[part 1 of 6: packages /MICROSAR/Dem_swc/DataTypes to /MICROSAR/Dem_swc/ComponentTypes]
AUTOSAR XML (schema 4-2-2)
package /MICROSAR/Dem_swc/DataTypes
  26 x impl type:
    Dem_EventIdType: range raw 1..65535, implementation-data-type=uint16
    Dem_RatioIdType: range raw 1..65535, implementation-data-type=uint16
    Dem_DTCStatusMaskType: range raw 0..255, implementation-data-type=uint8
    Dem_OperationCycleIdType: range raw 0..255, implementation-data-type=uint8
    Dem_DTCGroupType: range raw 0..16777215, implementation-data-type=uint32
    Dem_MaxDataValueType: category=ARRAY, sw-calibration-access=READ-ONLY
      element Dem_MaxDataValueTypeElement: array-size=8, array-size-semantics=FIXED-SIZE, implementation-data-type=uint8
    Dem_EventStatusType:
      compu {0=DEM_EVENT_STATUS_PASSED, 1=DEM_EVENT_STATUS_FAILED, 2=DEM_EVENT_STATUS_PREPASSED, 3=DEM_EVENT_STATUS_PREFAILED, 4=DEM_EVENT_STATUS_FDC_THRESHOLD_REACHED, 5=DEM_EVENT_STATUS_PASSED_CONDITIONS_NOT_FULFILLED, 6=DEM_EVENT_STATUS_FAILED_CONDITIONS_NOT_FULFILLED, 7=DEM_EVENT_STATUS_PREPASSED_CONDITIONS_NOT_FULFILLED, 8=DEM_EVENT_STATUS_PREFAILED_CONDITIONS_NOT_FULFILLED}
      range raw 0..255
      implementation-data-type=uint8
    Dem_DTCKindType: compu {1=DEM_DTC_KIND_ALL_DTCS, 2=DEM_DTC_KIND_EMISSION_REL_DTCS}, range raw 0..255, implementation-data-type=uint8
    Dem_IumprDenomCondStatusType: compu {0=DEM_IUMPR_DEN_STATUS_NOT_REACHED, 1=DEM_IUMPR_DEN_STATUS_REACHED, 2=DEM_IUMPR_DEN_STATUS_INHIBITED}, range raw 0..255, implementation-data-type=uint8
    Dem_DebounceResetStatusType: compu {0=DEM_DEBOUNCE_STATUS_FREEZE, 1=DEM_DEBOUNCE_STATUS_RESET}, range raw 0..255, implementation-data-type=uint8
    Dem_IumprReadinessGroupType:
      compu {0=DEM_IUMPR_BOOSTPRS, 1=DEM_IUMPR_CAT1, 2=DEM_IUMPR_CAT2, 3=DEM_IUMPR_EGR, 4=DEM_IUMPR_EGSENSOR, 5=DEM_IUMPR_EVAP, 6=DEM_IUMPR_NMHCCAT, 7=DEM_IUMPR_NOXADSORB, 8=DEM_IUMPR_NOXCAT, 9=DEM_IUMPR_OXS1, 10=DEM_IUMPR_OXS2, 11=DEM_IUMPR_PMFILTER, 12=DEM_IUMPR_PRIVATE, 13=DEM_IUMPR_SAIR, 14=DEM_IUMPR_SECOXS1, 15=DEM_IUMPR_SECOXS2, 16=DEM_IUMPR_FLSYS, 17=DEM_IUMPR_AFRI1, 18=DEM_IUMPR_AFRI2, 19=DEM_IUMPR_PF1, 20=DEM_IUMPR_PF2, 255=DEM_IUMPR_ALLGROUPS}
      range raw 0..255
      implementation-data-type=uint8
    Dem_DTRControlType: compu {0=DEM_DTR_CTL_NORMAL, 1=DEM_DTR_CTL_NO_MAX, 2=DEM_DTR_CTL_NO_MIN, 3=DEM_DTR_CTL_RESET, 4=DEM_DTR_CTL_INVISIBLE}, range raw 0..255, implementation-data-type=uint8
    Dem_DebouncingStateType:
      compu {mask 1: 1=DEM_TEMPORARILY_DEFECTIVE (Bit 0: Temporarily Defective (corresponds to 0 < FDC < 127)), mask 2: 2=DEM_FINALLY_DEFECTIVE (Bit 1: Finally Defective (corresponds to FDC = 127)), mask 4: 4=DEM_TEMPORARILY_HEALED (Bit 2: Temporarily healed (corresponds to -128 < FDC < 0)), mask 8: 8=DEM_TEST_COMPLETE (Bit 3: Test complete (corresponds to FDC = -128 or FDC = 127)), mask 16: 16=DEM_DTR_UPDATE (Bit 4: DTR Update (= Test complete && Debouncing complete && enable conditions / storage conditions fulfilled))}
      range raw 0..255
      implementation-data-type=uint8
    Dem_DTCSeverityType:
      compu {mask 255: 0=DEM_SEVERITY_NO_SEVERITY (DTC_NO_SEVERITY) (No severity information available), mask 31: 1=DEM_SEVERITY_WWHOBD_CLASS_NO_CLASS (DTC_CLASS) (No class information), mask 31: 2=DEM_SEVERITY_WWHOBD_CLASS_A (DTC_CLASS) (WWH-OBD Class A), mask 31: 4=DEM_SEVERITY_WWHOBD_CLASS_B1 (DTC_CLASS) (WWH-OBD Class B1), mask 31: 8=DEM_SEVERITY_WWHOBD_CLASS_B2 (DTC_CLASS) (WWH-OBD Class B2), mask 31: 16=DEM_SEVERITY_WWHOBD_CLASS_C (DTC_CLASS) (WWH-OBD Class C), mask 224: 32=DEM_SEVERITY_MAINTENANCE_ONLY (DTC_SEVERITY) (Maintenance required), mask 224: 64=DEM_SEVERITY_CHECK_AT_NEXT_HALT (DTC_SEVERITY) (Check at next halt), mask 224: 128=DEM_SEVERITY_CHECK_IMMEDIATELY (DTC_SEVERITY) (Check immediately)}
      range raw 0..255
      implementation-data-type=uint8
    Dem_UdsStatusByteType:
      compu {mask 1: 1=DEM_UDS_STATUS_TF (bit 0: TestFailed), mask 2: 2=DEM_UDS_STATUS_TFTOC (bit 1: TestFailedThisOperationCycle), mask 4: 4=DEM_UDS_STATUS_PDTC (bit 2: PendingDTC), mask 8: 8=DEM_UDS_STATUS_CDTC (bit 3: ConfirmedDTC), mask 16: 16=DEM_UDS_STATUS_TNCSLC (bit 4: TestNotCompletedSinceLastClear), mask 32: 32=DEM_UDS_STATUS_TFSLC (bit 5: TestFailedSinceLastClear), mask 64: 64=DEM_UDS_STATUS_TNCTOC (bit 6: TestNotCompletedThisOperationCycle), mask 128: 128=DEM_UDS_STATUS_WIR (bit 7: WarningIndicatorRequested)}
      range raw 0..255
      implementation-data-type=uint8
    Dem_MonitorStatusType: compu {mask 1: 1=DEM_MONITOR_STATUS_TF (bit 0: TestFailed), mask 2: 2=DEM_MONITOR_STATUS_TNCTOC (bit 1: TestNotCompletedThisOperationCycle)}, range raw 0..255, implementation-data-type=uint8
    DataArrayType_uint8_1: category=ARRAY, sw-calibration-access=READ-ONLY
      element DataArrayType_uint8_1Element: array-size=1, array-size-semantics=FIXED-SIZE, implementation-data-type=uint8
    DataArrayType_uint8_2: category=ARRAY, sw-calibration-access=READ-ONLY
      element DataArrayType_uint8_2Element: array-size=2, array-size-semantics=FIXED-SIZE, implementation-data-type=uint8
    DataArrayType_uint8_4: category=ARRAY, sw-calibration-access=READ-ONLY
      element DataArrayType_uint8_4Element: array-size=4, array-size-semantics=FIXED-SIZE, implementation-data-type=uint8
    DataArrayType_uint8_3: category=ARRAY, sw-calibration-access=READ-ONLY
      element DataArrayType_uint8_3Element: array-size=3, array-size-semantics=FIXED-SIZE, implementation-data-type=uint8
    Dem_InitMonitorReasonType: compu {1=DEM_INIT_MONITOR_CLEAR, 2=DEM_INIT_MONITOR_RESTART, 3=DEM_INIT_MONITOR_REENABLED, 4=DEM_INIT_MONITOR_STORAGE_REENABLED}, range raw 1..4, implementation-data-type=uint8
    Dem_DTCOriginType:
      compu {1=DEM_DTC_ORIGIN_PRIMARY_MEMORY, 2=DEM_DTC_ORIGIN_MIRROR_MEMORY, 3=DEM_DTC_ORIGIN_PERMANENT_MEMORY, 4=DEM_DTC_ORIGIN_OBD_RELEVANT_MEMORY, 5=DEM_DTC_ORIGIN_SECONDARY_MEMORY, 5=DEM_DTC_ORIGIN_USERDEFINED_MEMORY_10, 5=DEM_DTC_ORIGIN_USERDEFINED_MEMORY_11, 5=DEM_DTC_ORIGIN_USERDEFINED_MEMORY_12, 5=DEM_DTC_ORIGIN_USERDEFINED_MEMORY_13, 5=DEM_DTC_ORIGIN_USERDEFINED_MEMORY_14, 5=DEM_DTC_ORIGIN_USERDEFINED_MEMORY_15, 5=DEM_DTC_ORIGIN_USERDEFINED_MEMORY_16, 5=DEM_DTC_ORIGIN_USERDEFINED_MEMORY_17, 5=DEM_DTC_ORIGIN_USERDEFINED_MEMORY_18, 5=DEM_DTC_ORIGIN_USERDEFINED_MEMORY_19, 5=DEM_DTC_ORIGIN_USERDEFINED_MEMORY_1A, 5=DEM_DTC_ORIGIN_USERDEFINED_MEMORY_1B, 5=DEM_DTC_ORIGIN_USERDEFINED_MEMORY_1C, 5=DEM_DTC_ORIGIN_USERDEFINED_MEMORY_1D, 5=DEM_DTC_ORIGIN_USERDEFINED_MEMORY_1E, 5=DEM_DTC_ORIGIN_USERDEFINED_MEMORY_1F, 5=DEM_DTC_ORIGIN_USERDEFINED_MEMORY_20, 5=DEM_DTC_ORIGIN_USERDEFINED_MEMORY_21, 5=DEM_DTC_ORIGIN_USERDEFINED_MEMORY_22, 5=DEM_DTC_ORIGIN_USERDEFINED_MEMORY_23, 5=DEM_DTC_ORIGIN_USERDEFINED_MEMORY_24, 5=DEM_DTC_ORIGIN_USERDEFINED_MEMORY_25, 5=DEM_DTC_ORIGIN_USERDEFINED_MEMORY_26, 5=DEM_DTC_ORIGIN_USERDEFINED_MEMORY_27, 5=DEM_DTC_ORIGIN_USERDEFINED_MEMORY_28, 5=DEM_DTC_ORIGIN_USERDEFINED_MEMORY_29, 5=DEM_DTC_ORIGIN_USERDEFINED_MEMORY_2A, 5=DEM_DTC_ORIGIN_USERDEFINED_MEMORY_2B, 5=DEM_DTC_ORIGIN_USERDEFINED_MEMORY_2C, 5=DEM_DTC_ORIGIN_USERDEFINED_MEMORY_2D, 5=DEM_DTC_ORIGIN_USERDEFINED_MEMORY_2E, 5=DEM_DTC_ORIGIN_USERDEFINED_MEMORY_2F, 5=DEM_DTC_ORIGIN_USERDEFINED_MEMORY_30, 5=DEM_DTC_ORIGIN_USERDEFINED_MEMORY_31, 5=DEM_DTC_ORIGIN_USERDEFINED_MEMORY_32, 5=DEM_DTC_ORIGIN_USERDEFINED_MEMORY_33, 5=DEM_DTC_ORIGIN_USERDEFINED_MEMORY_34, 5=DEM_DTC_ORIGIN_USERDEFINED_MEMORY_35, 5=DEM_DTC_ORIGIN_USERDEFINED_MEMORY_36, 5=DEM_DTC_ORIGIN_USERDEFINED_MEMORY_37, 5=DEM_DTC_ORIGIN_USERDEFINED_MEMORY_38, 5=DEM_DTC_ORIGIN_USERDEFINED_MEMORY_39, 5=DEM_DTC_ORIGIN_USERDEFINED_MEMORY_3A, 5=DEM_DTC_ORIGIN_USERDEFINED_MEMORY_3B, 5=DEM_DTC_ORIGIN_USERDEFINED_MEMORY_3C, 5=DEM_DTC_ORIGIN_USERDEFINED_MEMORY_3D, 5=DEM_DTC_ORIGIN_USERDEFINED_MEMORY_3E, 5=DEM_DTC_ORIGIN_USERDEFINED_MEMORY_3F, 5=DEM_DTC_ORIGIN_USERDEFINED_MEMORY_40, 5=DEM_DTC_ORIGIN_USERDEFINED_MEMORY_41, 5=DEM_DTC_ORIGIN_USERDEFINED_MEMORY_42, 5=DEM_DTC_ORIGIN_USERDEFINED_MEMORY_43, 5=DEM_DTC_ORIGIN_USERDEFINED_MEMORY_44, 5=DEM_DTC_ORIGIN_USERDEFINED_MEMORY_45, 5=DEM_DTC_ORIGIN_USERDEFINED_MEMORY_46, 5=DEM_DTC_ORIGIN_USERDEFINED_MEMORY_47, 5=DEM_DTC_ORIGIN_USERDEFINED_MEMORY_48, 5=DEM_DTC_ORIGIN_USERDEFINED_MEMORY_49, 5=DEM_DTC_ORIGIN_USERDEFINED_MEMORY_4A, 5=DEM_DTC_ORIGIN_USERDEFINED_MEMORY_4B, 5=DEM_DTC_ORIGIN_USERDEFINED_MEMORY_4C, 5=DEM_DTC_ORIGIN_USERDEFINED_MEMORY_4D, 5=DEM_DTC_ORIGIN_USERDEFINED_MEMORY_4E, 5=DEM_DTC_ORIGIN_USERDEFINED_MEMORY_4F, 5=DEM_DTC_ORIGIN_USERDEFINED_MEMORY_50, 5=DEM_DTC_ORIGIN_USERDEFINED_MEMORY_51, 5=DEM_DTC_ORIGIN_USERDEFINED_MEMORY_52, 5=DEM_DTC_ORIGIN_USERDEFINED_MEMORY_53, 5=DEM_DTC_ORIGIN_USERDEFINED_MEMORY_54, 5=DEM_DTC_ORIGIN_USERDEFINED_MEMORY_55, 5=DEM_DTC_ORIGIN_USERDEFINED_MEMORY_56, 5=DEM_DTC_ORIGIN_USERDEFINED_MEMORY_57, 5=DEM_DTC_ORIGIN_USERDEFINED_MEMORY_58, 5=DEM_DTC_ORIGIN_USERDEFINED_MEMORY_59, 5=DEM_DTC_ORIGIN_USERDEFINED_MEMORY_5A, 5=DEM_DTC_ORIGIN_USERDEFINED_MEMORY_5B, 5=DEM_DTC_ORIGIN_USERDEFINED_MEMORY_5C, 5=DEM_DTC_ORIGIN_USERDEFINED_MEMORY_5D, 5=DEM_DTC_ORIGIN_USERDEFINED_MEMORY_5E, 5=DEM_DTC_ORIGIN_USERDEFINED_MEMORY_5F, 5=DEM_DTC_ORIGIN_USERDEFINED_MEMORY_60, 5=DEM_DTC_ORIGIN_USERDEFINED_MEMORY_61, 5=DEM_DTC_ORIGIN_USERDEFINED_MEMORY_62, 5=DEM_DTC_ORIGIN_USERDEFINED_MEMORY_63, 5=DEM_DTC_ORIGIN_USERDEFINED_MEMORY_64, 5=DEM_DTC_ORIGIN_USERDEFINED_MEMORY_65, 5=DEM_DTC_ORIGIN_USERDEFINED_MEMORY_66, 5=DEM_DTC_ORIGIN_USERDEFINED_MEMORY_67, 5=DEM_DTC_ORIGIN_USERDEFINED_MEMORY_68, 5=DEM_DTC_ORIGIN_USERDEFINED_MEMORY_69, 5=DEM_DTC_ORIGIN_USERDEFINED_MEMORY_6A, 5=DEM_DTC_ORIGIN_USERDEFINED_MEMORY_6B, 5=DEM_DTC_ORIGIN_USERDEFINED_MEMORY_6C, 5=DEM_DTC_ORIGIN_USERDEFINED_MEMORY_6D, 5=DEM_DTC_ORIGIN_USERDEFINED_MEMORY_6E, 5=DEM_DTC_ORIGIN_USERDEFINED_MEMORY_6F, 5=DEM_DTC_ORIGIN_USERDEFINED_MEMORY_70, 5=DEM_DTC_ORIGIN_USERDEFINED_MEMORY_71, 5=DEM_DTC_ORIGIN_USERDEFINED_MEMORY_72, 5=DEM_DTC_ORIGIN_USERDEFINED_MEMORY_73, 5=DEM_DTC_ORIGIN_USERDEFINED_MEMORY_74, 5=DEM_DTC_ORIGIN_USERDEFINED_MEMORY_75, 5=DEM_DTC_ORIGIN_USERDEFINED_MEMORY_76, 5=DEM_DTC_ORIGIN_USERDEFINED_MEMORY_77, 5=DEM_DTC_ORIGIN_USERDEFINED_MEMORY_78, 5=DEM_DTC_ORIGIN_USERDEFINED_MEMORY_79, 5=DEM_DTC_ORIGIN_USERDEFINED_MEMORY_7A, 5=DEM_DTC_ORIGIN_USERDEFINED_MEMORY_7B, 5=DEM_DTC_ORIGIN_USERDEFINED_MEMORY_7C, 5=DEM_DTC_ORIGIN_USERDEFINED_MEMORY_7D, 5=DEM_DTC_ORIGIN_USERDEFINED_MEMORY_7E, 5=DEM_DTC_ORIGIN_USERDEFINED_MEMORY_7F, 5=DEM_DTC_ORIGIN_USERDEFINED_MEMORY_80, 5=DEM_DTC_ORIGIN_USERDEFINED_MEMORY_81, 5=DEM_DTC_ORIGIN_USERDEFINED_MEMORY_82, 5=DEM_DTC_ORIGIN_USERDEFINED_MEMORY_83, 5=DEM_DTC_ORIGIN_USERDEFINED_MEMORY_84, 5=DEM_DTC_ORIGIN_USERDEFINED_MEMORY_85, 5=DEM_DTC_ORIGIN_USERDEFINED_MEMORY_86, 5=DEM_DTC_ORIGIN_USERDEFINED_MEMORY_87, 5=DEM_DTC_ORIGIN_USERDEFINED_MEMORY_88, 5=DEM_DTC_ORIGIN_USERDEFINED_MEMORY_89, 5=DEM_DTC_ORIGIN_USERDEFINED_MEMORY_8A, 5=DEM_DTC_ORIGIN_USERDEFINED_MEMORY_8B, 5=DEM_DTC_ORIGIN_USERDEFINED_MEMORY_8C, 5=DEM_DTC_ORIGIN_USERDEFINED_MEMORY_8D, 5=DEM_DTC_ORIGIN_USERDEFINED_MEMORY_8E, 5=DEM_DTC_ORIGIN_USERDEFINED_MEMORY_8F, 5=DEM_DTC_ORIGIN_USERDEFINED_MEMORY_90, 5=DEM_DTC_ORIGIN_USERDEFINED_MEMORY_91, 5=DEM_DTC_ORIGIN_USERDEFINED_MEMORY_92, 5=DEM_DTC_ORIGIN_USERDEFINED_MEMORY_93, 5=DEM_DTC_ORIGIN_USERDEFINED_MEMORY_94, 5=DEM_DTC_ORIGIN_USERDEFINED_MEMORY_95, 5=DEM_DTC_ORIGIN_USERDEFINED_MEMORY_96, 5=DEM_DTC_ORIGIN_USERDEFINED_MEMORY_97, 5=DEM_DTC_ORIGIN_USERDEFINED_MEMORY_98, 5=DEM_DTC_ORIGIN_USERDEFINED_MEMORY_99, 5=DEM_DTC_ORIGIN_USERDEFINED_MEMORY_9A, 5=DEM_DTC_ORIGIN_USERDEFINED_MEMORY_9B, 5=DEM_DTC_ORIGIN_USERDEFINED_MEMORY_9C, 5=DEM_DTC_ORIGIN_USERDEFINED_MEMORY_9D, 5=DEM_DTC_ORIGIN_USERDEFINED_MEMORY_9E, 5=DEM_DTC_ORIGIN_USERDEFINED_MEMORY_9F, 5=DEM_DTC_ORIGIN_USERDEFINED_MEMORY_A0, 5=DEM_DTC_ORIGIN_USERDEFINED_MEMORY_A1, 5=DEM_DTC_ORIGIN_USERDEFINED_MEMORY_A2, 5=DEM_DTC_ORIGIN_USERDEFINED_MEMORY_A3, 5=DEM_DTC_ORIGIN_USERDEFINED_MEMORY_A4, 5=DEM_DTC_ORIGIN_USERDEFINED_MEMORY_A5, 5=DEM_DTC_ORIGIN_USERDEFINED_MEMORY_A6, 5=DEM_DTC_ORIGIN_USERDEFINED_MEMORY_A7, 5=DEM_DTC_ORIGIN_USERDEFINED_MEMORY_A8, 5=DEM_DTC_ORIGIN_USERDEFINED_MEMORY_A9, 5=DEM_DTC_ORIGIN_USERDEFINED_MEMORY_AA, 5=DEM_DTC_ORIGIN_USERDEFINED_MEMORY_AB, 5=DEM_DTC_ORIGIN_USERDEFINED_MEMORY_AC, 5=DEM_DTC_ORIGIN_USERDEFINED_MEMORY_AD, 5=DEM_DTC_ORIGIN_USERDEFINED_MEMORY_AE, 5=DEM_DTC_ORIGIN_USERDEFINED_MEMORY_AF, 5=DEM_DTC_ORIGIN_USERDEFINED_MEMORY_B0, 5=DEM_DTC_ORIGIN_USERDEFINED_MEMORY_B1, 5=DEM_DTC_ORIGIN_USERDEFINED_MEMORY_B2, 5=DEM_DTC_ORIGIN_USERDEFINED_MEMORY_B3, 5=DEM_DTC_ORIGIN_USERDEFINED_MEMORY_B4, 5=DEM_DTC_ORIGIN_USERDEFINED_MEMORY_B5, 5=DEM_DTC_ORIGIN_USERDEFINED_MEMORY_B6, 5=DEM_DTC_ORIGIN_USERDEFINED_MEMORY_B7, 5=DEM_DTC_ORIGIN_USERDEFINED_MEMORY_B8, 5=DEM_DTC_ORIGIN_USERDEFINED_MEMORY_B9, 5=DEM_DTC_ORIGIN_USERDEFINED_MEMORY_BA, 5=DEM_DTC_ORIGIN_USERDEFINED_MEMORY_BB, 5=DEM_DTC_ORIGIN_USERDEFINED_MEMORY_BC, 5=DEM_DTC_ORIGIN_USERDEFINED_MEMORY_BD, 5=DEM_DTC_ORIGIN_USERDEFINED_MEMORY_BE, 5=DEM_DTC_ORIGIN_USERDEFINED_MEMORY_BF, 5=DEM_DTC_ORIGIN_USERDEFINED_MEMORY_C0, 5=DEM_DTC_ORIGIN_USERDEFINED_MEMORY_C1, 5=DEM_DTC_ORIGIN_USERDEFINED_MEMORY_C2, 5=DEM_DTC_ORIGIN_USERDEFINED_MEMORY_C3, 5=DEM_DTC_ORIGIN_USERDEFINED_MEMORY_C4, 5=DEM_DTC_ORIGIN_USERDEFINED_MEMORY_C5, 5=DEM_DTC_ORIGIN_USERDEFINED_MEMORY_C6, 5=DEM_DTC_ORIGIN_USERDEFINED_MEMORY_C7, 5=DEM_DTC_ORIGIN_USERDEFINED_MEMORY_C8, 5=DEM_DTC_ORIGIN_USERDEFINED_MEMORY_C9, 5=DEM_DTC_ORIGIN_USERDEFINED_MEMORY_CA, 5=DEM_DTC_ORIGIN_USERDEFINED_MEMORY_CB, 5=DEM_DTC_ORIGIN_USERDEFINED_MEMORY_CC, 5=DEM_DTC_ORIGIN_USERDEFINED_MEMORY_CD, 5=DEM_DTC_ORIGIN_USERDEFINED_MEMORY_CE, 5=DEM_DTC_ORIGIN_USERDEFINED_MEMORY_CF, 5=DEM_DTC_ORIGIN_USERDEFINED_MEMORY_D0, 5=DEM_DTC_ORIGIN_USERDEFINED_MEMORY_D1, 5=DEM_DTC_ORIGIN_USERDEFINED_MEMORY_D2, 5=DEM_DTC_ORIGIN_USERDEFINED_MEMORY_D3, 5=DEM_DTC_ORIGIN_USERDEFINED_MEMORY_D4, 5=DEM_DTC_ORIGIN_USERDEFINED_MEMORY_D5, 5=DEM_DTC_ORIGIN_USERDEFINED_MEMORY_D6, 5=DEM_DTC_ORIGIN_USERDEFINED_MEMORY_D7, 5=DEM_DTC_ORIGIN_USERDEFINED_MEMORY_D8, 5=DEM_DTC_ORIGIN_USERDEFINED_MEMORY_D9, 5=DEM_DTC_ORIGIN_USERDEFINED_MEMORY_DA, 5=DEM_DTC_ORIGIN_USERDEFINED_MEMORY_DB, 5=DEM_DTC_ORIGIN_USERDEFINED_MEMORY_DC, 5=DEM_DTC_ORIGIN_USERDEFINED_MEMORY_DD, 5=DEM_DTC_ORIGIN_USERDEFINED_MEMORY_DE, 5=DEM_DTC_ORIGIN_USERDEFINED_MEMORY_DF, 5=DEM_DTC_ORIGIN_USERDEFINED_MEMORY_E0, 5=DEM_DTC_ORIGIN_USERDEFINED_MEMORY_E1, 5=DEM_DTC_ORIGIN_USERDEFINED_MEMORY_E2, 5=DEM_DTC_ORIGIN_USERDEFINED_MEMORY_E3, 5=DEM_DTC_ORIGIN_USERDEFINED_MEMORY_E4, 5=DEM_DTC_ORIGIN_USERDEFINED_MEMORY_E5, 5=DEM_DTC_ORIGIN_USERDEFINED_MEMORY_E6, 5=DEM_DTC_ORIGIN_USERDEFINED_MEMORY_E7, 5=DEM_DTC_ORIGIN_USERDEFINED_MEMORY_E8, 5=DEM_DTC_ORIGIN_USERDEFINED_MEMORY_E9, 5=DEM_DTC_ORIGIN_USERDEFINED_MEMORY_EA, 5=DEM_DTC_ORIGIN_USERDEFINED_MEMORY_EB, 5=DEM_DTC_ORIGIN_USERDEFINED_MEMORY_EC, 5=DEM_DTC_ORIGIN_USERDEFINED_MEMORY_ED, 5=DEM_DTC_ORIGIN_USERDEFINED_MEMORY_EE, 5=DEM_DTC_ORIGIN_USERDEFINED_MEMORY_EF, 5=DEM_DTC_ORIGIN_USERDEFINED_MEMORY_F0, 5=DEM_DTC_ORIGIN_USERDEFINED_MEMORY_F1, 5=DEM_DTC_ORIGIN_USERDEFINED_MEMORY_F2, 5=DEM_DTC_ORIGIN_USERDEFINED_MEMORY_F3, 5=DEM_DTC_ORIGIN_USERDEFINED_MEMORY_F4, 5=DEM_DTC_ORIGIN_USERDEFINED_MEMORY_F5, 5=DEM_DTC_ORIGIN_USERDEFINED_MEMORY_F6, 5=DEM_DTC_ORIGIN_USERDEFINED_MEMORY_F7, 5=DEM_DTC_ORIGIN_USERDEFINED_MEMORY_F8, 5=DEM_DTC_ORIGIN_USERDEFINED_MEMORY_F9, 5=DEM_DTC_ORIGIN_USERDEFINED_MEMORY_FA, 5=DEM_DTC_ORIGIN_USERDEFINED_MEMORY_FB, 5=DEM_DTC_ORIGIN_USERDEFINED_MEMORY_FC, 5=DEM_DTC_ORIGIN_USERDEFINED_MEMORY_FD, 5=DEM_DTC_ORIGIN_USERDEFINED_MEMORY_FE, 5=DEM_DTC_ORIGIN_USERDEFINED_MEMORY_FF}
      range raw 1..511
      implementation-data-type=uint16
    Dem_DTCFormatType: compu {0=DEM_DTC_FORMAT_OBD, 1=DEM_DTC_FORMAT_UDS, 2=DEM_DTC_FORMAT_J1939}, range raw 0..2, implementation-data-type=uint8
    Dem_OperationCycleStateType: compu {0=DEM_CYCLE_STATE_START, 1=DEM_CYCLE_STATE_END}, range raw 0..1, implementation-data-type=uint8
    Dem_IndicatorStatusType: compu {0=DEM_INDICATOR_OFF, 1=DEM_INDICATOR_CONTINUOUS, 2=DEM_INDICATOR_BLINKING, 3=DEM_INDICATOR_BLINK_CONT, 4=DEM_INDICATOR_SLOW_FLASH, 5=DEM_INDICATOR_FAST_FLASH, 6=DEM_INDICATOR_ON_DEMAND, 7=DEM_INDICATOR_SHORT}, range raw 0..7, implementation-data-type=uint8
    Dem_IumprDenomCondIdType: compu {1=DEM_IUMPR_GENERAL_DENOMINATOR, 2=DEM_IUMPR_DEN_COND_COLDSTART, 3=DEM_IUMPR_DEN_COND_EVAP, 4=DEM_IUMPR_DEN_COND_500MI, 5=DEM_IUMPR_GENERAL_INDIVIDUAL_DENOMINATOR, 6=DEM_IUMPR_GENERAL_OBDCOND, 7=DEM_IUMPR_DEN_COND_INDEPENDENT}, range raw 0..255, implementation-data-type=uint8
package /MICROSAR/Dem_swc/Interfaces
  83 x client server interface, all with is-service=true, service-kind=DIAGNOSTIC-EVENT-MANAGER:
    DemServices
      operation GetPostRunRequested: possible-error=DemServices/E_NOT_OK
        arg IsRequested: type=boolean, direction=OUT
      operation GetDTCStatusAvailabilityMask: possible-error=DemServices/E_NOT_OK
        arg ClientId: type=uint8, direction=IN
        arg DTCStatusMask: type=uint8, direction=OUT
      error E_NOT_OK: error-code=1
    CallbackInitMonitorForEvent
      operation InitMonitorForEvent: possible-error=CallbackInitMonitorForEvent/E_NOT_OK
        arg InitMonitorReason: type=Dem_InitMonitorReasonType, direction=IN
      error E_NOT_OK: error-code=1
    ClearDTC
      operation ClearDTC: possible-error=[ClearDTC/E_NOT_OK, DEM_CLEAR_FAILED, DEM_PENDING, DEM_CLEAR_BUSY, DEM_CLEAR_MEMORY_ERROR, DEM_WRONG_DTC, DEM_WRONG_DTCORIGIN]
      operation SelectDTC: possible-error=[ClearDTC/E_OK, ClearDTC/E_NOT_OK]
        arg DTC: type=uint32, direction=IN
        arg DTCFormat: type=Dem_DTCFormatType, direction=IN
        arg DTCOrigin: type=Dem_DTCOriginType, direction=IN
      8 x error:
        E_OK: error-code=0
        E_NOT_OK: error-code=1
        DEM_CLEAR_FAILED: error-code=7
        DEM_PENDING: error-code=4
        DEM_CLEAR_BUSY: error-code=5
        DEM_CLEAR_MEMORY_ERROR: error-code=6
        DEM_WRONG_DTC: error-code=8
        DEM_WRONG_DTCORIGIN: error-code=9
    EnableCondition
      operation SetEnableCondition: possible-error=EnableCondition/E_NOT_OK
        arg ConditionFulfilled: type=boolean, direction=IN
      error E_NOT_OK: error-code=1
    IndicatorStatus
      operation GetIndicatorStatus: possible-error=IndicatorStatus/E_NOT_OK
        arg IndicatorStatus: type=Dem_IndicatorStatusType, direction=OUT
      error E_NOT_OK: error-code=1
    EvMemOverflowIndication
      operation GetEventMemoryOverflow: possible-error=EvMemOverflowIndication/E_NOT_OK
        arg OverflowIndication: type=boolean, direction=OUT
      operation GetNumberOfEventMemoryEntries: possible-error=EvMemOverflowIndication/E_NOT_OK
        arg NumberOfEventMemoryEntries: type=uint8, direction=OUT
      error E_NOT_OK: error-code=1
    GeneralDiagnosticInfo
      11 x operation:
        GetEventUdsStatus: possible-error=GeneralDiagnosticInfo/E_NOT_OK
          arg EventId: type=Dem_EventIdType, direction=IN
          arg UDSStatusByte: type=Dem_UdsStatusByteType, direction=OUT
        GetEventStatus: possible-error=GeneralDiagnosticInfo/E_NOT_OK
          arg EventId: type=Dem_EventIdType, direction=IN
          arg UDSStatusByte: type=Dem_UdsStatusByteType, direction=OUT
        GetEventFailed: possible-error=GeneralDiagnosticInfo/E_NOT_OK
          arg EventId: type=Dem_EventIdType, direction=IN
          arg EventFailed: type=boolean, direction=OUT
        GetEventTested: possible-error=GeneralDiagnosticInfo/E_NOT_OK
          arg EventId: type=Dem_EventIdType, direction=IN
          arg EventTested: type=boolean, direction=OUT
        GetDTCOfEvent: possible-error=[GeneralDiagnosticInfo/E_NOT_OK, GeneralDiagnosticInfo/DEM_E_NO_DTC_AVAILABLE]
          arg EventId: type=Dem_EventIdType, direction=IN
          arg DTCFormat: type=Dem_DTCFormatType, direction=IN
          arg DTCOfEvent: type=uint32, direction=OUT
        GetFaultDetectionCounter: possible-error=[GeneralDiagnosticInfo/E_NOT_OK, GeneralDiagnosticInfo/DEM_E_NO_FDC_AVAILABLE]
          arg EventId: type=Dem_EventIdType, direction=IN
          arg FaultDetectionCounter: type=sint8, direction=OUT
        GetEventFreezeFrameDataEx: possible-error=[GeneralDiagnosticInfo/E_NOT_OK, GeneralDiagnosticInfo/DEM_BUFFER_TOO_SMALL, GeneralDiagnosticInfo/DEM_NO_SUCH_ELEMENT]
          5 x arg:
            EventId: type=Dem_EventIdType, direction=IN
            RecordNumber: type=uint8, direction=IN
            DataId: type=uint16, direction=IN
            DestBuffer: type=Dem_MaxDataValueType, direction=OUT
            BufSize: type=uint16, direction=INOUT
        GetEventExtendedDataRecordEx: possible-error=[GeneralDiagnosticInfo/E_NOT_OK, GeneralDiagnosticInfo/DEM_BUFFER_TOO_SMALL, GeneralDiagnosticInfo/DEM_NO_SUCH_ELEMENT]
          4 x arg:
            EventId: type=Dem_EventIdType, direction=IN
            RecordNumber: type=uint8, direction=IN
            DestBuffer: type=Dem_MaxDataValueType, direction=OUT
            BufSize: type=uint16, direction=INOUT
        GetEventEnableCondition: possible-error=GeneralDiagnosticInfo/E_NOT_OK
          arg EventId: type=Dem_EventIdType, direction=IN
          arg ConditionFullfilled: type=boolean, direction=OUT
        GetDebouncingOfEvent: possible-error=GeneralDiagnosticInfo/E_NOT_OK
          arg EventId: type=Dem_EventIdType, direction=IN
          arg DebouncingState: type=Dem_DebouncingStateType, direction=OUT
        GetMonitorStatus: possible-error=GeneralDiagnosticInfo/E_NOT_OK
          arg EventId: type=Dem_EventIdType, direction=IN
          arg MonitorStatus: type=Dem_MonitorStatusType, direction=OUT
      5 x error:
        E_NOT_OK: error-code=1
        DEM_E_NO_DTC_AVAILABLE: error-code=10
        DEM_E_NO_FDC_AVAILABLE: error-code=14
        DEM_BUFFER_TOO_SMALL: error-code=21
        DEM_NO_SUCH_ELEMENT: error-code=48
    OperationCycle
      operation GetOperationCycleState: possible-error=[OperationCycle/E_OK, OperationCycle/E_NOT_OK]
        arg CycleState: type=Dem_OperationCycleStateType, direction=OUT
      operation SetOperationCycleState: possible-error=[OperationCycle/E_OK, OperationCycle/E_NOT_OK]
        arg CycleState: type=Dem_OperationCycleStateType, direction=IN
      error E_OK: error-code=0
      error E_NOT_OK: error-code=1
    CSDataServices_DTCStatusindicator30_DTCStatusindicator30
      operation ReadData: possible-error=CSDataServices_DTCStatusindicator30_DTCStatusindicator30/E_NOT_OK
        arg Data: type=DataArrayType_uint8_1, direction=OUT
      error E_NOT_OK: error-code=1
    CSDataServices_DID_0xe310_DID_E310_IEMMGM_Derating_Status
      operation ReadData: possible-error=CSDataServices_DID_0xe310_DID_E310_IEMMGM_Derating_Status/E_NOT_OK
        arg Data: type=DataArrayType_uint8_1, direction=OUT
      error E_NOT_OK: error-code=1
    CSDataServices_DID_0xe301_DID_E301_HVDC_Current_
      operation ReadData: possible-error=CSDataServices_DID_0xe301_DID_E301_HVDC_Current_/E_NOT_OK
        arg Data: type=DataArrayType_uint8_2, direction=OUT
      error E_NOT_OK: error-code=1
    CSDataServices_DID_0xe305_DID_E305_Inverter_IGBT_Junction_Temp
      operation ReadData: possible-error=CSDataServices_DID_0xe305_DID_E305_Inverter_IGBT_Junction_Temp/E_NOT_OK
        arg Data: type=DataArrayType_uint8_1, direction=OUT
      error E_NOT_OK: error-code=1
    CSDataServices_DID_0xe339_DID_E339_d_axis_voltage
      operation ReadData: possible-error=CSDataServices_DID_0xe339_DID_E339_d_axis_voltage/E_NOT_OK
        arg Data: type=DataArrayType_uint8_2, direction=OUT
      error E_NOT_OK: error-code=1
    CSDataServices_DID_0xe307_DID_E307_System_Mode
      operation ReadData: possible-error=CSDataServices_DID_0xe307_DID_E307_System_Mode/E_NOT_OK
        arg Data: type=DataArrayType_uint8_1, direction=OUT
      error E_NOT_OK: error-code=1
    CSDataServices_DID_0xe357_DID_E357_Resolve_compensated_angle
      operation ReadData: possible-error=CSDataServices_DID_0xe357_DID_E357_Resolve_compensated_angle/E_NOT_OK
        arg Data: type=DataArrayType_uint8_1, direction=OUT
      error E_NOT_OK: error-code=1
    CSDataServices_DID_0xe308_DID_E308_ECM_Torque_Request
      operation ReadData: possible-error=CSDataServices_DID_0xe308_DID_E308_ECM_Torque_Request/E_NOT_OK
        arg Data: type=DataArrayType_uint8_2, direction=OUT
      error E_NOT_OK: error-code=1
    CSDataServices_DID_0xe335_DID_E335_d_axis_current_setpoint
      operation ReadData: possible-error=CSDataServices_DID_0xe335_DID_E335_d_axis_current_setpoint/E_NOT_OK
        arg Data: type=DataArrayType_uint8_2, direction=OUT
      error E_NOT_OK: error-code=1
    CSDataServices_DID_0xe319_DID_E319_Torque_Direction
      operation ReadData: possible-error=CSDataServices_DID_0xe319_DID_E319_Torque_Direction/E_NOT_OK
        arg Data: type=DataArrayType_uint8_1, direction=OUT
      error E_NOT_OK: error-code=1
    CSDataServices_DID_0xe309_DID_E309_ECM_Mode_Request
      operation ReadData: possible-error=CSDataServices_DID_0xe309_DID_E309_ECM_Mode_Request/E_NOT_OK
        arg Data: type=DataArrayType_uint8_1, direction=OUT
      error E_NOT_OK: error-code=1
    CSDataServices_DID_0xdd0a_DID_DD0A_Usage_Mode
      operation ReadData: possible-error=CSDataServices_DID_0xdd0a_DID_DD0A_Usage_Mode/E_NOT_OK
        arg Data: type=DataArrayType_uint8_1, direction=OUT
      error E_NOT_OK: error-code=1
    CSDataServices_DID_0xeec3_DID_EEC3_ECU_power_supply_Voltage
      operation ReadData: possible-error=CSDataServices_DID_0xeec3_DID_EEC3_ECU_power_supply_Voltage/E_NOT_OK
        arg Data: type=DataArrayType_uint8_1, direction=OUT
      error E_NOT_OK: error-code=1
    CSDataServices_DID_0xdd00_DID_DD00_Global_Real_Time
      operation ReadData: possible-error=CSDataServices_DID_0xdd00_DID_DD00_Global_Real_Time/E_NOT_OK
        arg Data: type=DataArrayType_uint8_4, direction=OUT
      error E_NOT_OK: error-code=1
    CSDataServices_DID_0xee9e_DID_EE9E_Transient_Phase_Current_C
      operation ReadData: possible-error=CSDataServices_DID_0xee9e_DID_EE9E_Transient_Phase_Current_C/E_NOT_OK
        arg Data: type=DataArrayType_uint8_2, direction=OUT
      error E_NOT_OK: error-code=1
    CSDataServices_DID_0xe333_2002_Hu
      operation ReadData: possible-error=CSDataServices_DID_0xe333_2002_Hu/E_NOT_OK
        arg Data: type=DataArrayType_uint8_1, direction=OUT
      error E_NOT_OK: error-code=1
    CSDataServices_DID_0xe333_2002_Hw
      operation ReadData: possible-error=CSDataServices_DID_0xe333_2002_Hw/E_NOT_OK
        arg Data: type=DataArrayType_uint8_1, direction=OUT
      error E_NOT_OK: error-code=1
    CSDataServices_DID_0xe333_2002_Hv
      operation ReadData: possible-error=CSDataServices_DID_0xe333_2002_Hv/E_NOT_OK
        arg Data: type=DataArrayType_uint8_1, direction=OUT
      error E_NOT_OK: error-code=1
    CSDataServices_DID_0xe314_DID_E314_Available_Torque_maximum
      operation ReadData: possible-error=CSDataServices_DID_0xe314_DID_E314_Available_Torque_maximum/E_NOT_OK
        arg Data: type=DataArrayType_uint8_2, direction=OUT
      error E_NOT_OK: error-code=1
    CSDataServices_DID_0xeed4_DID_EED4_Safty_Function_Mode
      operation ReadData: possible-error=CSDataServices_DID_0xeed4_DID_EED4_Safty_Function_Mode/E_NOT_OK
        arg Data: type=DataArrayType_uint8_1, direction=OUT
      error E_NOT_OK: error-code=1
    CSDataServices_DID_0xd003_DID_D003_Vehicle_Speed
      operation ReadData: possible-error=CSDataServices_DID_0xd003_DID_D003_Vehicle_Speed/E_NOT_OK
        arg Data: type=DataArrayType_uint8_2, direction=OUT
      error E_NOT_OK: error-code=1
    CSDataServices_DID_0xe303_DID_E303_Motor_Speed_
      operation ReadData: possible-error=CSDataServices_DID_0xe303_DID_E303_Motor_Speed_/E_NOT_OK
        arg Data: type=DataArrayType_uint8_2, direction=OUT
      error E_NOT_OK: error-code=1
    CSDataServices_DID_0xe353_DID_E353_Flux_weakening_correction_factor
      operation ReadData: possible-error=CSDataServices_DID_0xe353_DID_E353_Flux_weakening_correction_factor/E_NOT_OK
        arg Data: type=DataArrayType_uint8_2, direction=OUT
      error E_NOT_OK: error-code=1
    CSDataServices_DID_0xe306_DID_E306_Motor_Temperature
      operation ReadData: possible-error=CSDataServices_DID_0xe306_DID_E306_Motor_Temperature/E_NOT_OK
        arg Data: type=DataArrayType_uint8_1, direction=OUT
      error E_NOT_OK: error-code=1
    CSDataServices_DID_0xe363_DID_E363_Modulation_index
      operation ReadData: possible-error=CSDataServices_DID_0xe363_DID_E363_Modulation_index/E_NOT_OK
        arg Data: type=DataArrayType_uint8_1, direction=OUT
      error E_NOT_OK: error-code=1
    CSDataServices_DID_0xe349_DID_E349_Phase_V_PWM_duty
      operation ReadData: possible-error=CSDataServices_DID_0xe349_DID_E349_Phase_V_PWM_duty/E_NOT_OK
        arg Data: type=DataArrayType_uint8_1, direction=OUT
      error E_NOT_OK: error-code=1
    CSDataServices_DID_0xdd02_DID_DD02_Vehicle_Battery_Voltage
      operation ReadData: possible-error=CSDataServices_DID_0xdd02_DID_DD02_Vehicle_Battery_Voltage/E_NOT_OK
        arg Data: type=DataArrayType_uint8_1, direction=OUT
      error E_NOT_OK: error-code=1
    CSDataServices_DTCTimeStamp21_DTCTimeStamp21
      operation ReadData: possible-error=CSDataServices_DTCTimeStamp21_DTCTimeStamp21/E_NOT_OK
        arg Data: type=DataArrayType_uint8_4, direction=OUT
      error E_NOT_OK: error-code=1
    CSDataServices_DID_0xe347_DID_E347_IGBT_Max_Temperature
      operation ReadData: possible-error=CSDataServices_DID_0xe347_DID_E347_IGBT_Max_Temperature/E_NOT_OK
        arg Data: type=DataArrayType_uint8_1, direction=OUT
      error E_NOT_OK: error-code=1
    CSDataServices_DID_0xeeb5_DID_EEB5_IEMMGM_current_torque
      operation ReadData: possible-error=CSDataServices_DID_0xeeb5_DID_EEB5_IEMMGM_current_torque/E_NOT_OK
        arg Data: type=DataArrayType_uint8_2, direction=OUT
      error E_NOT_OK: error-code=1
    CSDataServices_DID_0xeebe_DID_EEBE_Offset_angle_status
      operation ReadData: possible-error=CSDataServices_DID_0xeebe_DID_EEBE_Offset_angle_status/E_NOT_OK
        arg Data: type=DataArrayType_uint8_1, direction=OUT
      error E_NOT_OK: error-code=1
    CSDataServices_DID_0xe338_DID_E338_q_axis_current_feedback
      operation ReadData: possible-error=CSDataServices_DID_0xe338_DID_E338_q_axis_current_feedback/E_NOT_OK
        arg Data: type=DataArrayType_uint8_2, direction=OUT
      error E_NOT_OK: error-code=1
    CSDataServices_DID_0xee9d_DID_EE9D_Transient_Phase_Current_B
      operation ReadData: possible-error=CSDataServices_DID_0xee9d_DID_EE9D_Transient_Phase_Current_B/E_NOT_OK
        arg Data: type=DataArrayType_uint8_2, direction=OUT
      error E_NOT_OK: error-code=1
    CSDataServices_DID_0xe336_DID_E336_d_axis_current_feedback
      operation ReadData: possible-error=CSDataServices_DID_0xe336_DID_E336_d_axis_current_feedback/E_NOT_OK
        arg Data: type=DataArrayType_uint8_2, direction=OUT
      error E_NOT_OK: error-code=1
    CSDataServices_DID_0xe348_DID_E348_Phase_U_PWM_duty
      operation ReadData: possible-error=CSDataServices_DID_0xe348_DID_E348_Phase_U_PWM_duty/E_NOT_OK
        arg Data: type=DataArrayType_uint8_1, direction=OUT
      error E_NOT_OK: error-code=1
    CSDataServices_DID_0xe350_DID_E350_Phase_W_PWM_duty
      operation ReadData: possible-error=CSDataServices_DID_0xe350_DID_E350_Phase_W_PWM_duty/E_NOT_OK
        arg Data: type=DataArrayType_uint8_1, direction=OUT
      error E_NOT_OK: error-code=1
    CSDataServices_DTCTimeStamp20_DTCTimeStamp20
      operation ReadData: possible-error=CSDataServices_DTCTimeStamp20_DTCTimeStamp20/E_NOT_OK
        arg Data: type=DataArrayType_uint8_4, direction=OUT
      error E_NOT_OK: error-code=1
    CSDataServices_DID_0xe333_2002_H_Ser
      operation ReadData: possible-error=CSDataServices_DID_0xe333_2002_H_Ser/E_NOT_OK
        arg Data: type=DataArrayType_uint8_1, direction=OUT
      error E_NOT_OK: error-code=1
    CSDataServices_DID_0xeec4_DID_EEC4_Charging_Power_Sustain_RelayCPSR_Voltage
      operation ReadData: possible-error=CSDataServices_DID_0xeec4_DID_EEC4_Charging_Power_Sustain_RelayCPSR_Voltage/E_NOT_OK
        arg Data: type=DataArrayType_uint8_1, direction=OUT
      error E_NOT_OK: error-code=1
    CSDataServices_DID_0xe346_DID_E346_ECM_Torque_Allowed_Status
      operation ReadData: possible-error=CSDataServices_DID_0xe346_DID_E346_ECM_Torque_Allowed_Status/E_NOT_OK
        arg Data: type=DataArrayType_uint8_1, direction=OUT
      error E_NOT_OK: error-code=1
    CSDataServices_DID_0xe313_DID_E313_Active_discharge_status
      operation ReadData: possible-error=CSDataServices_DID_0xe313_DID_E313_Active_discharge_status/E_NOT_OK
        arg Data: type=DataArrayType_uint8_1, direction=OUT
      error E_NOT_OK: error-code=1
    CSDataServices_DID_0xe311_DID_E311_Crash_Status
      operation ReadData: possible-error=CSDataServices_DID_0xe311_DID_E311_Crash_Status/E_NOT_OK
        arg Data: type=DataArrayType_uint8_1, direction=OUT
      error E_NOT_OK: error-code=1
    CSDataServices_DID_0xe300_DID_E300_HVDC_Voltage
      operation ReadData: possible-error=CSDataServices_DID_0xe300_DID_E300_HVDC_Voltage/E_NOT_OK
        arg Data: type=DataArrayType_uint8_2, direction=OUT
      error E_NOT_OK: error-code=1
    CSDataServices_DID_0xe324_DID_E324_Motor_Derating_reason_of_IEMMGM
      operation ReadData: possible-error=CSDataServices_DID_0xe324_DID_E324_Motor_Derating_reason_of_IEMMGM/E_NOT_OK
        arg Data: type=DataArrayType_uint8_1, direction=OUT
      error E_NOT_OK: error-code=1
    CSDataServices_DID_0xee9f_DID_EE9F_Gate_Status
      operation ReadData: possible-error=CSDataServices_DID_0xee9f_DID_EE9F_Gate_Status/E_NOT_OK
        arg Data: type=DataArrayType_uint8_1, direction=OUT
      error E_NOT_OK: error-code=1
    CSDataServices_DID_0xe304_DID_E304_Actual_Torque
      operation ReadData: possible-error=CSDataServices_DID_0xe304_DID_E304_Actual_Torque/E_NOT_OK
        arg Data: type=DataArrayType_uint8_2, direction=OUT
      error E_NOT_OK: error-code=1
    CSDataServices_DID_0xe315_DID_E315_Available_Torque_minimum
      operation ReadData: possible-error=CSDataServices_DID_0xe315_DID_E315_Available_Torque_minimum/E_NOT_OK
        arg Data: type=DataArrayType_uint8_2, direction=OUT
      error E_NOT_OK: error-code=1
    CSDataServices_DID_0xeeb8_DID_EEB8_HV_voltage_received_from_BECM
      operation ReadData: possible-error=CSDataServices_DID_0xeeb8_DID_EEB8_HV_voltage_received_from_BECM/E_NOT_OK
        arg Data: type=DataArrayType_uint8_2, direction=OUT
      error E_NOT_OK: error-code=1
    CSDataServices_DID_0xeed5_EED5_Safety_Torque_Quality_factor
      operation ReadData: possible-error=CSDataServices_DID_0xeed5_EED5_Safety_Torque_Quality_factor/E_NOT_OK
        arg Data: type=DataArrayType_uint8_1, direction=OUT
      error E_NOT_OK: error-code=1
    CSDataServices_DID_0xe320_DID_E320_System_Mode_Mismatch
      operation ReadData: possible-error=CSDataServices_DID_0xe320_DID_E320_System_Mode_Mismatch/E_NOT_OK
        arg Data: type=DataArrayType_uint8_1, direction=OUT
      error E_NOT_OK: error-code=1
    CSDataServices_DID_0xeeb7_DID_EEB7_ECM_Power_Limitation_minimum
      operation ReadData: possible-error=CSDataServices_DID_0xeeb7_DID_EEB7_ECM_Power_Limitation_minimum/E_NOT_OK
        arg Data: type=DataArrayType_uint8_2, direction=OUT
      error E_NOT_OK: error-code=1
    CSDataServices_DID_0xe364_DID_E364_AURIX_Fault_Indication
      operation ReadData: possible-error=CSDataServices_DID_0xe364_DID_E364_AURIX_Fault_Indication/E_NOT_OK
        arg Data: type=DataArrayType_uint8_1, direction=OUT
      error E_NOT_OK: error-code=1
    CSDataServices_DID_0xeed1_EED1_1
      operation ReadData: possible-error=CSDataServices_DID_0xeed1_EED1_1/E_NOT_OK
        arg Data: type=DataArrayType_uint8_1, direction=OUT
      error E_NOT_OK: error-code=1
    CSDataServices_DID_0xeed1_EED1_0
      operation ReadData: possible-error=CSDataServices_DID_0xeed1_EED1_0/E_NOT_OK
        arg Data: type=DataArrayType_uint8_1, direction=OUT
      error E_NOT_OK: error-code=1
    CSDataServices_DID_0xeed1_EED1_3
      operation ReadData: possible-error=CSDataServices_DID_0xeed1_EED1_3/E_NOT_OK
        arg Data: type=DataArrayType_uint8_1, direction=OUT
      error E_NOT_OK: error-code=1
    CSDataServices_DID_0xeed1_EED1_2
      operation ReadData: possible-error=CSDataServices_DID_0xeed1_EED1_2/E_NOT_OK
        arg Data: type=DataArrayType_uint8_1, direction=OUT
      error E_NOT_OK: error-code=1
    CSDataServices_DID_0xe312_DID_E312_Wheel_Speed
      operation ReadData: possible-error=CSDataServices_DID_0xe312_DID_E312_Wheel_Speed/E_NOT_OK
        arg Data: type=DataArrayType_uint8_2, direction=OUT
      error E_NOT_OK: error-code=1
    CSDataServices_DID_0xe341_DID_E341_q_axis_voltage
      operation ReadData: possible-error=CSDataServices_DID_0xe341_DID_E341_q_axis_voltage/E_NOT_OK
        arg Data: type=DataArrayType_uint8_2, direction=OUT
      error E_NOT_OK: error-code=1
    CSDataServices_DID_0xeed3_DID_EED3_Safety_speed
      operation ReadData: possible-error=CSDataServices_DID_0xeed3_DID_EED3_Safety_speed/E_NOT_OK
        arg Data: type=DataArrayType_uint8_2, direction=OUT
      error E_NOT_OK: error-code=1
    CSDataServices_DID_0xee9c_DID_EE9C_Transient_Phase_Current_A
      operation ReadData: possible-error=CSDataServices_DID_0xee9c_DID_EE9C_Transient_Phase_Current_A/E_NOT_OK
        arg Data: type=DataArrayType_uint8_2, direction=OUT
      error E_NOT_OK: error-code=1
    CSDataServices_DID_0xeed2_DID_EED2_SaftyTorque
      operation ReadData: possible-error=CSDataServices_DID_0xeed2_DID_EED2_SaftyTorque/E_NOT_OK
        arg Data: type=DataArrayType_uint8_2, direction=OUT
      error E_NOT_OK: error-code=1
    CSDataServices_DID_0xdd01_DID_DD01_Total_Distance
      operation ReadData: possible-error=CSDataServices_DID_0xdd01_DID_DD01_Total_Distance/E_NOT_OK
        arg Data: type=DataArrayType_uint8_3, direction=OUT
      error E_NOT_OK: error-code=1
    CSDataServices_DID_0xeebf_DID_EEBF_HV_Main_Relay_Status
      operation ReadData: possible-error=CSDataServices_DID_0xeebf_DID_EEBF_HV_Main_Relay_Status/E_NOT_OK
        arg Data: type=DataArrayType_uint8_1, direction=OUT
      error E_NOT_OK: error-code=1
    CSDataServices_DID_0xe333_2002_L_Ser
      operation ReadData: possible-error=CSDataServices_DID_0xe333_2002_L_Ser/E_NOT_OK
        arg Data: type=DataArrayType_uint8_1, direction=OUT
      error E_NOT_OK: error-code=1
    CSDataServices_DID_0xeeb2_DID_EEB2_Three_Phase_Motor_Current_RMS_Current
      operation ReadData: possible-error=CSDataServices_DID_0xeeb2_DID_EEB2_Three_Phase_Motor_Current_RMS_Current/E_NOT_OK
        arg Data: type=DataArrayType_uint8_2, direction=OUT
      error E_NOT_OK: error-code=1
    CSDataServices_DID_0xe333_2002_Lw
      operation ReadData: possible-error=CSDataServices_DID_0xe333_2002_Lw/E_NOT_OK
        arg Data: type=DataArrayType_uint8_1, direction=OUT
      error E_NOT_OK: error-code=1
    CSDataServices_DID_0xe333_2002_Lv
      operation ReadData: possible-error=CSDataServices_DID_0xe333_2002_Lv/E_NOT_OK
        arg Data: type=DataArrayType_uint8_1, direction=OUT
      error E_NOT_OK: error-code=1
    CSDataServices_DID_0xee9a_DID_EE9A_Inverter_Coolant_Temperature
      operation ReadData: possible-error=CSDataServices_DID_0xee9a_DID_EE9A_Inverter_Coolant_Temperature/E_NOT_OK
        arg Data: type=DataArrayType_uint8_1, direction=OUT
      error E_NOT_OK: error-code=1
    CSDataServices_DID_0xdd0c_DID_DD0C_Electric_Power_Level
      operation ReadData: possible-error=CSDataServices_DID_0xdd0c_DID_DD0C_Electric_Power_Level/E_NOT_OK
        arg Data: type=DataArrayType_uint8_1, direction=OUT
      error E_NOT_OK: error-code=1
    CSDataServices_DID_0xe337_DID_E337_q_axis_current_setpoint
      operation ReadData: possible-error=CSDataServices_DID_0xe337_DID_E337_q_axis_current_setpoint/E_NOT_OK
        arg Data: type=DataArrayType_uint8_2, direction=OUT
      error E_NOT_OK: error-code=1
    CSDataServices_DID_0xeeb6_DID_EEB6_ECM_Power_Limitation_maximum
      operation ReadData: possible-error=CSDataServices_DID_0xeeb6_DID_EEB6_ECM_Power_Limitation_maximum/E_NOT_OK
        arg Data: type=DataArrayType_uint8_2, direction=OUT
      error E_NOT_OK: error-code=1
    CSDataServices_DID_0xe358_DID_E358_Resolve_angle
      operation ReadData: possible-error=CSDataServices_DID_0xe358_DID_E358_Resolve_angle/E_NOT_OK
        arg Data: type=DataArrayType_uint8_2, direction=OUT
      error E_NOT_OK: error-code=1
    CSDataServices_DID_0xe333_2002_Lu
      operation ReadData: possible-error=CSDataServices_DID_0xe333_2002_Lu/E_NOT_OK
        arg Data: type=DataArrayType_uint8_1, direction=OUT
      error E_NOT_OK: error-code=1
    DiagnosticInfo
      11 x operation:
        GetEventUdsStatus: possible-error=DiagnosticInfo/E_NOT_OK
          arg UDSStatusByte: type=Dem_UdsStatusByteType, direction=OUT
        GetEventStatus: possible-error=DiagnosticInfo/E_NOT_OK
          arg UDSStatusByte: type=Dem_UdsStatusByteType, direction=OUT
        GetEventFailed: possible-error=DiagnosticInfo/E_NOT_OK
          arg EventFailed: type=boolean, direction=OUT
        GetEventTested: possible-error=DiagnosticInfo/E_NOT_OK
          arg EventTested: type=boolean, direction=OUT
        GetDTCOfEvent: possible-error=[DiagnosticInfo/E_NOT_OK, DiagnosticInfo/DEM_E_NO_DTC_AVAILABLE]
          arg DTCFormat: type=Dem_DTCFormatType, direction=IN
          arg DTCOfEvent: type=uint32, direction=OUT
        GetFaultDetectionCounter: possible-error=[DiagnosticInfo/E_NOT_OK, DiagnosticInfo/DEM_E_NO_FDC_AVAILABLE]
          arg FaultDetectionCounter: type=sint8, direction=OUT
        GetEventFreezeFrameDataEx: possible-error=[DiagnosticInfo/E_NOT_OK, DiagnosticInfo/DEM_BUFFER_TOO_SMALL, DiagnosticInfo/DEM_NO_SUCH_ELEMENT]
          4 x arg:
            RecordNumber: type=uint8, direction=IN
            DataId: type=uint16, direction=IN
            DestBuffer: type=Dem_MaxDataValueType, direction=OUT
            BufSize: type=uint16, direction=INOUT
        GetEventExtendedDataRecordEx: possible-error=[DiagnosticInfo/E_NOT_OK, DiagnosticInfo/DEM_BUFFER_TOO_SMALL, DiagnosticInfo/DEM_NO_SUCH_ELEMENT]
          arg RecordNumber: type=uint8, direction=IN
          arg DestBuffer: type=Dem_MaxDataValueType, direction=OUT
          arg BufSize: type=uint16, direction=INOUT
        GetEventEnableCondition: possible-error=DiagnosticInfo/E_NOT_OK
          arg ConditionFullfilled: type=boolean, direction=OUT
        GetDebouncingOfEvent: possible-error=DiagnosticInfo/E_NOT_OK
          arg DebouncingState: type=Dem_DebouncingStateType, direction=OUT
        GetMonitorStatus: possible-error=DiagnosticInfo/E_NOT_OK
          arg MonitorStatus: type=Dem_MonitorStatusType, direction=OUT
      5 x error:
        E_NOT_OK: error-code=1
        DEM_E_NO_DTC_AVAILABLE: error-code=10
        DEM_E_NO_FDC_AVAILABLE: error-code=14
        DEM_BUFFER_TOO_SMALL: error-code=21
        DEM_NO_SUCH_ELEMENT: error-code=48
    DiagnosticMonitor
      11 x operation:
        SetEventStatus: possible-error=DiagnosticMonitor/E_NOT_OK
          arg EventStatus: type=Dem_EventStatusType, direction=IN
        ResetEventStatus: possible-error=DiagnosticMonitor/E_NOT_OK
        ResetEventDebounceStatus: possible-error=DiagnosticMonitor/E_NOT_OK
          arg DebounceResetStatus: type=Dem_DebounceResetStatusType, direction=IN
        GetEventUdsStatus: possible-error=DiagnosticMonitor/E_NOT_OK
          arg UDSStatusByte: type=Dem_UdsStatusByteType, direction=OUT
        GetEventStatus: possible-error=DiagnosticMonitor/E_NOT_OK
          arg UDSStatusByte: type=Dem_UdsStatusByteType, direction=OUT
        GetEventFailed: possible-error=DiagnosticMonitor/E_NOT_OK
          arg EventFailed: type=boolean, direction=OUT
        GetEventTested: possible-error=DiagnosticMonitor/E_NOT_OK
          arg EventTested: type=boolean, direction=OUT
        GetDTCOfEvent: possible-error=[DiagnosticMonitor/E_NOT_OK, DiagnosticMonitor/DEM_E_NO_DTC_AVAILABLE]
          arg DTCFormat: type=Dem_DTCFormatType, direction=IN
          arg DTCOfEvent: type=uint32, direction=OUT
        GetFaultDetectionCounter: possible-error=[DiagnosticMonitor/E_NOT_OK, DiagnosticMonitor/DEM_E_NO_FDC_AVAILABLE]
          arg FaultDetectionCounter: type=sint8, direction=OUT
        GetEventFreezeFrameDataEx: possible-error=[DiagnosticMonitor/E_NOT_OK, DiagnosticMonitor/DEM_BUFFER_TOO_SMALL, DiagnosticMonitor/DEM_NO_SUCH_ELEMENT]
          4 x arg:
            RecordNumber: type=uint8, direction=IN
            DataId: type=uint16, direction=IN
            DestBuffer: type=Dem_MaxDataValueType, direction=OUT
            BufSize: type=uint16, direction=INOUT
        GetEventExtendedDataRecordEx: possible-error=[DiagnosticMonitor/E_NOT_OK, DiagnosticMonitor/DEM_BUFFER_TOO_SMALL, DiagnosticMonitor/DEM_NO_SUCH_ELEMENT]
          arg RecordNumber: type=uint8, direction=IN
          arg DestBuffer: type=Dem_MaxDataValueType, direction=OUT
          arg BufSize: type=uint16, direction=INOUT
      5 x error:
        E_NOT_OK: error-code=1
        DEM_E_NO_DTC_AVAILABLE: error-code=10
        DEM_E_NO_FDC_AVAILABLE: error-code=14
        DEM_BUFFER_TOO_SMALL: error-code=21
        DEM_NO_SUCH_ELEMENT: error-code=48
package /MICROSAR/Dem_swc/ComponentTypes
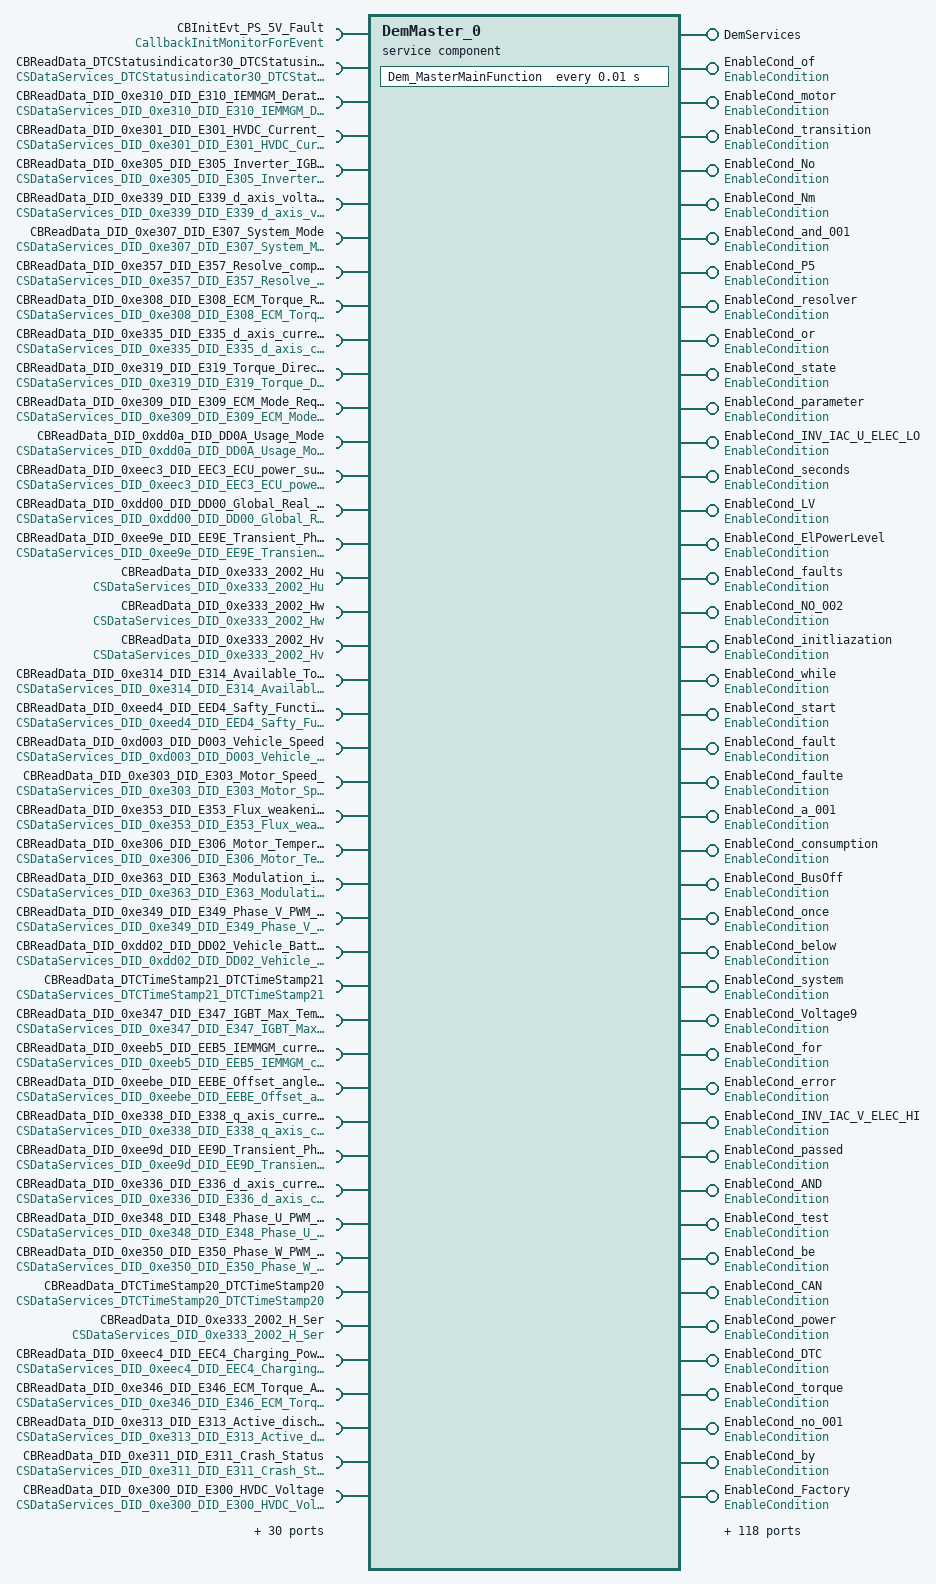
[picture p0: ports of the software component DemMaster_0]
  service sw component type DemMaster_0: category=SERVICE_COMPONENT
    provide port DemServices: provided-interface=DemServices
    require port CBInitEvt_PS_5V_Fault: required-interface=CallbackInitMonitorForEvent
    159 x provide port:
      EnableCond_of: provided-interface=EnableCondition
      EnableCond_motor: provided-interface=EnableCondition
      EnableCond_transition: provided-interface=EnableCondition
      EnableCond_No: provided-interface=EnableCondition
      EnableCond_Nm: provided-interface=EnableCondition
      EnableCond_and_001: provided-interface=EnableCondition
      EnableCond_P5: provided-interface=EnableCondition
      EnableCond_resolver: provided-interface=EnableCondition
      EnableCond_or: provided-interface=EnableCondition
      EnableCond_state: provided-interface=EnableCondition
      EnableCond_parameter: provided-interface=EnableCondition
      EnableCond_INV_IAC_U_ELEC_LO: provided-interface=EnableCondition
      EnableCond_seconds: provided-interface=EnableCondition
      EnableCond_LV: provided-interface=EnableCondition
      EnableCond_ElPowerLevel: provided-interface=EnableCondition
      EnableCond_faults: provided-interface=EnableCondition
      EnableCond_NO_002: provided-interface=EnableCondition
      EnableCond_initliazation: provided-interface=EnableCondition
      EnableCond_while: provided-interface=EnableCondition
      EnableCond_start: provided-interface=EnableCondition
      EnableCond_fault: provided-interface=EnableCondition
      EnableCond_faulte: provided-interface=EnableCondition
      EnableCond_a_001: provided-interface=EnableCondition
      EnableCond_consumption: provided-interface=EnableCondition
      EnableCond_BusOff: provided-interface=EnableCondition
      EnableCond_once: provided-interface=EnableCondition
      EnableCond_below: provided-interface=EnableCondition
      EnableCond_system: provided-interface=EnableCondition
      EnableCond_Voltage9: provided-interface=EnableCondition
      EnableCond_for: provided-interface=EnableCondition
      EnableCond_error: provided-interface=EnableCondition
      EnableCond_INV_IAC_V_ELEC_HI: provided-interface=EnableCondition
      EnableCond_passed: provided-interface=EnableCondition
      EnableCond_AND: provided-interface=EnableCondition
      EnableCond_test: provided-interface=EnableCondition
      EnableCond_be: provided-interface=EnableCondition
      EnableCond_CAN: provided-interface=EnableCondition
      EnableCond_power: provided-interface=EnableCondition
      EnableCond_DTC: provided-interface=EnableCondition
      EnableCond_torque: provided-interface=EnableCondition
      EnableCond_no_001: provided-interface=EnableCondition
      EnableCond_by: provided-interface=EnableCondition
      EnableCond_Factory: provided-interface=EnableCondition
      EnableCond_Crash: provided-interface=EnableCondition
      EnableCond_shall: provided-interface=EnableCondition
      EnableCond_vehicle: provided-interface=EnableCondition
      EnableCond_range: provided-interface=EnableCondition
      EnableCond_all: provided-interface=EnableCondition
      EnableCond_Inverter: provided-interface=EnableCondition
      EnableCond_Car_001: provided-interface=EnableCondition
      EnableCond_Request: provided-interface=EnableCondition
      EnableCond_SPI: provided-interface=EnableCondition
      EnableCond_CU: provided-interface=EnableCondition
      EnableCond_change: provided-interface=EnableCondition
      EnableCond_INV_IAC_W_ELEC_LO: provided-interface=EnableCondition
      EnableCond_exceptions: provided-interface=EnableCondition
      EnableCond_to: provided-interface=EnableCondition
      EnableCond_ECU: provided-interface=EnableCondition
      EnableCond_PS: provided-interface=EnableCondition
      EnableCond_off: provided-interface=EnableCondition
      EnableCond_Bulk: provided-interface=EnableCondition
      EnableCond_availability: provided-interface=EnableCondition
      EnableCond_generic: provided-interface=EnableCondition
      EnableCond_with: provided-interface=EnableCondition
      EnableCond_modes: provided-interface=EnableCondition
      EnableCond_Driving: provided-interface=EnableCondition
      EnableCond_notational: provided-interface=EnableCondition
      EnableCond_All_001: provided-interface=EnableCondition
      EnableCond_Test_001: provided-interface=EnableCondition
      EnableCond_signal: provided-interface=EnableCondition
      EnableCond_time: provided-interface=EnableCondition
      EnableCond_operation: provided-interface=EnableCondition
      EnableCond_indicated: provided-interface=EnableCondition
      EnableCond_UsageMode: provided-interface=EnableCondition
      EnableCond_low: provided-interface=EnableCondition
      EnableCond_inhibited: provided-interface=EnableCondition
      EnableCond_as: provided-interface=EnableCondition
      EnableCond_at: provided-interface=EnableCondition
      EnableCond_INV_EM_STATOR_TEMP_RNG_LO: provided-interface=EnableCondition
      EnableCond_init: provided-interface=EnableCondition
      EnableCond_normallye: provided-interface=EnableCondition
      EnableCond_requested: provided-interface=EnableCondition
      EnableCond_current: provided-interface=EnableCondition
      EnableCond_exit: provided-interface=EnableCondition
      EnableCond_toruqe: provided-interface=EnableCondition
      EnableCond_work: provided-interface=EnableCondition
      EnableCond_configuration_001: provided-interface=EnableCondition
      EnableCond_according: provided-interface=EnableCondition
      EnableCond_electrical: provided-interface=EnableCondition
      EnableCond_INV_IAC_W_ELEC_HI: provided-interface=EnableCondition
      EnableCond_KL15: provided-interface=EnableCondition
      EnableCond_Every: provided-interface=EnableCondition
      EnableCond_rpm: provided-interface=EnableCondition
      EnableCond_any: provided-interface=EnableCondition
      EnableCond_runs: provided-interface=EnableCondition
      EnableCond_When: provided-interface=EnableCondition
      EnableCond_car: provided-interface=EnableCondition
      EnableCond_not_001: provided-interface=EnableCondition
      EnableCond_phase: provided-interface=EnableCondition
      EnableCond_active: provided-interface=EnableCondition
      EnableCond_normally: provided-interface=EnableCondition
      EnableCond_enters: provided-interface=EnableCondition
      EnableCond_KL30: provided-interface=EnableCondition
      EnableCond_INV_EM_STATOR_TEMP_RNG_HI: provided-interface=EnableCondition
      EnableCond_Configuration: provided-interface=EnableCondition
      EnableCond_Prop: provided-interface=EnableCondition
      EnableCond_inhibition: provided-interface=EnableCondition
      EnableCond_criteria: provided-interface=EnableCondition
      EnableCond_global: provided-interface=EnableCondition
      EnableCond_CU_temp: provided-interface=EnableCondition
      EnableCond_done: provided-interface=EnableCondition
      EnableCond_Not: provided-interface=EnableCondition
      EnableCond_another: provided-interface=EnableCondition
      EnableCond_Ubat: provided-interface=EnableCondition
      EnableCond_received: provided-interface=EnableCondition
      EnableCond_tests: provided-interface=EnableCondition
      EnableCond_from: provided-interface=EnableCondition
      EnableCond_used: provided-interface=EnableCondition
      EnableCond_HVAC: provided-interface=EnableCondition
      EnableCond_high: provided-interface=EnableCondition
      EnableCond_mode: provided-interface=EnableCondition
      EnableCond_that: provided-interface=EnableCondition
      EnableCond_run: provided-interface=EnableCondition
      EnableCond_discharge: provided-interface=EnableCondition
      EnableCond_until: provided-interface=EnableCondition
      EnableCond_during: provided-interface=EnableCondition
      EnableCond_SpdAct: provided-interface=EnableCondition
      EnableCond_INV_IAC_U_ELEC_HI: provided-interface=EnableCondition
      EnableCond_Enabled: provided-interface=EnableCondition
      EnableCond_bus: provided-interface=EnableCondition
      EnableCond_A: provided-interface=EnableCondition
      EnableCond_temp: provided-interface=EnableCondition
      EnableCond_E: provided-interface=EnableCondition
      EnableCond_abs: provided-interface=EnableCondition
      EnableCond_block: provided-interface=EnableCondition
      EnableCond_The_001: provided-interface=EnableCondition
      EnableCond_P15: provided-interface=EnableCondition
      EnableCond_the: provided-interface=EnableCondition
      EnableCond_limited: provided-interface=EnableCondition
      EnableCond_fulfilled: provided-interface=EnableCondition
      EnableCond_one: provided-interface=EnableCondition
      EnableCond_set: provided-interface=EnableCondition
      EnableCond_control: provided-interface=EnableCondition
      EnableCond_V: provided-interface=EnableCondition
      EnableCond_Transport: provided-interface=EnableCondition
      EnableCond_in: provided-interface=EnableCondition
      EnableCond_when_001: provided-interface=EnableCondition
      EnableCond_ASC: provided-interface=EnableCondition
      EnableCond_offset: provided-interface=EnableCondition
      EnableCond_IGBT: provided-interface=EnableCondition
      EnableCond_is: provided-interface=EnableCondition
      EnableCond_each: provided-interface=EnableCondition
      EnableCond_s: provided-interface=EnableCondition
      EnableCond_sensor: provided-interface=EnableCondition
      EnableCond_INV_IAC_V_ELEC_LO: provided-interface=EnableCondition
      IndStatus_WarningIndicator: provided-interface=IndicatorStatus
      GeneralEvtInfo: provided-interface=GeneralDiagnosticInfo
      OpCycle_IgnitionCycle: provided-interface=OperationCycle
      OpCycle_PowerCycle: provided-interface=OperationCycle
    73 x require port:
      CBReadData_DTCStatusindicator30_DTCStatusindicator30: required-interface=CSDataServices_DTCStatusindicator30_DTCStatusindicator30
      CBReadData_DID_0xe310_DID_E310_IEMMGM_Derating_Status: required-interface=CSDataServices_DID_0xe310_DID_E310_IEMMGM_Derating_Status
      CBReadData_DID_0xe301_DID_E301_HVDC_Current_: required-interface=CSDataServices_DID_0xe301_DID_E301_HVDC_Current_
      CBReadData_DID_0xe305_DID_E305_Inverter_IGBT_Junction_Temp: required-interface=CSDataServices_DID_0xe305_DID_E305_Inverter_IGBT_Junction_Temp
      CBReadData_DID_0xe339_DID_E339_d_axis_voltage: required-interface=CSDataServices_DID_0xe339_DID_E339_d_axis_voltage
      CBReadData_DID_0xe307_DID_E307_System_Mode: required-interface=CSDataServices_DID_0xe307_DID_E307_System_Mode
      CBReadData_DID_0xe357_DID_E357_Resolve_compensated_angle: required-interface=CSDataServices_DID_0xe357_DID_E357_Resolve_compensated_angle
      CBReadData_DID_0xe308_DID_E308_ECM_Torque_Request: required-interface=CSDataServices_DID_0xe308_DID_E308_ECM_Torque_Request
      CBReadData_DID_0xe335_DID_E335_d_axis_current_setpoint: required-interface=CSDataServices_DID_0xe335_DID_E335_d_axis_current_setpoint
      CBReadData_DID_0xe319_DID_E319_Torque_Direction: required-interface=CSDataServices_DID_0xe319_DID_E319_Torque_Direction
      CBReadData_DID_0xe309_DID_E309_ECM_Mode_Request: required-interface=CSDataServices_DID_0xe309_DID_E309_ECM_Mode_Request
      CBReadData_DID_0xdd0a_DID_DD0A_Usage_Mode: required-interface=CSDataServices_DID_0xdd0a_DID_DD0A_Usage_Mode
      CBReadData_DID_0xeec3_DID_EEC3_ECU_power_supply_Voltage: required-interface=CSDataServices_DID_0xeec3_DID_EEC3_ECU_power_supply_Voltage
      CBReadData_DID_0xdd00_DID_DD00_Global_Real_Time: required-interface=CSDataServices_DID_0xdd00_DID_DD00_Global_Real_Time
      CBReadData_DID_0xee9e_DID_EE9E_Transient_Phase_Current_C: required-interface=CSDataServices_DID_0xee9e_DID_EE9E_Transient_Phase_Current_C
      CBReadData_DID_0xe333_2002_Hu: required-interface=CSDataServices_DID_0xe333_2002_Hu
      CBReadData_DID_0xe333_2002_Hw: required-interface=CSDataServices_DID_0xe333_2002_Hw
      CBReadData_DID_0xe333_2002_Hv: required-interface=CSDataServices_DID_0xe333_2002_Hv
      CBReadData_DID_0xe314_DID_E314_Available_Torque_maximum: required-interface=CSDataServices_DID_0xe314_DID_E314_Available_Torque_maximum
      CBReadData_DID_0xeed4_DID_EED4_Safty_Function_Mode: required-interface=CSDataServices_DID_0xeed4_DID_EED4_Safty_Function_Mode
      CBReadData_DID_0xd003_DID_D003_Vehicle_Speed: required-interface=CSDataServices_DID_0xd003_DID_D003_Vehicle_Speed
      CBReadData_DID_0xe303_DID_E303_Motor_Speed_: required-interface=CSDataServices_DID_0xe303_DID_E303_Motor_Speed_
      CBReadData_DID_0xe353_DID_E353_Flux_weakening_correction_factor: required-interface=CSDataServices_DID_0xe353_DID_E353_Flux_weakening_correction_factor
      CBReadData_DID_0xe306_DID_E306_Motor_Temperature: required-interface=CSDataServices_DID_0xe306_DID_E306_Motor_Temperature
      CBReadData_DID_0xe363_DID_E363_Modulation_index: required-interface=CSDataServices_DID_0xe363_DID_E363_Modulation_index
      CBReadData_DID_0xe349_DID_E349_Phase_V_PWM_duty: required-interface=CSDataServices_DID_0xe349_DID_E349_Phase_V_PWM_duty
      CBReadData_DID_0xdd02_DID_DD02_Vehicle_Battery_Voltage: required-interface=CSDataServices_DID_0xdd02_DID_DD02_Vehicle_Battery_Voltage
      CBReadData_DTCTimeStamp21_DTCTimeStamp21: required-interface=CSDataServices_DTCTimeStamp21_DTCTimeStamp21
      CBReadData_DID_0xe347_DID_E347_IGBT_Max_Temperature: required-interface=CSDataServices_DID_0xe347_DID_E347_IGBT_Max_Temperature
      CBReadData_DID_0xeeb5_DID_EEB5_IEMMGM_current_torque: required-interface=CSDataServices_DID_0xeeb5_DID_EEB5_IEMMGM_current_torque
      CBReadData_DID_0xeebe_DID_EEBE_Offset_angle_status: required-interface=CSDataServices_DID_0xeebe_DID_EEBE_Offset_angle_status
      CBReadData_DID_0xe338_DID_E338_q_axis_current_feedback: required-interface=CSDataServices_DID_0xe338_DID_E338_q_axis_current_feedback
      CBReadData_DID_0xee9d_DID_EE9D_Transient_Phase_Current_B: required-interface=CSDataServices_DID_0xee9d_DID_EE9D_Transient_Phase_Current_B
      CBReadData_DID_0xe336_DID_E336_d_axis_current_feedback: required-interface=CSDataServices_DID_0xe336_DID_E336_d_axis_current_feedback
      CBReadData_DID_0xe348_DID_E348_Phase_U_PWM_duty: required-interface=CSDataServices_DID_0xe348_DID_E348_Phase_U_PWM_duty
      CBReadData_DID_0xe350_DID_E350_Phase_W_PWM_duty: required-interface=CSDataServices_DID_0xe350_DID_E350_Phase_W_PWM_duty
      CBReadData_DTCTimeStamp20_DTCTimeStamp20: required-interface=CSDataServices_DTCTimeStamp20_DTCTimeStamp20
      CBReadData_DID_0xe333_2002_H_Ser: required-interface=CSDataServices_DID_0xe333_2002_H_Ser
      CBReadData_DID_0xeec4_DID_EEC4_Charging_Power_Sustain_RelayCPSR_Voltage: required-interface=CSDataServices_DID_0xeec4_DID_EEC4_Charging_Power_Sustain_RelayCPSR_Voltage
      CBReadData_DID_0xe346_DID_E346_ECM_Torque_Allowed_Status: required-interface=CSDataServices_DID_0xe346_DID_E346_ECM_Torque_Allowed_Status
      CBReadData_DID_0xe313_DID_E313_Active_discharge_status: required-interface=CSDataServices_DID_0xe313_DID_E313_Active_discharge_status
      CBReadData_DID_0xe311_DID_E311_Crash_Status: required-interface=CSDataServices_DID_0xe311_DID_E311_Crash_Status
      CBReadData_DID_0xe300_DID_E300_HVDC_Voltage: required-interface=CSDataServices_DID_0xe300_DID_E300_HVDC_Voltage
      CBReadData_DID_0xe324_DID_E324_Motor_Derating_reason_of_IEMMGM: required-interface=CSDataServices_DID_0xe324_DID_E324_Motor_Derating_reason_of_IEMMGM
      CBReadData_DID_0xee9f_DID_EE9F_Gate_Status: required-interface=CSDataServices_DID_0xee9f_DID_EE9F_Gate_Status
      CBReadData_DID_0xe304_DID_E304_Actual_Torque: required-interface=CSDataServices_DID_0xe304_DID_E304_Actual_Torque
      CBReadData_DID_0xe315_DID_E315_Available_Torque_minimum: required-interface=CSDataServices_DID_0xe315_DID_E315_Available_Torque_minimum
      CBReadData_DID_0xeeb8_DID_EEB8_HV_voltage_received_from_BECM: required-interface=CSDataServices_DID_0xeeb8_DID_EEB8_HV_voltage_received_from_BECM
      CBReadData_DID_0xeed5_EED5_Safety_Torque_Quality_factor: required-interface=CSDataServices_DID_0xeed5_EED5_Safety_Torque_Quality_factor
      CBReadData_DID_0xe320_DID_E320_System_Mode_Mismatch: required-interface=CSDataServices_DID_0xe320_DID_E320_System_Mode_Mismatch
      CBReadData_DID_0xeeb7_DID_EEB7_ECM_Power_Limitation_minimum: required-interface=CSDataServices_DID_0xeeb7_DID_EEB7_ECM_Power_Limitation_minimum
      CBReadData_DID_0xe364_DID_E364_AURIX_Fault_Indication: required-interface=CSDataServices_DID_0xe364_DID_E364_AURIX_Fault_Indication
      CBReadData_DID_0xeed1_EED1_1: required-interface=CSDataServices_DID_0xeed1_EED1_1
      CBReadData_DID_0xeed1_EED1_0: required-interface=CSDataServices_DID_0xeed1_EED1_0
      CBReadData_DID_0xeed1_EED1_3: required-interface=CSDataServices_DID_0xeed1_EED1_3
      CBReadData_DID_0xeed1_EED1_2: required-interface=CSDataServices_DID_0xeed1_EED1_2
      CBReadData_DID_0xe312_DID_E312_Wheel_Speed: required-interface=CSDataServices_DID_0xe312_DID_E312_Wheel_Speed
      CBReadData_DID_0xe341_DID_E341_q_axis_voltage: required-interface=CSDataServices_DID_0xe341_DID_E341_q_axis_voltage
      CBReadData_DID_0xeed3_DID_EED3_Safety_speed: required-interface=CSDataServices_DID_0xeed3_DID_EED3_Safety_speed
      CBReadData_DID_0xee9c_DID_EE9C_Transient_Phase_Current_A: required-interface=CSDataServices_DID_0xee9c_DID_EE9C_Transient_Phase_Current_A
      CBReadData_DID_0xeed2_DID_EED2_SaftyTorque: required-interface=CSDataServices_DID_0xeed2_DID_EED2_SaftyTorque
      CBReadData_DID_0xdd01_DID_DD01_Total_Distance: required-interface=CSDataServices_DID_0xdd01_DID_DD01_Total_Distance
      CBReadData_DID_0xeebf_DID_EEBF_HV_Main_Relay_Status: required-interface=CSDataServices_DID_0xeebf_DID_EEBF_HV_Main_Relay_Status
      CBReadData_DID_0xe333_2002_L_Ser: required-interface=CSDataServices_DID_0xe333_2002_L_Ser
      CBReadData_DID_0xeeb2_DID_EEB2_Three_Phase_Motor_Current_RMS_Current: required-interface=CSDataServices_DID_0xeeb2_DID_EEB2_Three_Phase_Motor_Current_RMS_Current
      CBReadData_DID_0xe333_2002_Lw: required-interface=CSDataServices_DID_0xe333_2002_Lw
      CBReadData_DID_0xe333_2002_Lv: required-interface=CSDataServices_DID_0xe333_2002_Lv
      CBReadData_DID_0xee9a_DID_EE9A_Inverter_Coolant_Temperature: required-interface=CSDataServices_DID_0xee9a_DID_EE9A_Inverter_Coolant_Temperature
      CBReadData_DID_0xdd0c_DID_DD0C_Electric_Power_Level: required-interface=CSDataServices_DID_0xdd0c_DID_DD0C_Electric_Power_Level
      CBReadData_DID_0xe337_DID_E337_q_axis_current_setpoint: required-interface=CSDataServices_DID_0xe337_DID_E337_q_axis_current_setpoint
      CBReadData_DID_0xeeb6_DID_EEB6_ECM_Power_Limitation_maximum: required-interface=CSDataServices_DID_0xeeb6_DID_EEB6_ECM_Power_Limitation_maximum
      CBReadData_DID_0xe358_DID_E358_Resolve_angle: required-interface=CSDataServices_DID_0xe358_DID_E358_Resolve_angle
      CBReadData_DID_0xe333_2002_Lu: required-interface=CSDataServices_DID_0xe333_2002_Lu
    provide port ClearDTC_DemClient_Dcm: provided-interface=ClearDTC
    provide port OverflowIndPrimaryMemory_DemClient_Dcm: provided-interface=EvMemOverflowIndication
    behavior DemMaster_0InternalBehavior: handle-termination-and-restart=NO-SUPPORT, included-data-type-set=data-type=[Dem_EventIdType, Dem_RatioIdType, Dem_EventStatusType, Dem_UdsStatusByteType, Dem_DTCFormatType, Dem_InitMonitorReasonType, Dem_OperationCycleStateType, Dem_DTCStatusMaskType, Dem_IndicatorStatusType, Dem_MaxDataValueType, Dem_DTCKindType, Dem_DTCGroupType, Dem_IumprDenomCondIdType, Dem_IumprDenomCondStatusType, Dem_DebounceResetStatusType, Dem_DebouncingStateType, Dem_IumprReadinessGroupType, Dem_DTRControlType, Dem_DTCSeverityType, Dem_MonitorStatusType]
      timing event Timer_Dem_MasterMainFunction: start-on-event=Dem_MasterMainFunction, period=0.01
      177 x operation invoked event:
        OpEventPostRunRequested_GetPostRunRequested_DemServices: start-on-event=PostRunRequested, operation=DemServices.GetPostRunRequested
        OpEventGetDTCStatusAvailabilityMask_GetDTCStatusAvailabilityMask_DemServices: start-on-event=GetDTCStatusAvailabilityMask, operation=DemServices.GetDTCStatusAvailabilityMask
        OpEventSetEnableCondition_SetEnableCondition_EnableCond_of: start-on-event=SetEnableCondition, operation=EnableCond_of.SetEnableCondition
        OpEventSetEnableCondition_SetEnableCondition_EnableCond_motor: start-on-event=SetEnableCondition, operation=EnableCond_motor.SetEnableCondition
        OpEventSetEnableCondition_SetEnableCondition_EnableCond_transition: start-on-event=SetEnableCondition, operation=EnableCond_transition.SetEnableCondition
        OpEventSetEnableCondition_SetEnableCondition_EnableCond_No: start-on-event=SetEnableCondition, operation=EnableCond_No.SetEnableCondition
        OpEventSetEnableCondition_SetEnableCondition_EnableCond_Nm: start-on-event=SetEnableCondition, operation=EnableCond_Nm.SetEnableCondition
        OpEventSetEnableCondition_SetEnableCondition_EnableCond_and_001: start-on-event=SetEnableCondition, operation=EnableCond_and_001.SetEnableCondition
        OpEventSetEnableCondition_SetEnableCondition_EnableCond_P5: start-on-event=SetEnableCondition, operation=EnableCond_P5.SetEnableCondition
        OpEventSetEnableCondition_SetEnableCondition_EnableCond_resolver: start-on-event=SetEnableCondition, operation=EnableCond_resolver.SetEnableCondition
        OpEventSetEnableCondition_SetEnableCondition_EnableCond_or: start-on-event=SetEnableCondition, operation=EnableCond_or.SetEnableCondition
        OpEventSetEnableCondition_SetEnableCondition_EnableCond_state: start-on-event=SetEnableCondition, operation=EnableCond_state.SetEnableCondition
        OpEventSetEnableCondition_SetEnableCondition_EnableCond_parameter: start-on-event=SetEnableCondition, operation=EnableCond_parameter.SetEnableCondition
        OpEventSetEnableCondition_SetEnableCondition_EnableCond_INV_IAC_U_ELEC_LO: start-on-event=SetEnableCondition, operation=EnableCond_INV_IAC_U_ELEC_LO.SetEnableCondition
        OpEventSetEnableCondition_SetEnableCondition_EnableCond_seconds: start-on-event=SetEnableCondition, operation=EnableCond_seconds.SetEnableCondition
        OpEventSetEnableCondition_SetEnableCondition_EnableCond_LV: start-on-event=SetEnableCondition, operation=EnableCond_LV.SetEnableCondition
        OpEventSetEnableCondition_SetEnableCondition_EnableCond_ElPowerLevel: start-on-event=SetEnableCondition, operation=EnableCond_ElPowerLevel.SetEnableCondition
        OpEventSetEnableCondition_SetEnableCondition_EnableCond_faults: start-on-event=SetEnableCondition, operation=EnableCond_faults.SetEnableCondition
        OpEventSetEnableCondition_SetEnableCondition_EnableCond_NO_002: start-on-event=SetEnableCondition, operation=EnableCond_NO_002.SetEnableCondition
        OpEventSetEnableCondition_SetEnableCondition_EnableCond_initliazation: start-on-event=SetEnableCondition, operation=EnableCond_initliazation.SetEnableCondition
        OpEventSetEnableCondition_SetEnableCondition_EnableCond_while: start-on-event=SetEnableCondition, operation=EnableCond_while.SetEnableCondition
        OpEventSetEnableCondition_SetEnableCondition_EnableCond_start: start-on-event=SetEnableCondition, operation=EnableCond_start.SetEnableCondition
        OpEventSetEnableCondition_SetEnableCondition_EnableCond_fault: start-on-event=SetEnableCondition, operation=EnableCond_fault.SetEnableCondition
        OpEventSetEnableCondition_SetEnableCondition_EnableCond_faulte: start-on-event=SetEnableCondition, operation=EnableCond_faulte.SetEnableCondition
        OpEventSetEnableCondition_SetEnableCondition_EnableCond_a_001: start-on-event=SetEnableCondition, operation=EnableCond_a_001.SetEnableCondition
        OpEventSetEnableCondition_SetEnableCondition_EnableCond_consumption: start-on-event=SetEnableCondition, operation=EnableCond_consumption.SetEnableCondition
        OpEventSetEnableCondition_SetEnableCondition_EnableCond_BusOff: start-on-event=SetEnableCondition, operation=EnableCond_BusOff.SetEnableCondition
        OpEventSetEnableCondition_SetEnableCondition_EnableCond_once: start-on-event=SetEnableCondition, operation=EnableCond_once.SetEnableCondition
        OpEventSetEnableCondition_SetEnableCondition_EnableCond_below: start-on-event=SetEnableCondition, operation=EnableCond_below.SetEnableCondition
        OpEventSetEnableCondition_SetEnableCondition_EnableCond_system: start-on-event=SetEnableCondition, operation=EnableCond_system.SetEnableCondition
        OpEventSetEnableCondition_SetEnableCondition_EnableCond_Voltage9: start-on-event=SetEnableCondition, operation=EnableCond_Voltage9.SetEnableCondition
        OpEventSetEnableCondition_SetEnableCondition_EnableCond_for: start-on-event=SetEnableCondition, operation=EnableCond_for.SetEnableCondition
        OpEventSetEnableCondition_SetEnableCondition_EnableCond_error: start-on-event=SetEnableCondition, operation=EnableCond_error.SetEnableCondition
        OpEventSetEnableCondition_SetEnableCondition_EnableCond_INV_IAC_V_ELEC_HI: start-on-event=SetEnableCondition, operation=EnableCond_INV_IAC_V_ELEC_HI.SetEnableCondition
        OpEventSetEnableCondition_SetEnableCondition_EnableCond_passed: start-on-event=SetEnableCondition, operation=EnableCond_passed.SetEnableCondition
        OpEventSetEnableCondition_SetEnableCondition_EnableCond_AND: start-on-event=SetEnableCondition, operation=EnableCond_AND.SetEnableCondition
        OpEventSetEnableCondition_SetEnableCondition_EnableCond_test: start-on-event=SetEnableCondition, operation=EnableCond_test.SetEnableCondition
        OpEventSetEnableCondition_SetEnableCondition_EnableCond_be: start-on-event=SetEnableCondition, operation=EnableCond_be.SetEnableCondition
        OpEventSetEnableCondition_SetEnableCondition_EnableCond_CAN: start-on-event=SetEnableCondition, operation=EnableCond_CAN.SetEnableCondition
        OpEventSetEnableCondition_SetEnableCondition_EnableCond_power: start-on-event=SetEnableCondition, operation=EnableCond_power.SetEnableCondition
        OpEventSetEnableCondition_SetEnableCondition_EnableCond_DTC: start-on-event=SetEnableCondition, operation=EnableCond_DTC.SetEnableCondition
        OpEventSetEnableCondition_SetEnableCondition_EnableCond_torque: start-on-event=SetEnableCondition, operation=EnableCond_torque.SetEnableCondition
        OpEventSetEnableCondition_SetEnableCondition_EnableCond_no_001: start-on-event=SetEnableCondition, operation=EnableCond_no_001.SetEnableCondition
        OpEventSetEnableCondition_SetEnableCondition_EnableCond_by: start-on-event=SetEnableCondition, operation=EnableCond_by.SetEnableCondition
        OpEventSetEnableCondition_SetEnableCondition_EnableCond_Factory: start-on-event=SetEnableCondition, operation=EnableCond_Factory.SetEnableCondition
        OpEventSetEnableCondition_SetEnableCondition_EnableCond_Crash: start-on-event=SetEnableCondition, operation=EnableCond_Crash.SetEnableCondition
        OpEventSetEnableCondition_SetEnableCondition_EnableCond_shall: start-on-event=SetEnableCondition, operation=EnableCond_shall.SetEnableCondition
        OpEventSetEnableCondition_SetEnableCondition_EnableCond_vehicle: start-on-event=SetEnableCondition, operation=EnableCond_vehicle.SetEnableCondition
        OpEventSetEnableCondition_SetEnableCondition_EnableCond_range: start-on-event=SetEnableCondition, operation=EnableCond_range.SetEnableCondition
        OpEventSetEnableCondition_SetEnableCondition_EnableCond_all: start-on-event=SetEnableCondition, operation=EnableCond_all.SetEnableCondition
        OpEventSetEnableCondition_SetEnableCondition_EnableCond_Inverter: start-on-event=SetEnableCondition, operation=EnableCond_Inverter.SetEnableCondition
        OpEventSetEnableCondition_SetEnableCondition_EnableCond_Car_001: start-on-event=SetEnableCondition, operation=EnableCond_Car_001.SetEnableCondition
        OpEventSetEnableCondition_SetEnableCondition_EnableCond_Request: start-on-event=SetEnableCondition, operation=EnableCond_Request.SetEnableCondition
        OpEventSetEnableCondition_SetEnableCondition_EnableCond_SPI: start-on-event=SetEnableCondition, operation=EnableCond_SPI.SetEnableCondition
        OpEventSetEnableCondition_SetEnableCondition_EnableCond_CU: start-on-event=SetEnableCondition, operation=EnableCond_CU.SetEnableCondition
        OpEventSetEnableCondition_SetEnableCondition_EnableCond_change: start-on-event=SetEnableCondition, operation=EnableCond_change.SetEnableCondition
        OpEventSetEnableCondition_SetEnableCondition_EnableCond_INV_IAC_W_ELEC_LO: start-on-event=SetEnableCondition, operation=EnableCond_INV_IAC_W_ELEC_LO.SetEnableCondition
        OpEventSetEnableCondition_SetEnableCondition_EnableCond_exceptions: start-on-event=SetEnableCondition, operation=EnableCond_exceptions.SetEnableCondition
        OpEventSetEnableCondition_SetEnableCondition_EnableCond_to: start-on-event=SetEnableCondition, operation=EnableCond_to.SetEnableCondition
        OpEventSetEnableCondition_SetEnableCondition_EnableCond_ECU: start-on-event=SetEnableCondition, operation=EnableCond_ECU.SetEnableCondition
        OpEventSetEnableCondition_SetEnableCondition_EnableCond_PS: start-on-event=SetEnableCondition, operation=EnableCond_PS.SetEnableCondition
        OpEventSetEnableCondition_SetEnableCondition_EnableCond_off: start-on-event=SetEnableCondition, operation=EnableCond_off.SetEnableCondition
        OpEventSetEnableCondition_SetEnableCondition_EnableCond_Bulk: start-on-event=SetEnableCondition, operation=EnableCond_Bulk.SetEnableCondition
        OpEventSetEnableCondition_SetEnableCondition_EnableCond_availability: start-on-event=SetEnableCondition, operation=EnableCond_availability.SetEnableCondition
        OpEventSetEnableCondition_SetEnableCondition_EnableCond_generic: start-on-event=SetEnableCondition, operation=EnableCond_generic.SetEnableCondition
        OpEventSetEnableCondition_SetEnableCondition_EnableCond_with: start-on-event=SetEnableCondition, operation=EnableCond_with.SetEnableCondition
        OpEventSetEnableCondition_SetEnableCondition_EnableCond_modes: start-on-event=SetEnableCondition, operation=EnableCond_modes.SetEnableCondition
        OpEventSetEnableCondition_SetEnableCondition_EnableCond_Driving: start-on-event=SetEnableCondition, operation=EnableCond_Driving.SetEnableCondition
        OpEventSetEnableCondition_SetEnableCondition_EnableCond_notational: start-on-event=SetEnableCondition, operation=EnableCond_notational.SetEnableCondition
        OpEventSetEnableCondition_SetEnableCondition_EnableCond_All_001: start-on-event=SetEnableCondition, operation=EnableCond_All_001.SetEnableCondition
        OpEventSetEnableCondition_SetEnableCondition_EnableCond_Test_001: start-on-event=SetEnableCondition, operation=EnableCond_Test_001.SetEnableCondition
        OpEventSetEnableCondition_SetEnableCondition_EnableCond_signal: start-on-event=SetEnableCondition, operation=EnableCond_signal.SetEnableCondition
        OpEventSetEnableCondition_SetEnableCondition_EnableCond_time: start-on-event=SetEnableCondition, operation=EnableCond_time.SetEnableCondition
        OpEventSetEnableCondition_SetEnableCondition_EnableCond_operation: start-on-event=SetEnableCondition, operation=EnableCond_operation.SetEnableCondition
        OpEventSetEnableCondition_SetEnableCondition_EnableCond_indicated: start-on-event=SetEnableCondition, operation=EnableCond_indicated.SetEnableCondition
        OpEventSetEnableCondition_SetEnableCondition_EnableCond_UsageMode: start-on-event=SetEnableCondition, operation=EnableCond_UsageMode.SetEnableCondition
        OpEventSetEnableCondition_SetEnableCondition_EnableCond_low: start-on-event=SetEnableCondition, operation=EnableCond_low.SetEnableCondition
        OpEventSetEnableCondition_SetEnableCondition_EnableCond_inhibited: start-on-event=SetEnableCondition, operation=EnableCond_inhibited.SetEnableCondition
        OpEventSetEnableCondition_SetEnableCondition_EnableCond_as: start-on-event=SetEnableCondition, operation=EnableCond_as.SetEnableCondition
        OpEventSetEnableCondition_SetEnableCondition_EnableCond_at: start-on-event=SetEnableCondition, operation=EnableCond_at.SetEnableCondition
        OpEventSetEnableCondition_SetEnableCondition_EnableCond_INV_EM_STATOR_TEMP_RNG_LO: start-on-event=SetEnableCondition, operation=EnableCond_INV_EM_STATOR_TEMP_RNG_LO.SetEnableCondition
        OpEventSetEnableCondition_SetEnableCondition_EnableCond_init: start-on-event=SetEnableCondition, operation=EnableCond_init.SetEnableCondition
        OpEventSetEnableCondition_SetEnableCondition_EnableCond_normallye: start-on-event=SetEnableCondition, operation=EnableCond_normallye.SetEnableCondition
        OpEventSetEnableCondition_SetEnableCondition_EnableCond_requested: start-on-event=SetEnableCondition, operation=EnableCond_requested.SetEnableCondition
        OpEventSetEnableCondition_SetEnableCondition_EnableCond_current: start-on-event=SetEnableCondition, operation=EnableCond_current.SetEnableCondition
        OpEventSetEnableCondition_SetEnableCondition_EnableCond_exit: start-on-event=SetEnableCondition, operation=EnableCond_exit.SetEnableCondition
        OpEventSetEnableCondition_SetEnableCondition_EnableCond_toruqe: start-on-event=SetEnableCondition, operation=EnableCond_toruqe.SetEnableCondition
        OpEventSetEnableCondition_SetEnableCondition_EnableCond_work: start-on-event=SetEnableCondition, operation=EnableCond_work.SetEnableCondition
        OpEventSetEnableCondition_SetEnableCondition_EnableCond_configuration_001: start-on-event=SetEnableCondition, operation=EnableCond_configuration_001.SetEnableCondition
        OpEventSetEnableCondition_SetEnableCondition_EnableCond_according: start-on-event=SetEnableCondition, operation=EnableCond_according.SetEnableCondition
        OpEventSetEnableCondition_SetEnableCondition_EnableCond_electrical: start-on-event=SetEnableCondition, operation=EnableCond_electrical.SetEnableCondition
        OpEventSetEnableCondition_SetEnableCondition_EnableCond_INV_IAC_W_ELEC_HI: start-on-event=SetEnableCondition, operation=EnableCond_INV_IAC_W_ELEC_HI.SetEnableCondition
        OpEventSetEnableCondition_SetEnableCondition_EnableCond_KL15: start-on-event=SetEnableCondition, operation=EnableCond_KL15.SetEnableCondition
        OpEventSetEnableCondition_SetEnableCondition_EnableCond_Every: start-on-event=SetEnableCondition, operation=EnableCond_Every.SetEnableCondition
        OpEventSetEnableCondition_SetEnableCondition_EnableCond_rpm: start-on-event=SetEnableCondition, operation=EnableCond_rpm.SetEnableCondition
        OpEventSetEnableCondition_SetEnableCondition_EnableCond_any: start-on-event=SetEnableCondition, operation=EnableCond_any.SetEnableCondition
        OpEventSetEnableCondition_SetEnableCondition_EnableCond_runs: start-on-event=SetEnableCondition, operation=EnableCond_runs.SetEnableCondition
        OpEventSetEnableCondition_SetEnableCondition_EnableCond_When: start-on-event=SetEnableCondition, operation=EnableCond_When.SetEnableCondition
        OpEventSetEnableCondition_SetEnableCondition_EnableCond_car: start-on-event=SetEnableCondition, operation=EnableCond_car.SetEnableCondition
        OpEventSetEnableCondition_SetEnableCondition_EnableCond_not_001: start-on-event=SetEnableCondition, operation=EnableCond_not_001.SetEnableCondition
        OpEventSetEnableCondition_SetEnableCondition_EnableCond_phase: start-on-event=SetEnableCondition, operation=EnableCond_phase.SetEnableCondition
        OpEventSetEnableCondition_SetEnableCondition_EnableCond_active: start-on-event=SetEnableCondition, operation=EnableCond_active.SetEnableCondition
        OpEventSetEnableCondition_SetEnableCondition_EnableCond_normally: start-on-event=SetEnableCondition, operation=EnableCond_normally.SetEnableCondition
        OpEventSetEnableCondition_SetEnableCondition_EnableCond_enters: start-on-event=SetEnableCondition, operation=EnableCond_enters.SetEnableCondition
        OpEventSetEnableCondition_SetEnableCondition_EnableCond_KL30: start-on-event=SetEnableCondition, operation=EnableCond_KL30.SetEnableCondition
        OpEventSetEnableCondition_SetEnableCondition_EnableCond_INV_EM_STATOR_TEMP_RNG_HI: start-on-event=SetEnableCondition, operation=EnableCond_INV_EM_STATOR_TEMP_RNG_HI.SetEnableCondition
        OpEventSetEnableCondition_SetEnableCondition_EnableCond_Configuration: start-on-event=SetEnableCondition, operation=EnableCond_Configuration.SetEnableCondition
        OpEventSetEnableCondition_SetEnableCondition_EnableCond_Prop: start-on-event=SetEnableCondition, operation=EnableCond_Prop.SetEnableCondition
        OpEventSetEnableCondition_SetEnableCondition_EnableCond_inhibition: start-on-event=SetEnableCondition, operation=EnableCond_inhibition.SetEnableCondition
        OpEventSetEnableCondition_SetEnableCondition_EnableCond_criteria: start-on-event=SetEnableCondition, operation=EnableCond_criteria.SetEnableCondition
        OpEventSetEnableCondition_SetEnableCondition_EnableCond_global: start-on-event=SetEnableCondition, operation=EnableCond_global.SetEnableCondition
        OpEventSetEnableCondition_SetEnableCondition_EnableCond_CU_temp: start-on-event=SetEnableCondition, operation=EnableCond_CU_temp.SetEnableCondition
        OpEventSetEnableCondition_SetEnableCondition_EnableCond_done: start-on-event=SetEnableCondition, operation=EnableCond_done.SetEnableCondition
        OpEventSetEnableCondition_SetEnableCondition_EnableCond_Not: start-on-event=SetEnableCondition, operation=EnableCond_Not.SetEnableCondition
        OpEventSetEnableCondition_SetEnableCondition_EnableCond_another: start-on-event=SetEnableCondition, operation=EnableCond_another.SetEnableCondition
        OpEventSetEnableCondition_SetEnableCondition_EnableCond_Ubat: start-on-event=SetEnableCondition, operation=EnableCond_Ubat.SetEnableCondition
        OpEventSetEnableCondition_SetEnableCondition_EnableCond_received: start-on-event=SetEnableCondition, operation=EnableCond_received.SetEnableCondition
        OpEventSetEnableCondition_SetEnableCondition_EnableCond_tests: start-on-event=SetEnableCondition, operation=EnableCond_tests.SetEnableCondition
        OpEventSetEnableCondition_SetEnableCondition_EnableCond_from: start-on-event=SetEnableCondition, operation=EnableCond_from.SetEnableCondition
        OpEventSetEnableCondition_SetEnableCondition_EnableCond_used: start-on-event=SetEnableCondition, operation=EnableCond_used.SetEnableCondition
        OpEventSetEnableCondition_SetEnableCondition_EnableCond_HVAC: start-on-event=SetEnableCondition, operation=EnableCond_HVAC.SetEnableCondition
        OpEventSetEnableCondition_SetEnableCondition_EnableCond_high: start-on-event=SetEnableCondition, operation=EnableCond_high.SetEnableCondition
        OpEventSetEnableCondition_SetEnableCondition_EnableCond_mode: start-on-event=SetEnableCondition, operation=EnableCond_mode.SetEnableCondition
        OpEventSetEnableCondition_SetEnableCondition_EnableCond_that: start-on-event=SetEnableCondition, operation=EnableCond_that.SetEnableCondition
        OpEventSetEnableCondition_SetEnableCondition_EnableCond_run: start-on-event=SetEnableCondition, operation=EnableCond_run.SetEnableCondition
        OpEventSetEnableCondition_SetEnableCondition_EnableCond_discharge: start-on-event=SetEnableCondition, operation=EnableCond_discharge.SetEnableCondition
        OpEventSetEnableCondition_SetEnableCondition_EnableCond_until: start-on-event=SetEnableCondition, operation=EnableCond_until.SetEnableCondition
        OpEventSetEnableCondition_SetEnableCondition_EnableCond_during: start-on-event=SetEnableCondition, operation=EnableCond_during.SetEnableCondition
        OpEventSetEnableCondition_SetEnableCondition_EnableCond_SpdAct: start-on-event=SetEnableCondition, operation=EnableCond_SpdAct.SetEnableCondition
        OpEventSetEnableCondition_SetEnableCondition_EnableCond_INV_IAC_U_ELEC_HI: start-on-event=SetEnableCondition, operation=EnableCond_INV_IAC_U_ELEC_HI.SetEnableCondition
        OpEventSetEnableCondition_SetEnableCondition_EnableCond_Enabled: start-on-event=SetEnableCondition, operation=EnableCond_Enabled.SetEnableCondition
        OpEventSetEnableCondition_SetEnableCondition_EnableCond_bus: start-on-event=SetEnableCondition, operation=EnableCond_bus.SetEnableCondition
        OpEventSetEnableCondition_SetEnableCondition_EnableCond_A: start-on-event=SetEnableCondition, operation=EnableCond_A.SetEnableCondition
        OpEventSetEnableCondition_SetEnableCondition_EnableCond_temp: start-on-event=SetEnableCondition, operation=EnableCond_temp.SetEnableCondition
        OpEventSetEnableCondition_SetEnableCondition_EnableCond_E: start-on-event=SetEnableCondition, operation=EnableCond_E.SetEnableCondition
        OpEventSetEnableCondition_SetEnableCondition_EnableCond_abs: start-on-event=SetEnableCondition, operation=EnableCond_abs.SetEnableCondition
        OpEventSetEnableCondition_SetEnableCondition_EnableCond_block: start-on-event=SetEnableCondition, operation=EnableCond_block.SetEnableCondition
        OpEventSetEnableCondition_SetEnableCondition_EnableCond_The_001: start-on-event=SetEnableCondition, operation=EnableCond_The_001.SetEnableCondition
        OpEventSetEnableCondition_SetEnableCondition_EnableCond_P15: start-on-event=SetEnableCondition, operation=EnableCond_P15.SetEnableCondition
        OpEventSetEnableCondition_SetEnableCondition_EnableCond_the: start-on-event=SetEnableCondition, operation=EnableCond_the.SetEnableCondition
        OpEventSetEnableCondition_SetEnableCondition_EnableCond_limited: start-on-event=SetEnableCondition, operation=EnableCond_limited.SetEnableCondition
        OpEventSetEnableCondition_SetEnableCondition_EnableCond_fulfilled: start-on-event=SetEnableCondition, operation=EnableCond_fulfilled.SetEnableCondition
        OpEventSetEnableCondition_SetEnableCondition_EnableCond_one: start-on-event=SetEnableCondition, operation=EnableCond_one.SetEnableCondition
        OpEventSetEnableCondition_SetEnableCondition_EnableCond_set: start-on-event=SetEnableCondition, operation=EnableCond_set.SetEnableCondition
        OpEventSetEnableCondition_SetEnableCondition_EnableCond_control: start-on-event=SetEnableCondition, operation=EnableCond_control.SetEnableCondition
        OpEventSetEnableCondition_SetEnableCondition_EnableCond_V: start-on-event=SetEnableCondition, operation=EnableCond_V.SetEnableCondition
        OpEventSetEnableCondition_SetEnableCondition_EnableCond_Transport: start-on-event=SetEnableCondition, operation=EnableCond_Transport.SetEnableCondition
        OpEventSetEnableCondition_SetEnableCondition_EnableCond_in: start-on-event=SetEnableCondition, operation=EnableCond_in.SetEnableCondition
        OpEventSetEnableCondition_SetEnableCondition_EnableCond_when_001: start-on-event=SetEnableCondition, operation=EnableCond_when_001.SetEnableCondition
        OpEventSetEnableCondition_SetEnableCondition_EnableCond_ASC: start-on-event=SetEnableCondition, operation=EnableCond_ASC.SetEnableCondition
        OpEventSetEnableCondition_SetEnableCondition_EnableCond_offset: start-on-event=SetEnableCondition, operation=EnableCond_offset.SetEnableCondition
        OpEventSetEnableCondition_SetEnableCondition_EnableCond_IGBT: start-on-event=SetEnableCondition, operation=EnableCond_IGBT.SetEnableCondition
        OpEventSetEnableCondition_SetEnableCondition_EnableCond_is: start-on-event=SetEnableCondition, operation=EnableCond_is.SetEnableCondition
        OpEventSetEnableCondition_SetEnableCondition_EnableCond_each: start-on-event=SetEnableCondition, operation=EnableCond_each.SetEnableCondition
        OpEventSetEnableCondition_SetEnableCondition_EnableCond_s: start-on-event=SetEnableCondition, operation=EnableCond_s.SetEnableCondition
        OpEventSetEnableCondition_SetEnableCondition_EnableCond_sensor: start-on-event=SetEnableCondition, operation=EnableCond_sensor.SetEnableCondition
        OpEventSetEnableCondition_SetEnableCondition_EnableCond_INV_IAC_V_ELEC_LO: start-on-event=SetEnableCondition, operation=EnableCond_INV_IAC_V_ELEC_LO.SetEnableCondition
        OpEventGetIndicatorStatus_GetIndicatorStatus_IndStatus_WarningIndicator: start-on-event=GetIndicatorStatus, operation=IndStatus_WarningIndicator.GetIndicatorStatus
        OpEventGetEventUdsStatus_GetEventUdsStatus_GeneralEvtInfo: start-on-event=DemMaster_0InternalBehavior/GetEventUdsStatus, operation=GeneralEvtInfo.GetEventUdsStatus
        OpEventGetEventStatus_GetEventStatus_GeneralEvtInfo: start-on-event=DemMaster_0InternalBehavior/GetEventStatus, operation=GeneralEvtInfo.GetEventStatus
        OpEventGetEventFailed_GetEventFailed_GeneralEvtInfo: start-on-event=DemMaster_0InternalBehavior/GetEventFailed, operation=GeneralEvtInfo.GetEventFailed
        OpEventGetEventTested_GetEventTested_GeneralEvtInfo: start-on-event=DemMaster_0InternalBehavior/GetEventTested, operation=GeneralEvtInfo.GetEventTested
        OpEventGetDTCOfEvent_GetDTCOfEvent_GeneralEvtInfo: start-on-event=DemMaster_0InternalBehavior/GetDTCOfEvent, operation=GeneralEvtInfo.GetDTCOfEvent
        OpEventGetFaultDetectionCounter_GetFaultDetectionCounter_GeneralEvtInfo: start-on-event=DemMaster_0InternalBehavior/GetFaultDetectionCounter, operation=GeneralEvtInfo.GetFaultDetectionCounter
        OpEventGetEventFreezeFrameDataEx_GetEventFreezeFrameDataEx_GeneralEvtInfo: start-on-event=DemMaster_0InternalBehavior/GetEventFreezeFrameDataEx, operation=GeneralEvtInfo.GetEventFreezeFrameDataEx
        OpEventGetEventExtendedDataRecordEx_GetEventExtendedDataRecordEx_GeneralEvtInfo: start-on-event=DemMaster_0InternalBehavior/GetEventExtendedDataRecordEx, operation=GeneralEvtInfo.GetEventExtendedDataRecordEx
        OpEventGetEventEnableCondition_GetEventEnableCondition_GeneralEvtInfo: start-on-event=DemMaster_0InternalBehavior/GetEventEnableCondition, operation=GeneralEvtInfo.GetEventEnableCondition
        OpEventGetDebouncingOfEvent_GetDebouncingOfEvent_GeneralEvtInfo: start-on-event=DemMaster_0InternalBehavior/GetDebouncingOfEvent, operation=GeneralEvtInfo.GetDebouncingOfEvent
        OpEventGetMonitorStatus_GetMonitorStatus_GeneralEvtInfo: start-on-event=DemMaster_0InternalBehavior/GetMonitorStatus, operation=GeneralEvtInfo.GetMonitorStatus
        OpEventGetOperationCycleState_GetOperationCycleState_OpCycle_IgnitionCycle: start-on-event=GetOperationCycleState, operation=OpCycle_IgnitionCycle.GetOperationCycleState
        OpEventGetOperationCycleState_GetOperationCycleState_OpCycle_PowerCycle: start-on-event=GetOperationCycleState, operation=OpCycle_PowerCycle.GetOperationCycleState
        OpEventSetOperationCycleState_SetOperationCycleState_OpCycle_IgnitionCycle: start-on-event=SetOperationCycleState, operation=OpCycle_IgnitionCycle.SetOperationCycleState
        OpEventSetOperationCycleState_SetOperationCycleState_OpCycle_PowerCycle: start-on-event=SetOperationCycleState, operation=OpCycle_PowerCycle.SetOperationCycleState
        OpEventClearDTC_ClearDTC_ClearDTC_DemClient_Dcm: start-on-event=ClearDTC, operation=ClearDTC_DemClient_Dcm.ClearDTC
        OpEventSelectDTC_SelectDTC_ClearDTC_DemClient_Dcm: start-on-event=SelectDTC, operation=ClearDTC_DemClient_Dcm.SelectDTC
        OpEventGetEventMemoryOverflow_GetEventMemoryOverflow_OverflowIndPrimaryMemory_DemClient_Dcm: start-on-event=GetEventMemoryOverflow, operation=OverflowIndPrimaryMemory_DemClient_Dcm.GetEventMemoryOverflow
        OpEventGetNumberOfEventMemoryEntries_GetNumberOfEventMemoryEntries_OverflowIndPrimaryMemory_DemClient_Dcm: start-on-event=GetNumberOfEventMemoryEntries, operation=OverflowIndPrimaryMemory_DemClient_Dcm.GetNumberOfEventMemoryEntries
      port-api-options:
        enable-take-address=true, indirect-api=false, port=DemServices
        enable-take-address=true, indirect-api=false, port=CBInitEvt_PS_5V_Fault
        enable-take-address=true, indirect-api=false, port=DemMaster_0/GeneralEvtInfo
        {enable-take-address=true, indirect-api=false, port-defined-argument-value{value=112, value-type=uint8}, port=EnableCond_of}
        {enable-take-address=true, indirect-api=false, port-defined-argument-value{value=106, value-type=uint8}, port=EnableCond_motor}
        {enable-take-address=true, indirect-api=false, port-defined-argument-value{value=148, value-type=uint8}, port=EnableCond_transition}
        {enable-take-address=true, indirect-api=false, port-defined-argument-value{value=37, value-type=uint8}, port=EnableCond_No}
        {enable-take-address=true, indirect-api=false, port-defined-argument-value{value=36, value-type=uint8}, port=EnableCond_Nm}
        {enable-take-address=true, indirect-api=false, port-defined-argument-value{value=59, value-type=uint8}, port=EnableCond_and_001}
        {enable-take-address=true, indirect-api=false, port-defined-argument-value{value=39, value-type=uint8}, port=EnableCond_P5}
        {enable-take-address=true, indirect-api=false, port-defined-argument-value{value=126, value-type=uint8}, port=EnableCond_resolver}
        {enable-take-address=true, indirect-api=false, port-defined-argument-value{value=118, value-type=uint8}, port=EnableCond_or}
        {enable-take-address=true, indirect-api=false, port-defined-argument-value{value=137, value-type=uint8}, port=EnableCond_state}
        {enable-take-address=true, indirect-api=false, port-defined-argument-value{value=119, value-type=uint8}, port=EnableCond_parameter}
        {enable-take-address=true, indirect-api=false, port-defined-argument-value{value=26, value-type=uint8}, port=EnableCond_INV_IAC_U_ELEC_LO}
        {enable-take-address=true, indirect-api=false, port-defined-argument-value{value=131, value-type=uint8}, port=EnableCond_seconds}
        {enable-take-address=true, indirect-api=false, port-defined-argument-value{value=34, value-type=uint8}, port=EnableCond_LV}
        {enable-take-address=true, indirect-api=false, port-defined-argument-value{value=17, value-type=uint8}, port=EnableCond_ElPowerLevel}
        {enable-take-address=true, indirect-api=false, port-defined-argument-value{value=88, value-type=uint8}, port=EnableCond_faults}
        {enable-take-address=true, indirect-api=false, port-defined-argument-value{value=35, value-type=uint8}, port=EnableCond_NO_002}
        {enable-take-address=true, indirect-api=false, port-defined-argument-value{value=100, value-type=uint8}, port=EnableCond_initliazation}
        {enable-take-address=true, indirect-api=false, port-defined-argument-value{value=153, value-type=uint8}, port=EnableCond_while}
        {enable-take-address=true, indirect-api=false, port-defined-argument-value{value=136, value-type=uint8}, port=EnableCond_start}
        {enable-take-address=true, indirect-api=false, port-defined-argument-value{value=86, value-type=uint8}, port=EnableCond_fault}
        {enable-take-address=true, indirect-api=false, port-defined-argument-value{value=87, value-type=uint8}, port=EnableCond_faulte}
        {enable-take-address=true, indirect-api=false, port-defined-argument-value{value=54, value-type=uint8}, port=EnableCond_a_001}
        {enable-take-address=true, indirect-api=false, port-defined-argument-value{value=73, value-type=uint8}, port=EnableCond_consumption}
        {enable-take-address=true, indirect-api=false, port-defined-argument-value{value=6, value-type=uint8}, port=EnableCond_BusOff}
        {enable-take-address=true, indirect-api=false, port-defined-argument-value{value=115, value-type=uint8}, port=EnableCond_once}
        {enable-take-address=true, indirect-api=false, port-defined-argument-value{value=66, value-type=uint8}, port=EnableCond_below}
        {enable-take-address=true, indirect-api=false, port-defined-argument-value{value=138, value-type=uint8}, port=EnableCond_system}
        {enable-take-address=true, indirect-api=false, port-defined-argument-value{value=52, value-type=uint8}, port=EnableCond_Voltage9}
        {enable-take-address=true, indirect-api=false, port-defined-argument-value{value=89, value-type=uint8}, port=EnableCond_for}
        {enable-take-address=true, indirect-api=false, port-defined-argument-value{value=83, value-type=uint8}, port=EnableCond_error}
        {enable-take-address=true, indirect-api=false, port-defined-argument-value{value=27, value-type=uint8}, port=EnableCond_INV_IAC_V_ELEC_HI}
        {enable-take-address=true, indirect-api=false, port-defined-argument-value{value=120, value-type=uint8}, port=EnableCond_passed}
        {enable-take-address=true, indirect-api=false, port-defined-argument-value{value=2, value-type=uint8}, port=EnableCond_AND}
        {enable-take-address=true, indirect-api=false, port-defined-argument-value{value=140, value-type=uint8}, port=EnableCond_test}
        {enable-take-address=true, indirect-api=false, port-defined-argument-value{value=65, value-type=uint8}, port=EnableCond_be}
        {enable-take-address=true, indirect-api=false, port-defined-argument-value{value=7, value-type=uint8}, port=EnableCond_CAN}
        {enable-take-address=true, indirect-api=false, port-defined-argument-value{value=122, value-type=uint8}, port=EnableCond_power}
        {enable-take-address=true, indirect-api=false, port-defined-argument-value{value=13, value-type=uint8}, port=EnableCond_DTC}
        {enable-take-address=true, indirect-api=false, port-defined-argument-value{value=146, value-type=uint8}, port=EnableCond_torque}
        {enable-take-address=true, indirect-api=false, port-defined-argument-value{value=107, value-type=uint8}, port=EnableCond_no_001}
        {enable-take-address=true, indirect-api=false, port-defined-argument-value{value=69, value-type=uint8}, port=EnableCond_by}
        {enable-take-address=true, indirect-api=false, port-defined-argument-value{value=20, value-type=uint8}, port=EnableCond_Factory}
        {enable-take-address=true, indirect-api=false, port-defined-argument-value{value=12, value-type=uint8}, port=EnableCond_Crash}
        {enable-take-address=true, indirect-api=false, port-defined-argument-value{value=134, value-type=uint8}, port=EnableCond_shall}
        {enable-take-address=true, indirect-api=false, port-defined-argument-value{value=151, value-type=uint8}, port=EnableCond_vehicle}
        {enable-take-address=true, indirect-api=false, port-defined-argument-value{value=123, value-type=uint8}, port=EnableCond_range}
        {enable-take-address=true, indirect-api=false, port-defined-argument-value{value=58, value-type=uint8}, port=EnableCond_all}
        {enable-take-address=true, indirect-api=false, port-defined-argument-value{value=31, value-type=uint8}, port=EnableCond_Inverter}
        {enable-take-address=true, indirect-api=false, port-defined-argument-value{value=10, value-type=uint8}, port=EnableCond_Car_001}
        {enable-take-address=true, indirect-api=false, port-defined-argument-value{value=43, value-type=uint8}, port=EnableCond_Request}
        {enable-take-address=true, indirect-api=false, port-defined-argument-value{value=44, value-type=uint8}, port=EnableCond_SPI}
        {enable-take-address=true, indirect-api=false, port-defined-argument-value{value=8, value-type=uint8}, port=EnableCond_CU}
        {enable-take-address=true, indirect-api=false, port-defined-argument-value{value=71, value-type=uint8}, port=EnableCond_change}
        {enable-take-address=true, indirect-api=false, port-defined-argument-value{value=30, value-type=uint8}, port=EnableCond_INV_IAC_W_ELEC_LO}
        {enable-take-address=true, indirect-api=false, port-defined-argument-value{value=84, value-type=uint8}, port=EnableCond_exceptions}
        {enable-take-address=true, indirect-api=false, port-defined-argument-value{value=145, value-type=uint8}, port=EnableCond_to}
        {enable-take-address=true, indirect-api=false, port-defined-argument-value{value=16, value-type=uint8}, port=EnableCond_ECU}
        {enable-take-address=true, indirect-api=false, port-defined-argument-value{value=41, value-type=uint8}, port=EnableCond_PS}
        {enable-take-address=true, indirect-api=false, port-defined-argument-value{value=113, value-type=uint8}, port=EnableCond_off}
        {enable-take-address=true, indirect-api=false, port-defined-argument-value{value=5, value-type=uint8}, port=EnableCond_Bulk}
        {enable-take-address=true, indirect-api=false, port-defined-argument-value{value=64, value-type=uint8}, port=EnableCond_availability}
        {enable-take-address=true, indirect-api=false, port-defined-argument-value{value=92, value-type=uint8}, port=EnableCond_generic}
        {enable-take-address=true, indirect-api=false, port-defined-argument-value{value=154, value-type=uint8}, port=EnableCond_with}
        {enable-take-address=true, indirect-api=false, port-defined-argument-value{value=105, value-type=uint8}, port=EnableCond_modes}
        {enable-take-address=true, indirect-api=false, port-defined-argument-value{value=14, value-type=uint8}, port=EnableCond_Driving}
        {enable-take-address=true, indirect-api=false, port-defined-argument-value{value=111, value-type=uint8}, port=EnableCond_notational}
        {enable-take-address=true, indirect-api=false, port-defined-argument-value{value=4, value-type=uint8}, port=EnableCond_All_001}
        {enable-take-address=true, indirect-api=false, port-defined-argument-value{value=46, value-type=uint8}, port=EnableCond_Test_001}
        {enable-take-address=true, indirect-api=false, port-defined-argument-value{value=135, value-type=uint8}, port=EnableCond_signal}
        {enable-take-address=true, indirect-api=false, port-defined-argument-value{value=144, value-type=uint8}, port=EnableCond_time}
        {enable-take-address=true, indirect-api=false, port-defined-argument-value{value=117, value-type=uint8}, port=EnableCond_operation}
        {enable-take-address=true, indirect-api=false, port-defined-argument-value{value=96, value-type=uint8}, port=EnableCond_indicated}
        {enable-take-address=true, indirect-api=false, port-defined-argument-value{value=50, value-type=uint8}, port=EnableCond_UsageMode}
        {enable-take-address=true, indirect-api=false, port-defined-argument-value{value=103, value-type=uint8}, port=EnableCond_low}
        {enable-take-address=true, indirect-api=false, port-defined-argument-value{value=97, value-type=uint8}, port=EnableCond_inhibited}
        {enable-take-address=true, indirect-api=false, port-defined-argument-value{value=62, value-type=uint8}, port=EnableCond_as}
        {enable-take-address=true, indirect-api=false, port-defined-argument-value{value=63, value-type=uint8}, port=EnableCond_at}
        {enable-take-address=true, indirect-api=false, port-defined-argument-value{value=24, value-type=uint8}, port=EnableCond_INV_EM_STATOR_TEMP_RNG_LO}
        {enable-take-address=true, indirect-api=false, port-defined-argument-value{value=99, value-type=uint8}, port=EnableCond_init}
        {enable-take-address=true, indirect-api=false, port-defined-argument-value{value=109, value-type=uint8}, port=EnableCond_normallye}
        {enable-take-address=true, indirect-api=false, port-defined-argument-value{value=125, value-type=uint8}, port=EnableCond_requested}
        {enable-take-address=true, indirect-api=false, port-defined-argument-value{value=76, value-type=uint8}, port=EnableCond_current}
        {enable-take-address=true, indirect-api=false, port-defined-argument-value{value=85, value-type=uint8}, port=EnableCond_exit}
        {enable-take-address=true, indirect-api=false, port-defined-argument-value{value=147, value-type=uint8}, port=EnableCond_toruqe}
        {enable-take-address=true, indirect-api=false, port-defined-argument-value{value=155, value-type=uint8}, port=EnableCond_work}
        {enable-take-address=true, indirect-api=false, port-defined-argument-value{value=72, value-type=uint8}, port=EnableCond_configuration_001}
        {enable-take-address=true, indirect-api=false, port-defined-argument-value{value=56, value-type=uint8}, port=EnableCond_according}
        {enable-take-address=true, indirect-api=false, port-defined-argument-value{value=81, value-type=uint8}, port=EnableCond_electrical}
        {enable-take-address=true, indirect-api=false, port-defined-argument-value{value=29, value-type=uint8}, port=EnableCond_INV_IAC_W_ELEC_HI}
        {enable-take-address=true, indirect-api=false, port-defined-argument-value{value=32, value-type=uint8}, port=EnableCond_KL15}
        {enable-take-address=true, indirect-api=false, port-defined-argument-value{value=19, value-type=uint8}, port=EnableCond_Every}
        {enable-take-address=true, indirect-api=false, port-defined-argument-value{value=127, value-type=uint8}, port=EnableCond_rpm}
        {enable-take-address=true, indirect-api=false, port-defined-argument-value{value=61, value-type=uint8}, port=EnableCond_any}
        {enable-take-address=true, indirect-api=false, port-defined-argument-value{value=129, value-type=uint8}, port=EnableCond_runs}
        {enable-take-address=true, indirect-api=false, port-defined-argument-value{value=53, value-type=uint8}, port=EnableCond_When}
        {enable-take-address=true, indirect-api=false, port-defined-argument-value{value=70, value-type=uint8}, port=EnableCond_car}
        {enable-take-address=true, indirect-api=false, port-defined-argument-value{value=110, value-type=uint8}, port=EnableCond_not_001}
        {enable-take-address=true, indirect-api=false, port-defined-argument-value{value=121, value-type=uint8}, port=EnableCond_phase}
        {enable-take-address=true, indirect-api=false, port-defined-argument-value{value=57, value-type=uint8}, port=EnableCond_active}
        {enable-take-address=true, indirect-api=false, port-defined-argument-value{value=108, value-type=uint8}, port=EnableCond_normally}
        {enable-take-address=true, indirect-api=false, port-defined-argument-value{value=82, value-type=uint8}, port=EnableCond_enters}
        {enable-take-address=true, indirect-api=false, port-defined-argument-value{value=33, value-type=uint8}, port=EnableCond_KL30}
        {enable-take-address=true, indirect-api=false, port-defined-argument-value{value=23, value-type=uint8}, port=EnableCond_INV_EM_STATOR_TEMP_RNG_HI}
        {enable-take-address=true, indirect-api=false, port-defined-argument-value{value=11, value-type=uint8}, port=EnableCond_Configuration}
        {enable-take-address=true, indirect-api=false, port-defined-argument-value{value=42, value-type=uint8}, port=EnableCond_Prop}
        {enable-take-address=true, indirect-api=false, port-defined-argument-value{value=98, value-type=uint8}, port=EnableCond_inhibition}
        {enable-take-address=true, indirect-api=false, port-defined-argument-value{value=75, value-type=uint8}, port=EnableCond_criteria}
        {enable-take-address=true, indirect-api=false, port-defined-argument-value{value=93, value-type=uint8}, port=EnableCond_global}
        {enable-take-address=true, indirect-api=false, port-defined-argument-value{value=9, value-type=uint8}, port=EnableCond_CU_temp}
        {enable-take-address=true, indirect-api=false, port-defined-argument-value{value=78, value-type=uint8}, port=EnableCond_done}
        {enable-take-address=true, indirect-api=false, port-defined-argument-value{value=38, value-type=uint8}, port=EnableCond_Not}
        {enable-take-address=true, indirect-api=false, port-defined-argument-value{value=60, value-type=uint8}, port=EnableCond_another}
        {enable-take-address=true, indirect-api=false, port-defined-argument-value{value=49, value-type=uint8}, port=EnableCond_Ubat}
        {enable-take-address=true, indirect-api=false, port-defined-argument-value{value=124, value-type=uint8}, port=EnableCond_received}
        {enable-take-address=true, indirect-api=false, port-defined-argument-value{value=141, value-type=uint8}, port=EnableCond_tests}
        {enable-take-address=true, indirect-api=false, port-defined-argument-value{value=90, value-type=uint8}, port=EnableCond_from}
        {enable-take-address=true, indirect-api=false, port-defined-argument-value{value=150, value-type=uint8}, port=EnableCond_used}
        {enable-take-address=true, indirect-api=false, port-defined-argument-value{value=21, value-type=uint8}, port=EnableCond_HVAC}
        {enable-take-address=true, indirect-api=false, port-defined-argument-value{value=94, value-type=uint8}, port=EnableCond_high}
        {enable-take-address=true, indirect-api=false, port-defined-argument-value{value=104, value-type=uint8}, port=EnableCond_mode}
        {enable-take-address=true, indirect-api=false, port-defined-argument-value{value=142, value-type=uint8}, port=EnableCond_that}
        {enable-take-address=true, indirect-api=false, port-defined-argument-value{value=128, value-type=uint8}, port=EnableCond_run}
        {enable-take-address=true, indirect-api=false, port-defined-argument-value{value=77, value-type=uint8}, port=EnableCond_discharge}
        {enable-take-address=true, indirect-api=false, port-defined-argument-value{value=149, value-type=uint8}, port=EnableCond_until}
        {enable-take-address=true, indirect-api=false, port-defined-argument-value{value=79, value-type=uint8}, port=EnableCond_during}
        {enable-take-address=true, indirect-api=false, port-defined-argument-value{value=45, value-type=uint8}, port=EnableCond_SpdAct}
        {enable-take-address=true, indirect-api=false, port-defined-argument-value{value=25, value-type=uint8}, port=EnableCond_INV_IAC_U_ELEC_HI}
        {enable-take-address=true, indirect-api=false, port-defined-argument-value{value=18, value-type=uint8}, port=EnableCond_Enabled}
        {enable-take-address=true, indirect-api=false, port-defined-argument-value{value=68, value-type=uint8}, port=EnableCond_bus}
        {enable-take-address=true, indirect-api=false, port-defined-argument-value{value=1, value-type=uint8}, port=EnableCond_A}
        {enable-take-address=true, indirect-api=false, port-defined-argument-value{value=139, value-type=uint8}, port=EnableCond_temp}
        {enable-take-address=true, indirect-api=false, port-defined-argument-value{value=15, value-type=uint8}, port=EnableCond_E}
        {enable-take-address=true, indirect-api=false, port-defined-argument-value{value=55, value-type=uint8}, port=EnableCond_abs}
        {enable-take-address=true, indirect-api=false, port-defined-argument-value{value=67, value-type=uint8}, port=EnableCond_block}
        {enable-take-address=true, indirect-api=false, port-defined-argument-value{value=47, value-type=uint8}, port=EnableCond_The_001}
        {enable-take-address=true, indirect-api=false, port-defined-argument-value{value=40, value-type=uint8}, port=EnableCond_P15}
        {enable-take-address=true, indirect-api=false, port-defined-argument-value{value=143, value-type=uint8}, port=EnableCond_the}
        {enable-take-address=true, indirect-api=false, port-defined-argument-value{value=102, value-type=uint8}, port=EnableCond_limited}
        {enable-take-address=true, indirect-api=false, port-defined-argument-value{value=91, value-type=uint8}, port=EnableCond_fulfilled}
        {enable-take-address=true, indirect-api=false, port-defined-argument-value{value=116, value-type=uint8}, port=EnableCond_one}
        {enable-take-address=true, indirect-api=false, port-defined-argument-value{value=133, value-type=uint8}, port=EnableCond_set}
        {enable-take-address=true, indirect-api=false, port-defined-argument-value{value=74, value-type=uint8}, port=EnableCond_control}
        {enable-take-address=true, indirect-api=false, port-defined-argument-value{value=51, value-type=uint8}, port=EnableCond_V}
        {enable-take-address=true, indirect-api=false, port-defined-argument-value{value=48, value-type=uint8}, port=EnableCond_Transport}
        {enable-take-address=true, indirect-api=false, port-defined-argument-value{value=95, value-type=uint8}, port=EnableCond_in}
        {enable-take-address=true, indirect-api=false, port-defined-argument-value{value=152, value-type=uint8}, port=EnableCond_when_001}
        {enable-take-address=true, indirect-api=false, port-defined-argument-value{value=3, value-type=uint8}, port=EnableCond_ASC}
        {enable-take-address=true, indirect-api=false, port-defined-argument-value{value=114, value-type=uint8}, port=EnableCond_offset}
        {enable-take-address=true, indirect-api=false, port-defined-argument-value{value=22, value-type=uint8}, port=EnableCond_IGBT}
        {enable-take-address=true, indirect-api=false, port-defined-argument-value{value=101, value-type=uint8}, port=EnableCond_is}
        {enable-take-address=true, indirect-api=false, port-defined-argument-value{value=80, value-type=uint8}, port=EnableCond_each}
        {enable-take-address=true, indirect-api=false, port-defined-argument-value{value=130, value-type=uint8}, port=EnableCond_s}
        {enable-take-address=true, indirect-api=false, port-defined-argument-value{value=132, value-type=uint8}, port=EnableCond_sensor}
        {enable-take-address=true, indirect-api=false, port-defined-argument-value{value=28, value-type=uint8}, port=EnableCond_INV_IAC_V_ELEC_LO}
        {enable-take-address=true, indirect-api=false, port-defined-argument-value{value=0, value-type=uint8}, port=IndStatus_WarningIndicator}
        {enable-take-address=true, indirect-api=false, port-defined-argument-value{value=0, value-type=uint8}, port=OpCycle_IgnitionCycle}
        {enable-take-address=true, indirect-api=false, port-defined-argument-value{value=1, value-type=uint8}, port=OpCycle_PowerCycle}
        enable-take-address=true, indirect-api=false, port=DemMaster_0/CBReadData_DTCStatusindicator30_DTCStatusindicator30
        enable-take-address=true, indirect-api=false, port=DemMaster_0/CBReadData_DID_0xe310_DID_E310_IEMMGM_Derating_Status
        enable-take-address=true, indirect-api=false, port=DemMaster_0/CBReadData_DID_0xe301_DID_E301_HVDC_Current_
        enable-take-address=true, indirect-api=false, port=DemMaster_0/CBReadData_DID_0xe305_DID_E305_Inverter_IGBT_Junction_Temp
        enable-take-address=true, indirect-api=false, port=DemMaster_0/CBReadData_DID_0xe339_DID_E339_d_axis_voltage
        enable-take-address=true, indirect-api=false, port=DemMaster_0/CBReadData_DID_0xe307_DID_E307_System_Mode
        enable-take-address=true, indirect-api=false, port=DemMaster_0/CBReadData_DID_0xe357_DID_E357_Resolve_compensated_angle
        enable-take-address=true, indirect-api=false, port=DemMaster_0/CBReadData_DID_0xe308_DID_E308_ECM_Torque_Request
        enable-take-address=true, indirect-api=false, port=DemMaster_0/CBReadData_DID_0xe335_DID_E335_d_axis_current_setpoint
        enable-take-address=true, indirect-api=false, port=DemMaster_0/CBReadData_DID_0xe319_DID_E319_Torque_Direction
        enable-take-address=true, indirect-api=false, port=DemMaster_0/CBReadData_DID_0xe309_DID_E309_ECM_Mode_Request
        enable-take-address=true, indirect-api=false, port=DemMaster_0/CBReadData_DID_0xdd0a_DID_DD0A_Usage_Mode
        enable-take-address=true, indirect-api=false, port=DemMaster_0/CBReadData_DID_0xeec3_DID_EEC3_ECU_power_supply_Voltage
        enable-take-address=true, indirect-api=false, port=DemMaster_0/CBReadData_DID_0xdd00_DID_DD00_Global_Real_Time
        enable-take-address=true, indirect-api=false, port=DemMaster_0/CBReadData_DID_0xee9e_DID_EE9E_Transient_Phase_Current_C
        enable-take-address=true, indirect-api=false, port=DemMaster_0/CBReadData_DID_0xe333_2002_Hu
        enable-take-address=true, indirect-api=false, port=DemMaster_0/CBReadData_DID_0xe333_2002_Hw
        enable-take-address=true, indirect-api=false, port=DemMaster_0/CBReadData_DID_0xe333_2002_Hv
        enable-take-address=true, indirect-api=false, port=DemMaster_0/CBReadData_DID_0xe314_DID_E314_Available_Torque_maximum
        enable-take-address=true, indirect-api=false, port=DemMaster_0/CBReadData_DID_0xeed4_DID_EED4_Safty_Function_Mode
        enable-take-address=true, indirect-api=false, port=DemMaster_0/CBReadData_DID_0xd003_DID_D003_Vehicle_Speed
        enable-take-address=true, indirect-api=false, port=DemMaster_0/CBReadData_DID_0xe303_DID_E303_Motor_Speed_
        enable-take-address=true, indirect-api=false, port=DemMaster_0/CBReadData_DID_0xe353_DID_E353_Flux_weakening_correction_factor
        enable-take-address=true, indirect-api=false, port=DemMaster_0/CBReadData_DID_0xe306_DID_E306_Motor_Temperature
        enable-take-address=true, indirect-api=false, port=DemMaster_0/CBReadData_DID_0xe363_DID_E363_Modulation_index
        enable-take-address=true, indirect-api=false, port=DemMaster_0/CBReadData_DID_0xe349_DID_E349_Phase_V_PWM_duty
        enable-take-address=true, indirect-api=false, port=DemMaster_0/CBReadData_DID_0xdd02_DID_DD02_Vehicle_Battery_Voltage
        enable-take-address=true, indirect-api=false, port=DemMaster_0/CBReadData_DTCTimeStamp21_DTCTimeStamp21
        enable-take-address=true, indirect-api=false, port=DemMaster_0/CBReadData_DID_0xe347_DID_E347_IGBT_Max_Temperature
        enable-take-address=true, indirect-api=false, port=DemMaster_0/CBReadData_DID_0xeeb5_DID_EEB5_IEMMGM_current_torque
        enable-take-address=true, indirect-api=false, port=DemMaster_0/CBReadData_DID_0xeebe_DID_EEBE_Offset_angle_status
        enable-take-address=true, indirect-api=false, port=DemMaster_0/CBReadData_DID_0xe338_DID_E338_q_axis_current_feedback
        enable-take-address=true, indirect-api=false, port=DemMaster_0/CBReadData_DID_0xee9d_DID_EE9D_Transient_Phase_Current_B
        enable-take-address=true, indirect-api=false, port=DemMaster_0/CBReadData_DID_0xe336_DID_E336_d_axis_current_feedback
        enable-take-address=true, indirect-api=false, port=DemMaster_0/CBReadData_DID_0xe348_DID_E348_Phase_U_PWM_duty
        enable-take-address=true, indirect-api=false, port=DemMaster_0/CBReadData_DID_0xe350_DID_E350_Phase_W_PWM_duty
        enable-take-address=true, indirect-api=false, port=DemMaster_0/CBReadData_DTCTimeStamp20_DTCTimeStamp20
        enable-take-address=true, indirect-api=false, port=DemMaster_0/CBReadData_DID_0xe333_2002_H_Ser
        enable-take-address=true, indirect-api=false, port=DemMaster_0/CBReadData_DID_0xeec4_DID_EEC4_Charging_Power_Sustain_RelayCPSR_Voltage
        enable-take-address=true, indirect-api=false, port=DemMaster_0/CBReadData_DID_0xe346_DID_E346_ECM_Torque_Allowed_Status
        enable-take-address=true, indirect-api=false, port=DemMaster_0/CBReadData_DID_0xe313_DID_E313_Active_discharge_status
        enable-take-address=true, indirect-api=false, port=DemMaster_0/CBReadData_DID_0xe311_DID_E311_Crash_Status
        enable-take-address=true, indirect-api=false, port=DemMaster_0/CBReadData_DID_0xe300_DID_E300_HVDC_Voltage
        enable-take-address=true, indirect-api=false, port=DemMaster_0/CBReadData_DID_0xe324_DID_E324_Motor_Derating_reason_of_IEMMGM
        enable-take-address=true, indirect-api=false, port=DemMaster_0/CBReadData_DID_0xee9f_DID_EE9F_Gate_Status
        enable-take-address=true, indirect-api=false, port=DemMaster_0/CBReadData_DID_0xe304_DID_E304_Actual_Torque
        enable-take-address=true, indirect-api=false, port=DemMaster_0/CBReadData_DID_0xe315_DID_E315_Available_Torque_minimum
        enable-take-address=true, indirect-api=false, port=DemMaster_0/CBReadData_DID_0xeeb8_DID_EEB8_HV_voltage_received_from_BECM
        enable-take-address=true, indirect-api=false, port=DemMaster_0/CBReadData_DID_0xeed5_EED5_Safety_Torque_Quality_factor
        enable-take-address=true, indirect-api=false, port=DemMaster_0/CBReadData_DID_0xe320_DID_E320_System_Mode_Mismatch
        enable-take-address=true, indirect-api=false, port=DemMaster_0/CBReadData_DID_0xeeb7_DID_EEB7_ECM_Power_Limitation_minimum
        enable-take-address=true, indirect-api=false, port=DemMaster_0/CBReadData_DID_0xe364_DID_E364_AURIX_Fault_Indication
        enable-take-address=true, indirect-api=false, port=DemMaster_0/CBReadData_DID_0xeed1_EED1_1
        enable-take-address=true, indirect-api=false, port=DemMaster_0/CBReadData_DID_0xeed1_EED1_0
        enable-take-address=true, indirect-api=false, port=DemMaster_0/CBReadData_DID_0xeed1_EED1_3
        enable-take-address=true, indirect-api=false, port=DemMaster_0/CBReadData_DID_0xeed1_EED1_2
        enable-take-address=true, indirect-api=false, port=DemMaster_0/CBReadData_DID_0xe312_DID_E312_Wheel_Speed
        enable-take-address=true, indirect-api=false, port=DemMaster_0/CBReadData_DID_0xe341_DID_E341_q_axis_voltage
        enable-take-address=true, indirect-api=false, port=DemMaster_0/CBReadData_DID_0xeed3_DID_EED3_Safety_speed
        enable-take-address=true, indirect-api=false, port=DemMaster_0/CBReadData_DID_0xee9c_DID_EE9C_Transient_Phase_Current_A
        enable-take-address=true, indirect-api=false, port=DemMaster_0/CBReadData_DID_0xeed2_DID_EED2_SaftyTorque
        enable-take-address=true, indirect-api=false, port=DemMaster_0/CBReadData_DID_0xdd01_DID_DD01_Total_Distance
        enable-take-address=true, indirect-api=false, port=DemMaster_0/CBReadData_DID_0xeebf_DID_EEBF_HV_Main_Relay_Status
        enable-take-address=true, indirect-api=false, port=DemMaster_0/CBReadData_DID_0xe333_2002_L_Ser
        enable-take-address=true, indirect-api=false, port=DemMaster_0/CBReadData_DID_0xeeb2_DID_EEB2_Three_Phase_Motor_Current_RMS_Current
        enable-take-address=true, indirect-api=false, port=DemMaster_0/CBReadData_DID_0xe333_2002_Lw
        enable-take-address=true, indirect-api=false, port=DemMaster_0/CBReadData_DID_0xe333_2002_Lv
        enable-take-address=true, indirect-api=false, port=DemMaster_0/CBReadData_DID_0xee9a_DID_EE9A_Inverter_Coolant_Temperature
        enable-take-address=true, indirect-api=false, port=DemMaster_0/CBReadData_DID_0xdd0c_DID_DD0C_Electric_Power_Level
        enable-take-address=true, indirect-api=false, port=DemMaster_0/CBReadData_DID_0xe337_DID_E337_q_axis_current_setpoint
        enable-take-address=true, indirect-api=false, port=DemMaster_0/CBReadData_DID_0xeeb6_DID_EEB6_ECM_Power_Limitation_maximum
        enable-take-address=true, indirect-api=false, port=DemMaster_0/CBReadData_DID_0xe358_DID_E358_Resolve_angle
        enable-take-address=true, indirect-api=false, port=DemMaster_0/CBReadData_DID_0xe333_2002_Lu
        {enable-take-address=true, indirect-api=false, port-defined-argument-value{value=0, value-type=uint8}, port=ClearDTC_DemClient_Dcm}
        {enable-take-address=true, indirect-api=false, port-arg-values=[{value=0, value-type=uint8}, {value=1, value-type=Dem_DTCOriginType}], port=OverflowIndPrimaryMemory_DemClient_Dcm}
      22 x runnable:
        Dem_MasterMainFunction
          74 x sync call, all with timeout=0:
            OpServerCallDem_MasterMainFunction_InitMonitorForEvent_CBInitEvt_PS_5V_Fault: operation=CBInitEvt_PS_5V_Fault.InitMonitorForEvent
            OpServerCallDem_MasterMainFunction_ReadData_CBReadData_DTCStatusindicator30_DTCStatusindicator30: operation=CBReadData_DTCStatusindicator30_DTCStatusindicator30.ReadData
            OpServerCallDem_MasterMainFunction_ReadData_CBReadData_DID_0xe310_DID_E310_IEMMGM_Derating_Status: operation=CBReadData_DID_0xe310_DID_E310_IEMMGM_Derating_Status.ReadData
            OpServerCallDem_MasterMainFunction_ReadData_CBReadData_DID_0xe301_DID_E301_HVDC_Current_: operation=CBReadData_DID_0xe301_DID_E301_HVDC_Current_.ReadData
            OpServerCallDem_MasterMainFunction_ReadData_CBReadData_DID_0xe305_DID_E305_Inverter_IGBT_Junction_Temp: operation=CBReadData_DID_0xe305_DID_E305_Inverter_IGBT_Junction_Temp.ReadData
            OpServerCallDem_MasterMainFunction_ReadData_CBReadData_DID_0xe339_DID_E339_d_axis_voltage: operation=CBReadData_DID_0xe339_DID_E339_d_axis_voltage.ReadData
            OpServerCallDem_MasterMainFunction_ReadData_CBReadData_DID_0xe307_DID_E307_System_Mode: operation=CBReadData_DID_0xe307_DID_E307_System_Mode.ReadData
            OpServerCallDem_MasterMainFunction_ReadData_CBReadData_DID_0xe357_DID_E357_Resolve_compensated_angle: operation=CBReadData_DID_0xe357_DID_E357_Resolve_compensated_angle.ReadData
            OpServerCallDem_MasterMainFunction_ReadData_CBReadData_DID_0xe308_DID_E308_ECM_Torque_Request: operation=CBReadData_DID_0xe308_DID_E308_ECM_Torque_Request.ReadData
            OpServerCallDem_MasterMainFunction_ReadData_CBReadData_DID_0xe335_DID_E335_d_axis_current_setpoint: operation=CBReadData_DID_0xe335_DID_E335_d_axis_current_setpoint.ReadData
            OpServerCallDem_MasterMainFunction_ReadData_CBReadData_DID_0xe319_DID_E319_Torque_Direction: operation=CBReadData_DID_0xe319_DID_E319_Torque_Direction.ReadData
            OpServerCallDem_MasterMainFunction_ReadData_CBReadData_DID_0xe309_DID_E309_ECM_Mode_Request: operation=CBReadData_DID_0xe309_DID_E309_ECM_Mode_Request.ReadData
            OpServerCallDem_MasterMainFunction_ReadData_CBReadData_DID_0xdd0a_DID_DD0A_Usage_Mode: operation=CBReadData_DID_0xdd0a_DID_DD0A_Usage_Mode.ReadData
            OpServerCallDem_MasterMainFunction_ReadData_CBReadData_DID_0xeec3_DID_EEC3_ECU_power_supply_Voltage: operation=CBReadData_DID_0xeec3_DID_EEC3_ECU_power_supply_Voltage.ReadData
            OpServerCallDem_MasterMainFunction_ReadData_CBReadData_DID_0xdd00_DID_DD00_Global_Real_Time: operation=CBReadData_DID_0xdd00_DID_DD00_Global_Real_Time.ReadData
            OpServerCallDem_MasterMainFunction_ReadData_CBReadData_DID_0xee9e_DID_EE9E_Transient_Phase_Current_C: operation=CBReadData_DID_0xee9e_DID_EE9E_Transient_Phase_Current_C.ReadData
            OpServerCallDem_MasterMainFunction_ReadData_CBReadData_DID_0xe333_2002_Hu: operation=CBReadData_DID_0xe333_2002_Hu.ReadData
            OpServerCallDem_MasterMainFunction_ReadData_CBReadData_DID_0xe333_2002_Hw: operation=CBReadData_DID_0xe333_2002_Hw.ReadData
            OpServerCallDem_MasterMainFunction_ReadData_CBReadData_DID_0xe333_2002_Hv: operation=CBReadData_DID_0xe333_2002_Hv.ReadData
            OpServerCallDem_MasterMainFunction_ReadData_CBReadData_DID_0xe314_DID_E314_Available_Torque_maximum: operation=CBReadData_DID_0xe314_DID_E314_Available_Torque_maximum.ReadData
            OpServerCallDem_MasterMainFunction_ReadData_CBReadData_DID_0xeed4_DID_EED4_Safty_Function_Mode: operation=CBReadData_DID_0xeed4_DID_EED4_Safty_Function_Mode.ReadData
            OpServerCallDem_MasterMainFunction_ReadData_CBReadData_DID_0xd003_DID_D003_Vehicle_Speed: operation=CBReadData_DID_0xd003_DID_D003_Vehicle_Speed.ReadData
            OpServerCallDem_MasterMainFunction_ReadData_CBReadData_DID_0xe303_DID_E303_Motor_Speed_: operation=CBReadData_DID_0xe303_DID_E303_Motor_Speed_.ReadData
            OpServerCallDem_MasterMainFunction_ReadData_CBReadData_DID_0xe353_DID_E353_Flux_weakening_correction_factor: operation=CBReadData_DID_0xe353_DID_E353_Flux_weakening_correction_factor.ReadData
            OpServerCallDem_MasterMainFunction_ReadData_CBReadData_DID_0xe306_DID_E306_Motor_Temperature: operation=CBReadData_DID_0xe306_DID_E306_Motor_Temperature.ReadData
            OpServerCallDem_MasterMainFunction_ReadData_CBReadData_DID_0xe363_DID_E363_Modulation_index: operation=CBReadData_DID_0xe363_DID_E363_Modulation_index.ReadData
            OpServerCallDem_MasterMainFunction_ReadData_CBReadData_DID_0xe349_DID_E349_Phase_V_PWM_duty: operation=CBReadData_DID_0xe349_DID_E349_Phase_V_PWM_duty.ReadData
            OpServerCallDem_MasterMainFunction_ReadData_CBReadData_DID_0xdd02_DID_DD02_Vehicle_Battery_Voltage: operation=CBReadData_DID_0xdd02_DID_DD02_Vehicle_Battery_Voltage.ReadData
            OpServerCallDem_MasterMainFunction_ReadData_CBReadData_DTCTimeStamp21_DTCTimeStamp21: operation=CBReadData_DTCTimeStamp21_DTCTimeStamp21.ReadData
            OpServerCallDem_MasterMainFunction_ReadData_CBReadData_DID_0xe347_DID_E347_IGBT_Max_Temperature: operation=CBReadData_DID_0xe347_DID_E347_IGBT_Max_Temperature.ReadData
            OpServerCallDem_MasterMainFunction_ReadData_CBReadData_DID_0xeeb5_DID_EEB5_IEMMGM_current_torque: operation=CBReadData_DID_0xeeb5_DID_EEB5_IEMMGM_current_torque.ReadData
            OpServerCallDem_MasterMainFunction_ReadData_CBReadData_DID_0xeebe_DID_EEBE_Offset_angle_status: operation=CBReadData_DID_0xeebe_DID_EEBE_Offset_angle_status.ReadData
            OpServerCallDem_MasterMainFunction_ReadData_CBReadData_DID_0xe338_DID_E338_q_axis_current_feedback: operation=CBReadData_DID_0xe338_DID_E338_q_axis_current_feedback.ReadData
            OpServerCallDem_MasterMainFunction_ReadData_CBReadData_DID_0xee9d_DID_EE9D_Transient_Phase_Current_B: operation=CBReadData_DID_0xee9d_DID_EE9D_Transient_Phase_Current_B.ReadData
            OpServerCallDem_MasterMainFunction_ReadData_CBReadData_DID_0xe336_DID_E336_d_axis_current_feedback: operation=CBReadData_DID_0xe336_DID_E336_d_axis_current_feedback.ReadData
            OpServerCallDem_MasterMainFunction_ReadData_CBReadData_DID_0xe348_DID_E348_Phase_U_PWM_duty: operation=CBReadData_DID_0xe348_DID_E348_Phase_U_PWM_duty.ReadData
            OpServerCallDem_MasterMainFunction_ReadData_CBReadData_DID_0xe350_DID_E350_Phase_W_PWM_duty: operation=CBReadData_DID_0xe350_DID_E350_Phase_W_PWM_duty.ReadData
            OpServerCallDem_MasterMainFunction_ReadData_CBReadData_DTCTimeStamp20_DTCTimeStamp20: operation=CBReadData_DTCTimeStamp20_DTCTimeStamp20.ReadData
            OpServerCallDem_MasterMainFunction_ReadData_CBReadData_DID_0xe333_2002_H_Ser: operation=CBReadData_DID_0xe333_2002_H_Ser.ReadData
            OpServerCallDem_MasterMainFunction_ReadData_CBReadData_DID_0xeec4_DID_EEC4_Charging_Power_Sustain_RelayCPSR_Voltage: operation=CBReadData_DID_0xeec4_DID_EEC4_Charging_Power_Sustain_RelayCPSR_Voltage.ReadData
            OpServerCallDem_MasterMainFunction_ReadData_CBReadData_DID_0xe346_DID_E346_ECM_Torque_Allowed_Status: operation=CBReadData_DID_0xe346_DID_E346_ECM_Torque_Allowed_Status.ReadData
            OpServerCallDem_MasterMainFunction_ReadData_CBReadData_DID_0xe313_DID_E313_Active_discharge_status: operation=CBReadData_DID_0xe313_DID_E313_Active_discharge_status.ReadData
            OpServerCallDem_MasterMainFunction_ReadData_CBReadData_DID_0xe311_DID_E311_Crash_Status: operation=CBReadData_DID_0xe311_DID_E311_Crash_Status.ReadData
            OpServerCallDem_MasterMainFunction_ReadData_CBReadData_DID_0xe300_DID_E300_HVDC_Voltage: operation=CBReadData_DID_0xe300_DID_E300_HVDC_Voltage.ReadData
            OpServerCallDem_MasterMainFunction_ReadData_CBReadData_DID_0xe324_DID_E324_Motor_Derating_reason_of_IEMMGM: operation=CBReadData_DID_0xe324_DID_E324_Motor_Derating_reason_of_IEMMGM.ReadData
            OpServerCallDem_MasterMainFunction_ReadData_CBReadData_DID_0xee9f_DID_EE9F_Gate_Status: operation=CBReadData_DID_0xee9f_DID_EE9F_Gate_Status.ReadData
            OpServerCallDem_MasterMainFunction_ReadData_CBReadData_DID_0xe304_DID_E304_Actual_Torque: operation=CBReadData_DID_0xe304_DID_E304_Actual_Torque.ReadData
            OpServerCallDem_MasterMainFunction_ReadData_CBReadData_DID_0xe315_DID_E315_Available_Torque_minimum: operation=CBReadData_DID_0xe315_DID_E315_Available_Torque_minimum.ReadData
            OpServerCallDem_MasterMainFunction_ReadData_CBReadData_DID_0xeeb8_DID_EEB8_HV_voltage_received_from_BECM: operation=CBReadData_DID_0xeeb8_DID_EEB8_HV_voltage_received_from_BECM.ReadData
            OpServerCallDem_MasterMainFunction_ReadData_CBReadData_DID_0xeed5_EED5_Safety_Torque_Quality_factor: operation=CBReadData_DID_0xeed5_EED5_Safety_Torque_Quality_factor.ReadData
            OpServerCallDem_MasterMainFunction_ReadData_CBReadData_DID_0xe320_DID_E320_System_Mode_Mismatch: operation=CBReadData_DID_0xe320_DID_E320_System_Mode_Mismatch.ReadData
            OpServerCallDem_MasterMainFunction_ReadData_CBReadData_DID_0xeeb7_DID_EEB7_ECM_Power_Limitation_minimum: operation=CBReadData_DID_0xeeb7_DID_EEB7_ECM_Power_Limitation_minimum.ReadData
            OpServerCallDem_MasterMainFunction_ReadData_CBReadData_DID_0xe364_DID_E364_AURIX_Fault_Indication: operation=CBReadData_DID_0xe364_DID_E364_AURIX_Fault_Indication.ReadData
            OpServerCallDem_MasterMainFunction_ReadData_CBReadData_DID_0xeed1_EED1_1: operation=CBReadData_DID_0xeed1_EED1_1.ReadData
            OpServerCallDem_MasterMainFunction_ReadData_CBReadData_DID_0xeed1_EED1_0: operation=CBReadData_DID_0xeed1_EED1_0.ReadData
            OpServerCallDem_MasterMainFunction_ReadData_CBReadData_DID_0xeed1_EED1_3: operation=CBReadData_DID_0xeed1_EED1_3.ReadData
            OpServerCallDem_MasterMainFunction_ReadData_CBReadData_DID_0xeed1_EED1_2: operation=CBReadData_DID_0xeed1_EED1_2.ReadData
            OpServerCallDem_MasterMainFunction_ReadData_CBReadData_DID_0xe312_DID_E312_Wheel_Speed: operation=CBReadData_DID_0xe312_DID_E312_Wheel_Speed.ReadData
            OpServerCallDem_MasterMainFunction_ReadData_CBReadData_DID_0xe341_DID_E341_q_axis_voltage: operation=CBReadData_DID_0xe341_DID_E341_q_axis_voltage.ReadData
            OpServerCallDem_MasterMainFunction_ReadData_CBReadData_DID_0xeed3_DID_EED3_Safety_speed: operation=CBReadData_DID_0xeed3_DID_EED3_Safety_speed.ReadData
            OpServerCallDem_MasterMainFunction_ReadData_CBReadData_DID_0xee9c_DID_EE9C_Transient_Phase_Current_A: operation=CBReadData_DID_0xee9c_DID_EE9C_Transient_Phase_Current_A.ReadData
            OpServerCallDem_MasterMainFunction_ReadData_CBReadData_DID_0xeed2_DID_EED2_SaftyTorque: operation=CBReadData_DID_0xeed2_DID_EED2_SaftyTorque.ReadData
            OpServerCallDem_MasterMainFunction_ReadData_CBReadData_DID_0xdd01_DID_DD01_Total_Distance: operation=CBReadData_DID_0xdd01_DID_DD01_Total_Distance.ReadData
            OpServerCallDem_MasterMainFunction_ReadData_CBReadData_DID_0xeebf_DID_EEBF_HV_Main_Relay_Status: operation=CBReadData_DID_0xeebf_DID_EEBF_HV_Main_Relay_Status.ReadData
            OpServerCallDem_MasterMainFunction_ReadData_CBReadData_DID_0xe333_2002_L_Ser: operation=CBReadData_DID_0xe333_2002_L_Ser.ReadData
            OpServerCallDem_MasterMainFunction_ReadData_CBReadData_DID_0xeeb2_DID_EEB2_Three_Phase_Motor_Current_RMS_Current: operation=CBReadData_DID_0xeeb2_DID_EEB2_Three_Phase_Motor_Current_RMS_Current.ReadData
            OpServerCallDem_MasterMainFunction_ReadData_CBReadData_DID_0xe333_2002_Lw: operation=CBReadData_DID_0xe333_2002_Lw.ReadData
            OpServerCallDem_MasterMainFunction_ReadData_CBReadData_DID_0xe333_2002_Lv: operation=CBReadData_DID_0xe333_2002_Lv.ReadData
            OpServerCallDem_MasterMainFunction_ReadData_CBReadData_DID_0xee9a_DID_EE9A_Inverter_Coolant_Temperature: operation=CBReadData_DID_0xee9a_DID_EE9A_Inverter_Coolant_Temperature.ReadData
            OpServerCallDem_MasterMainFunction_ReadData_CBReadData_DID_0xdd0c_DID_DD0C_Electric_Power_Level: operation=CBReadData_DID_0xdd0c_DID_DD0C_Electric_Power_Level.ReadData
            OpServerCallDem_MasterMainFunction_ReadData_CBReadData_DID_0xe337_DID_E337_q_axis_current_setpoint: operation=CBReadData_DID_0xe337_DID_E337_q_axis_current_setpoint.ReadData
            OpServerCallDem_MasterMainFunction_ReadData_CBReadData_DID_0xeeb6_DID_EEB6_ECM_Power_Limitation_maximum: operation=CBReadData_DID_0xeeb6_DID_EEB6_ECM_Power_Limitation_maximum.ReadData
            OpServerCallDem_MasterMainFunction_ReadData_CBReadData_DID_0xe358_DID_E358_Resolve_angle: operation=CBReadData_DID_0xe358_DID_E358_Resolve_angle.ReadData
            OpServerCallDem_MasterMainFunction_ReadData_CBReadData_DID_0xe333_2002_Lu: operation=CBReadData_DID_0xe333_2002_Lu.ReadData
        PostRunRequested: can-be-invoked-concurrently=true, symbol=Dem_PostRunRequested
        GetDTCStatusAvailabilityMask: can-be-invoked-concurrently=true, symbol=Dem_GetDTCStatusAvailabilityMask
        SetEnableCondition: can-be-invoked-concurrently=true, symbol=Dem_SetEnableCondition
        GetIndicatorStatus: can-be-invoked-concurrently=true, symbol=Dem_GetIndicatorStatus
        GetEventUdsStatus: can-be-invoked-concurrently=true, symbol=Dem_GetEventUdsStatus
        GetEventStatus: can-be-invoked-concurrently=true, symbol=Dem_GetEventUdsStatus
        GetEventFailed: can-be-invoked-concurrently=true, symbol=Dem_GetEventFailed
        GetEventTested: can-be-invoked-concurrently=true, symbol=Dem_GetEventTested
        GetDTCOfEvent: can-be-invoked-concurrently=true, symbol=Dem_GetDTCOfEvent
        GetFaultDetectionCounter: can-be-invoked-concurrently=true, symbol=Dem_GetFaultDetectionCounter
        GetEventFreezeFrameDataEx: can-be-invoked-concurrently=true, symbol=Dem_GetEventFreezeFrameDataEx
        GetEventExtendedDataRecordEx: can-be-invoked-concurrently=true, symbol=Dem_GetEventExtendedDataRecordEx
        GetEventEnableCondition: can-be-invoked-concurrently=true, symbol=Dem_GetEventEnableCondition
        GetDebouncingOfEvent: can-be-invoked-concurrently=true, symbol=Dem_GetDebouncingOfEvent
        GetMonitorStatus: can-be-invoked-concurrently=true, symbol=Dem_GetMonitorStatus
        GetOperationCycleState: can-be-invoked-concurrently=true, symbol=Dem_GetOperationCycleState
        SetOperationCycleState: can-be-invoked-concurrently=true, symbol=Dem_SetOperationCycleState
        ClearDTC: can-be-invoked-concurrently=true, symbol=Dem_ClearDTC
        SelectDTC: can-be-invoked-concurrently=true, symbol=Dem_SelectDTC
        GetEventMemoryOverflow: can-be-invoked-concurrently=true, symbol=Dem_GetEventMemoryOverflow
        GetNumberOfEventMemoryEntries: can-be-invoked-concurrently=true, symbol=Dem_GetNumberOfEventMemoryEntries
  swc implementation DemMaster_0Implementation: programming-language=C, behavior=DemMaster_0InternalBehavior
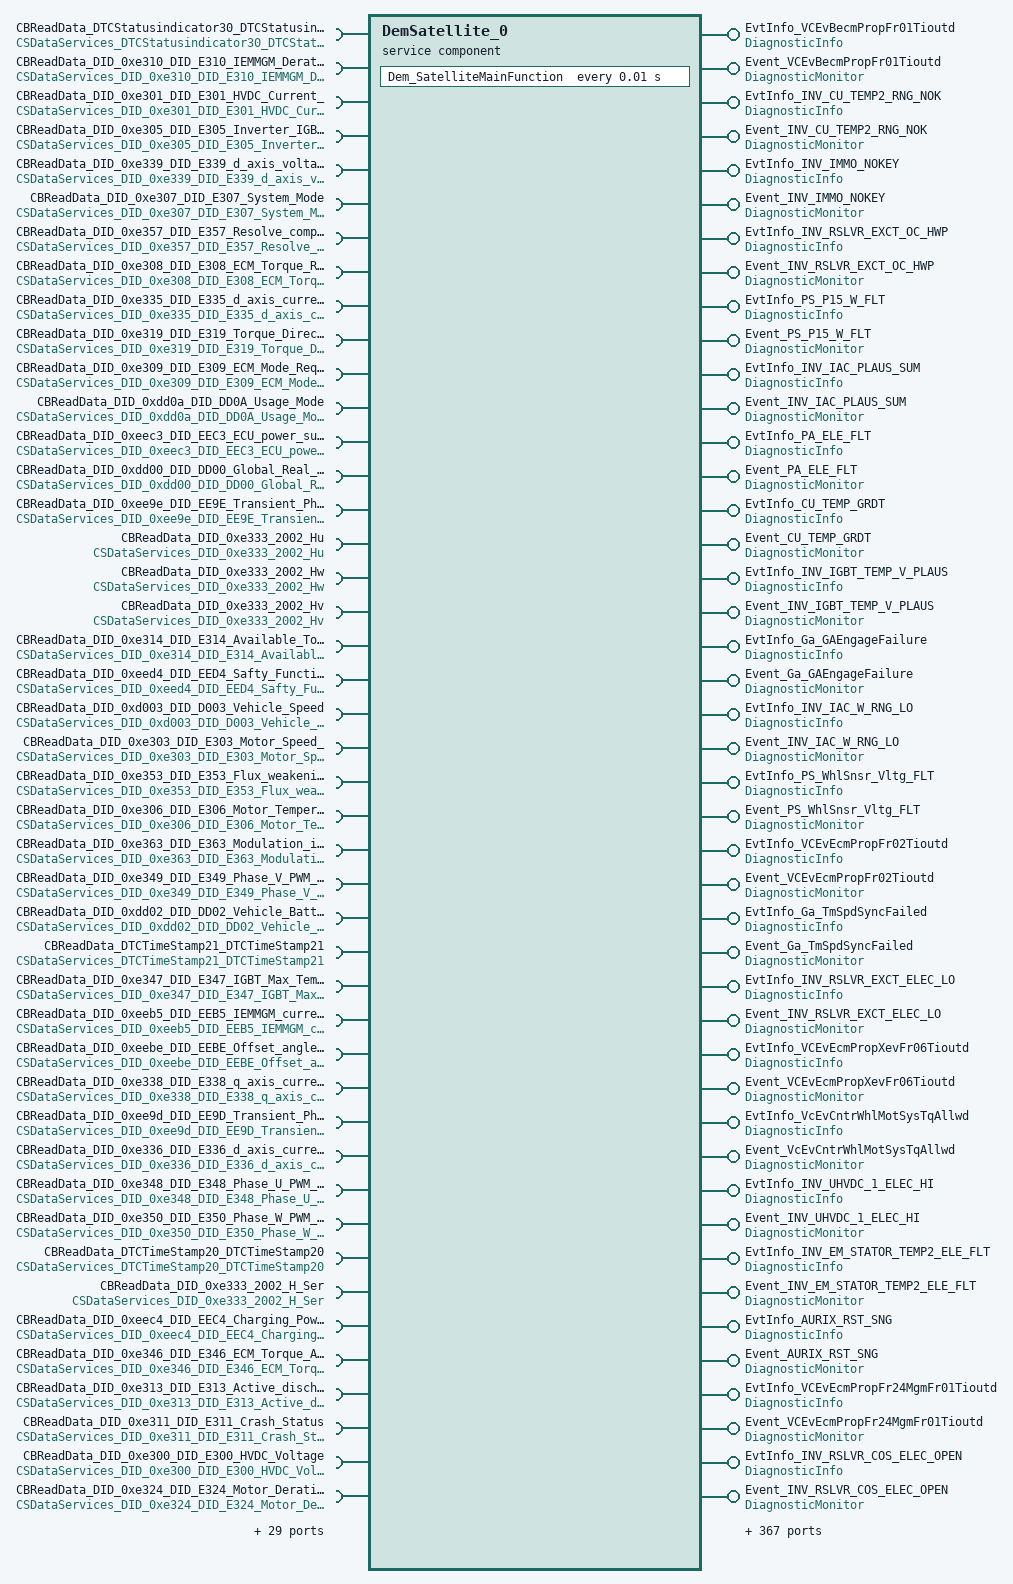
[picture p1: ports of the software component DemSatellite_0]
  service sw component type DemSatellite_0: category=SERVICE_COMPONENT
    411 x provide port:
      EvtInfo_VCEvBecmPropFr01Tioutd: provided-interface=DiagnosticInfo
      Event_VCEvBecmPropFr01Tioutd: provided-interface=DiagnosticMonitor
      EvtInfo_INV_CU_TEMP2_RNG_NOK: provided-interface=DiagnosticInfo
      Event_INV_CU_TEMP2_RNG_NOK: provided-interface=DiagnosticMonitor
      EvtInfo_INV_IMMO_NOKEY: provided-interface=DiagnosticInfo
      Event_INV_IMMO_NOKEY: provided-interface=DiagnosticMonitor
      EvtInfo_INV_RSLVR_EXCT_OC_HWP: provided-interface=DiagnosticInfo
      Event_INV_RSLVR_EXCT_OC_HWP: provided-interface=DiagnosticMonitor
      EvtInfo_PS_P15_W_FLT: provided-interface=DiagnosticInfo
      Event_PS_P15_W_FLT: provided-interface=DiagnosticMonitor
      EvtInfo_INV_IAC_PLAUS_SUM: provided-interface=DiagnosticInfo
      Event_INV_IAC_PLAUS_SUM: provided-interface=DiagnosticMonitor
      EvtInfo_PA_ELE_FLT: provided-interface=DiagnosticInfo
      Event_PA_ELE_FLT: provided-interface=DiagnosticMonitor
      EvtInfo_CU_TEMP_GRDT: provided-interface=DiagnosticInfo
      Event_CU_TEMP_GRDT: provided-interface=DiagnosticMonitor
      EvtInfo_INV_IGBT_TEMP_V_PLAUS: provided-interface=DiagnosticInfo
      Event_INV_IGBT_TEMP_V_PLAUS: provided-interface=DiagnosticMonitor
      EvtInfo_Ga_GAEngageFailure: provided-interface=DiagnosticInfo
      Event_Ga_GAEngageFailure: provided-interface=DiagnosticMonitor
      EvtInfo_INV_IAC_W_RNG_LO: provided-interface=DiagnosticInfo
      Event_INV_IAC_W_RNG_LO: provided-interface=DiagnosticMonitor
      EvtInfo_PS_WhlSnsr_Vltg_FLT: provided-interface=DiagnosticInfo
      Event_PS_WhlSnsr_Vltg_FLT: provided-interface=DiagnosticMonitor
      EvtInfo_VCEvEcmPropFr02Tioutd: provided-interface=DiagnosticInfo
      Event_VCEvEcmPropFr02Tioutd: provided-interface=DiagnosticMonitor
      EvtInfo_Ga_TmSpdSyncFailed: provided-interface=DiagnosticInfo
      Event_Ga_TmSpdSyncFailed: provided-interface=DiagnosticMonitor
      EvtInfo_INV_RSLVR_EXCT_ELEC_LO: provided-interface=DiagnosticInfo
      Event_INV_RSLVR_EXCT_ELEC_LO: provided-interface=DiagnosticMonitor
      EvtInfo_VCEvEcmPropXevFr06Tioutd: provided-interface=DiagnosticInfo
      Event_VCEvEcmPropXevFr06Tioutd: provided-interface=DiagnosticMonitor
      EvtInfo_VcEvCntrWhlMotSysTqAllwd: provided-interface=DiagnosticInfo
      Event_VcEvCntrWhlMotSysTqAllwd: provided-interface=DiagnosticMonitor
      EvtInfo_INV_UHVDC_1_ELEC_HI: provided-interface=DiagnosticInfo
      Event_INV_UHVDC_1_ELEC_HI: provided-interface=DiagnosticMonitor
      EvtInfo_INV_EM_STATOR_TEMP2_ELE_FLT: provided-interface=DiagnosticInfo
      Event_INV_EM_STATOR_TEMP2_ELE_FLT: provided-interface=DiagnosticMonitor
      EvtInfo_AURIX_RST_SNG: provided-interface=DiagnosticInfo
      Event_AURIX_RST_SNG: provided-interface=DiagnosticMonitor
      EvtInfo_VCEvEcmPropFr24MgmFr01Tioutd: provided-interface=DiagnosticInfo
      Event_VCEvEcmPropFr24MgmFr01Tioutd: provided-interface=DiagnosticMonitor
      EvtInfo_INV_RSLVR_COS_ELEC_OPEN: provided-interface=DiagnosticInfo
      Event_INV_RSLVR_COS_ELEC_OPEN: provided-interface=DiagnosticMonitor
      EvtInfo_INV_IAC_V_ELEC_LO: provided-interface=DiagnosticInfo
      Event_INV_IAC_V_ELEC_LO: provided-interface=DiagnosticMonitor
      EvtInfo_INV_IAC_W_OFFS: provided-interface=DiagnosticInfo
      Event_INV_IAC_W_OFFS: provided-interface=DiagnosticMonitor
      EvtInfo_INV_EM_STATOR_TEMP2_GRDT: provided-interface=DiagnosticInfo
      Event_INV_EM_STATOR_TEMP2_GRDT: provided-interface=DiagnosticMonitor
      EvtInfo_INV_EM_OVRSPD_HWP: provided-interface=DiagnosticInfo
      Event_INV_EM_OVRSPD_HWP: provided-interface=DiagnosticMonitor
      EvtInfo_CU_TEMP_HWP: provided-interface=DiagnosticInfo
      Event_CU_TEMP_HWP: provided-interface=DiagnosticMonitor
      EvtInfo_INV_UHVDC_1_RNG_HI: provided-interface=DiagnosticInfo
      Event_INV_UHVDC_1_RNG_HI: provided-interface=DiagnosticMonitor
      EvtInfo_VcEvEMPerfPlaus: provided-interface=DiagnosticInfo
      Event_VcEvEMPerfPlaus: provided-interface=DiagnosticMonitor
      EvtInfo_VCEvVddmPropFr18Tioutd: provided-interface=DiagnosticInfo
      Event_VCEvVddmPropFr18Tioutd: provided-interface=DiagnosticMonitor
      EvtInfo_INV_IAC_U_ELEC_HWP: provided-interface=DiagnosticInfo
      Event_INV_IAC_U_ELEC_HWP: provided-interface=DiagnosticMonitor
      EvtInfo_VCEvVddmPropFr15Tioutd: provided-interface=DiagnosticInfo
      Event_VCEvVddmPropFr15Tioutd: provided-interface=DiagnosticMonitor
      EvtInfo_Ga_GADisengageFailure: provided-interface=DiagnosticInfo
      Event_Ga_GADisengageFailure: provided-interface=DiagnosticMonitor
      EvtInfo_CU_TEMP2_RNG_LO: provided-interface=DiagnosticInfo
      Event_CU_TEMP2_RNG_LO: provided-interface=DiagnosticMonitor
      EvtInfo_INV_RSLVR_SIN_ELEC_OPEN: provided-interface=DiagnosticInfo
      Event_INV_RSLVR_SIN_ELEC_OPEN: provided-interface=DiagnosticMonitor
      EvtInfo_VcEvChkSum: provided-interface=DiagnosticInfo
      Event_VcEvChkSum: provided-interface=DiagnosticMonitor
      EvtInfo_PS_P5_UC_FLT: provided-interface=DiagnosticInfo
      Event_PS_P5_UC_FLT: provided-interface=DiagnosticMonitor
      EvtInfo_INV_RSLVR_COS_ELEC_FLT: provided-interface=DiagnosticInfo
      Event_INV_RSLVR_COS_ELEC_FLT: provided-interface=DiagnosticMonitor
      EvtInfo_INV_IAC_W_RNG_HI: provided-interface=DiagnosticInfo
      Event_INV_IAC_W_RNG_HI: provided-interface=DiagnosticMonitor
      EvtInfo_PS_ECUSUPPLY_HIGH: provided-interface=DiagnosticInfo
      Event_PS_ECUSUPPLY_HIGH: provided-interface=DiagnosticMonitor
      EvtInfo_VCEvEcmPropFr05Tioutd: provided-interface=DiagnosticInfo
      Event_VCEvEcmPropFr05Tioutd: provided-interface=DiagnosticMonitor
      EvtInfo_PS_ECUSUPPLY_LOW: provided-interface=DiagnosticInfo
      Event_PS_ECUSUPPLY_LOW: provided-interface=DiagnosticMonitor
      EvtInfo_VcEvChkSumHvSysRlySts: provided-interface=DiagnosticInfo
      Event_VcEvChkSumHvSysRlySts: provided-interface=DiagnosticMonitor
      EvtInfo_VcEvMonMode: provided-interface=DiagnosticInfo
      Event_VcEvMonMode: provided-interface=DiagnosticMonitor
      EvtInfo_INV_IAC_OC_SWP: provided-interface=DiagnosticInfo
      Event_INV_IAC_OC_SWP: provided-interface=DiagnosticMonitor
      EvtInfo_INV_IMMO_AUTHFAIL: provided-interface=DiagnosticInfo
      Event_INV_IMMO_AUTHFAIL: provided-interface=DiagnosticMonitor
      EvtInfo_PA_OpenCirc_FLT: provided-interface=DiagnosticInfo
      Event_PA_OpenCirc_FLT: provided-interface=DiagnosticMonitor
      EvtInfo_INV_IAC_V_ELEC_HI: provided-interface=DiagnosticInfo
      Event_INV_IAC_V_ELEC_HI: provided-interface=DiagnosticMonitor
      EvtInfo_VCEvEcmPropFr04Tioutd: provided-interface=DiagnosticInfo
      Event_VCEvEcmPropFr04Tioutd: provided-interface=DiagnosticMonitor
      EvtInfo_VcEvMonTrqActPlaus: provided-interface=DiagnosticInfo
      Event_VcEvMonTrqActPlaus: provided-interface=DiagnosticMonitor
      EvtInfo_VcEvMonTrqAct: provided-interface=DiagnosticInfo
      Event_VcEvMonTrqAct: provided-interface=DiagnosticMonitor
      EvtInfo_INV_RSLVR_COS_ELEC_LO: provided-interface=DiagnosticInfo
      Event_INV_RSLVR_COS_ELEC_LO: provided-interface=DiagnosticMonitor
      EvtInfo_INV_COOLT_INLET_TEMP_HWP: provided-interface=DiagnosticInfo
      Event_INV_COOLT_INLET_TEMP_HWP: provided-interface=DiagnosticMonitor
      EvtInfo_VCEvEcmPropFr11Tioutd: provided-interface=DiagnosticInfo
      Event_VCEvEcmPropFr11Tioutd: provided-interface=DiagnosticMonitor
      EvtInfo_PS_KL30_RNG_HI: provided-interface=DiagnosticInfo
      Event_PS_KL30_RNG_HI: provided-interface=DiagnosticMonitor
      EvtInfo_INV_IAC_OC_HWP: provided-interface=DiagnosticInfo
      Event_INV_IAC_OC_HWP: provided-interface=DiagnosticMonitor
      EvtInfo_INV_RSLVR_COS_RNG_HI: provided-interface=DiagnosticInfo
      Event_INV_RSLVR_COS_RNG_HI: provided-interface=DiagnosticMonitor
      EvtInfo_INV_IAC_U_ELEC_HI: provided-interface=DiagnosticInfo
      Event_INV_IAC_U_ELEC_HI: provided-interface=DiagnosticMonitor
      EvtInfo_INV_IAC_V_RNG_LO: provided-interface=DiagnosticInfo
      Event_INV_IAC_V_RNG_LO: provided-interface=DiagnosticMonitor
      EvtInfo_INV_IAC_U_RNG_HI: provided-interface=DiagnosticInfo
      Event_INV_IAC_U_RNG_HI: provided-interface=DiagnosticMonitor
      EvtInfo_VCEvEcmPropFr25Tioutd: provided-interface=DiagnosticInfo
      Event_VCEvEcmPropFr25Tioutd: provided-interface=DiagnosticMonitor
      EvtInfo_INV_IGBT_TEMP_W_RNG_LO: provided-interface=DiagnosticInfo
      Event_INV_IGBT_TEMP_W_RNG_LO: provided-interface=DiagnosticMonitor
      EvtInfo_PSnsr_RNG_NOK: provided-interface=DiagnosticInfo
      Event_PSnsr_RNG_NOK: provided-interface=DiagnosticMonitor
      EvtInfo_INV_RSLVR_COS_RNG_NOK: provided-interface=DiagnosticInfo
      Event_INV_RSLVR_COS_RNG_NOK: provided-interface=DiagnosticMonitor
      EvtInfo_PS_DRVB_Fault: provided-interface=DiagnosticInfo
      Event_PS_DRVB_Fault: provided-interface=DiagnosticMonitor
      EvtInfo_INV_CU_TEMP1_RNG_NOK: provided-interface=DiagnosticInfo
      Event_INV_CU_TEMP1_RNG_NOK: provided-interface=DiagnosticMonitor
      EvtInfo_VcEvCntr: provided-interface=DiagnosticInfo
      Event_VcEvCntr: provided-interface=DiagnosticMonitor
      EvtInfo_INV_RSLVR_SIN_AMP: provided-interface=DiagnosticInfo
      Event_INV_RSLVR_SIN_AMP: provided-interface=DiagnosticMonitor
      EvtInfo_INV_UHVDC_2_RNG_HI: provided-interface=DiagnosticInfo
      Event_INV_UHVDC_2_RNG_HI: provided-interface=DiagnosticMonitor
      EvtInfo_INV_IGBT_TEMP_U_GRDT: provided-interface=DiagnosticInfo
      Event_INV_IGBT_TEMP_U_GRDT: provided-interface=DiagnosticMonitor
      EvtInfo_MON_TQ_PLAUS_PWR_MDL: provided-interface=DiagnosticInfo
      Event_MON_TQ_PLAUS_PWR_MDL: provided-interface=DiagnosticMonitor
      EvtInfo_INV_IGBT_TEMP_W_PLAUS: provided-interface=DiagnosticInfo
      Event_INV_IGBT_TEMP_W_PLAUS: provided-interface=DiagnosticMonitor
      EvtInfo_PS_BLDC_UV_FLT: provided-interface=DiagnosticInfo
      Event_PS_BLDC_UV_FLT: provided-interface=DiagnosticMonitor
      EvtInfo_INV_IAC_V_OFFS: provided-interface=DiagnosticInfo
      Event_INV_IAC_V_OFFS: provided-interface=DiagnosticMonitor
      EvtInfo_INV_RSLVR_EXCT_FREQ_RNG_NOK: provided-interface=DiagnosticInfo
      Event_INV_RSLVR_EXCT_FREQ_RNG_NOK: provided-interface=DiagnosticMonitor
      EvtInfo_PS_KL30_RNG_LO: provided-interface=DiagnosticInfo
      Event_PS_KL30_RNG_LO: provided-interface=DiagnosticMonitor
      EvtInfo_INV_RSLVR_COS_RNG_LO: provided-interface=DiagnosticInfo
      Event_INV_RSLVR_COS_RNG_LO: provided-interface=DiagnosticMonitor
      EvtInfo_PSnsr_ELE_FLT: provided-interface=DiagnosticInfo
      Event_PSnsr_ELE_FLT: provided-interface=DiagnosticMonitor
      EvtInfo_INV_RSLVR_SIN_COS_PLAUS_AMP: provided-interface=DiagnosticInfo
      Event_INV_RSLVR_SIN_COS_PLAUS_AMP: provided-interface=DiagnosticMonitor
      EvtInfo_INV_IAC_U_ELEC_LO: provided-interface=DiagnosticInfo
      Event_INV_IAC_U_ELEC_LO: provided-interface=DiagnosticMonitor
      EvtInfo_INV_RSLVR_EXCT_ELEC_HI: provided-interface=DiagnosticInfo
      Event_INV_RSLVR_EXCT_ELEC_HI: provided-interface=DiagnosticMonitor
      EvtInfo_INV_IAC_U_RNG_LO: provided-interface=DiagnosticInfo
      Event_INV_IAC_U_RNG_LO: provided-interface=DiagnosticMonitor
      EvtInfo_INV_IAC_V_RNG_HI: provided-interface=DiagnosticInfo
      Event_INV_IAC_V_RNG_HI: provided-interface=DiagnosticMonitor
      EvtInfo_INV_IGBT_TEMP_U_PLAUS: provided-interface=DiagnosticInfo
      Event_INV_IGBT_TEMP_U_PLAUS: provided-interface=DiagnosticMonitor
      EvtInfo_INV_RSLVR_OFFS_DFT: provided-interface=DiagnosticInfo
      Event_INV_RSLVR_OFFS_DFT: provided-interface=DiagnosticMonitor
      EvtInfo_Ga_MoveOverThd: provided-interface=DiagnosticInfo
      Event_Ga_MoveOverThd: provided-interface=DiagnosticMonitor
      EvtInfo_VcEvMonIPH: provided-interface=DiagnosticInfo
      Event_VcEvMonIPH: provided-interface=DiagnosticMonitor
      EvtInfo_INV_RSLVR_HW_FLT: provided-interface=DiagnosticInfo
      Event_INV_RSLVR_HW_FLT: provided-interface=DiagnosticMonitor
      EvtInfo_INV_RSLVR_SIN_ELEC_LO: provided-interface=DiagnosticInfo
      Event_INV_RSLVR_SIN_ELEC_LO: provided-interface=DiagnosticMonitor
      EvtInfo_INV_IAC_W_AMP: provided-interface=DiagnosticInfo
      Event_INV_IAC_W_AMP: provided-interface=DiagnosticMonitor
      EvtInfo_VCC_OverVoltage: provided-interface=DiagnosticInfo
      Event_VCC_OverVoltage: provided-interface=DiagnosticMonitor
      EvtInfo_PS_BLDC_OV_FLT: provided-interface=DiagnosticInfo
      Event_PS_BLDC_OV_FLT: provided-interface=DiagnosticMonitor
      EvtInfo_AURIX_EEPROM_FLT: provided-interface=DiagnosticInfo
      Event_AURIX_EEPROM_FLT: provided-interface=DiagnosticMonitor
      EvtInfo_FS_MONITIOR_ASC_FW_FLT: provided-interface=DiagnosticInfo
      Event_FS_MONITIOR_ASC_FW_FLT: provided-interface=DiagnosticMonitor
      EvtInfo_VCEvSrsPropFr02Tioutd: provided-interface=DiagnosticInfo
      Event_VCEvSrsPropFr02Tioutd: provided-interface=DiagnosticMonitor
      EvtInfo_VcEvMonErrMode: provided-interface=DiagnosticInfo
      Event_VcEvMonErrMode: provided-interface=DiagnosticMonitor
      EvtInfo_AURIX_RST_MPL: provided-interface=DiagnosticInfo
      Event_AURIX_RST_MPL: provided-interface=DiagnosticMonitor
      EvtInfo_VcEvNodeMisECM: provided-interface=DiagnosticInfo
      Event_VcEvNodeMisECM: provided-interface=DiagnosticMonitor
      EvtInfo_PS_KL30_PLAUS: provided-interface=DiagnosticInfo
      Event_PS_KL30_PLAUS: provided-interface=DiagnosticMonitor
      EvtInfo_INV_IAC_W_ELEC_HI: provided-interface=DiagnosticInfo
      Event_INV_IAC_W_ELEC_HI: provided-interface=DiagnosticMonitor
      EvtInfo_VCEvVddmPropFr19Tioutd: provided-interface=DiagnosticInfo
      Event_VCEvVddmPropFr19Tioutd: provided-interface=DiagnosticMonitor
      EvtInfo_INV_TEMP_DCHA_HW: provided-interface=DiagnosticInfo
      Event_INV_TEMP_DCHA_HW: provided-interface=DiagnosticMonitor
      EvtInfo_VcEvPropCANGlbTiOutd: provided-interface=DiagnosticInfo
      Event_VcEvPropCANGlbTiOutd: provided-interface=DiagnosticMonitor
      EvtInfo_INV_EM_STATOR_TEMP2_RNG_NOK: provided-interface=DiagnosticInfo
      Event_INV_EM_STATOR_TEMP2_RNG_NOK: provided-interface=DiagnosticMonitor
      EvtInfo_INV_UHVDC_OV_HWP: provided-interface=DiagnosticInfo
      Event_INV_UHVDC_OV_HWP: provided-interface=DiagnosticMonitor
      EvtInfo_Ga_FindEngleAngleFailed: provided-interface=DiagnosticInfo
      Event_Ga_FindEngleAngleFailed: provided-interface=DiagnosticMonitor
      EvtInfo_VcEvMonTrqCmp: provided-interface=DiagnosticInfo
      Event_VcEvMonTrqCmp: provided-interface=DiagnosticMonitor
      EvtInfo_INV_IGBT_TEMP_V_RNG_LO: provided-interface=DiagnosticInfo
      Event_INV_IGBT_TEMP_V_RNG_LO: provided-interface=DiagnosticMonitor
      EvtInfo_INV_CONTROL_LIMIT: provided-interface=DiagnosticInfo
      Event_INV_CONTROL_LIMIT: provided-interface=DiagnosticMonitor
      EvtInfo_COM_CarConfigErr: provided-interface=DiagnosticInfo
      Event_COM_CarConfigErr: provided-interface=DiagnosticMonitor
      EvtInfo_VCEvEcmPropFr08Tioutd: provided-interface=DiagnosticInfo
      Event_VCEvEcmPropFr08Tioutd: provided-interface=DiagnosticMonitor
      EvtInfo_CU_TEMP1_RNG_LO: provided-interface=DiagnosticInfo
      Event_CU_TEMP1_RNG_LO: provided-interface=DiagnosticMonitor
      EvtInfo_INV_EM_STATOR_TEMP2_RNG_SWT: provided-interface=DiagnosticInfo
      Event_INV_EM_STATOR_TEMP2_RNG_SWT: provided-interface=DiagnosticMonitor
      EvtInfo_GA_BLDC_POS_FLT: provided-interface=DiagnosticInfo
      Event_GA_BLDC_POS_FLT: provided-interface=DiagnosticMonitor
      EvtInfo_PS_WhlSnsr_FLT: provided-interface=DiagnosticInfo
      Event_PS_WhlSnsr_FLT: provided-interface=DiagnosticMonitor
      EvtInfo_INV_EM_STATOR_TEMP_RNG_LO: provided-interface=DiagnosticInfo
      Event_INV_EM_STATOR_TEMP_RNG_LO: provided-interface=DiagnosticMonitor
      EvtInfo_INV_RSLVR_SIN_ELEC_HI: provided-interface=DiagnosticInfo
      Event_INV_RSLVR_SIN_ELEC_HI: provided-interface=DiagnosticMonitor
      EvtInfo_INV_RSLVR_SIN_COS_PLAUS: provided-interface=DiagnosticInfo
      Event_INV_RSLVR_SIN_COS_PLAUS: provided-interface=DiagnosticMonitor
      EvtInfo_INV_RSLVR_COS_AMP: provided-interface=DiagnosticInfo
      Event_INV_RSLVR_COS_AMP: provided-interface=DiagnosticMonitor
      EvtInfo_INV_GATE_DRVR_BOT_HWP: provided-interface=DiagnosticInfo
      Event_INV_GATE_DRVR_BOT_HWP: provided-interface=DiagnosticMonitor
      EvtInfo_Eg_HallVolWrong: provided-interface=DiagnosticInfo
      Event_Eg_HallVolWrong: provided-interface=DiagnosticMonitor
      EvtInfo_INV_RSLVR_EXCT_RNG_NOK: provided-interface=DiagnosticInfo
      Event_INV_RSLVR_EXCT_RNG_NOK: provided-interface=DiagnosticMonitor
      EvtInfo_PA_OpenCirc: provided-interface=DiagnosticInfo
      Event_PA_OpenCirc: provided-interface=DiagnosticMonitor
      EvtInfo_INV_RSLVR_COS_ELEC_HI: provided-interface=DiagnosticInfo
      Event_INV_RSLVR_COS_ELEC_HI: provided-interface=DiagnosticMonitor
      EvtInfo_VcEvCntrHvSysRlySts: provided-interface=DiagnosticInfo
      Event_VcEvCntrHvSysRlySts: provided-interface=DiagnosticMonitor
      EvtInfo_CRASH_DTC: provided-interface=DiagnosticInfo
      Event_CRASH_DTC: provided-interface=DiagnosticMonitor
      EvtInfo_INV_IGBT_TEMP_W_RNG_HI: provided-interface=DiagnosticInfo
      Event_INV_IGBT_TEMP_W_RNG_HI: provided-interface=DiagnosticMonitor
      EvtInfo_VCEvBecmPropFr02Tioutd: provided-interface=DiagnosticInfo
      Event_VCEvBecmPropFr02Tioutd: provided-interface=DiagnosticMonitor
      EvtInfo_INV_IGBT_TEMP_W_GRDT: provided-interface=DiagnosticInfo
      Event_INV_IGBT_TEMP_W_GRDT: provided-interface=DiagnosticMonitor
      EvtInfo_EXT_UC_SPI_FLT: provided-interface=DiagnosticInfo
      Event_EXT_UC_SPI_FLT: provided-interface=DiagnosticMonitor
      EvtInfo_INV_IAC_V_ELEC_HWP_001: provided-interface=DiagnosticInfo
      Event_INV_IAC_V_ELEC_HWP_001: provided-interface=DiagnosticMonitor
      EvtInfo_VcEvChkSumWhlMotSysTqAllwd: provided-interface=DiagnosticInfo
      Event_VcEvChkSumWhlMotSysTqAllwd: provided-interface=DiagnosticMonitor
      EvtInfo_FS_MONITIOR_ASC_FLT: provided-interface=DiagnosticInfo
      Event_FS_MONITIOR_ASC_FLT: provided-interface=DiagnosticMonitor
      EvtInfo_INV_IAC_V_AMP: provided-interface=DiagnosticInfo
      Event_INV_IAC_V_AMP: provided-interface=DiagnosticMonitor
      EvtInfo_INV_IAC_W_ELEC_LO: provided-interface=DiagnosticInfo
      Event_INV_IAC_W_ELEC_LO: provided-interface=DiagnosticMonitor
      EvtInfo_VCEvVddmPropFr08Tioutd_001: provided-interface=DiagnosticInfo
      Event_VCEvVddmPropFr08Tioutd_001: provided-interface=DiagnosticMonitor
      EvtInfo_PS_P12_RES_FLT: provided-interface=DiagnosticInfo
      Event_PS_P12_RES_FLT: provided-interface=DiagnosticMonitor
      EvtInfo_INV_RSLVR_SIN_RNG_LO: provided-interface=DiagnosticInfo
      Event_INV_RSLVR_SIN_RNG_LO: provided-interface=DiagnosticMonitor
      EvtInfo_CU_TEMP_HW_FLT: provided-interface=DiagnosticInfo
      Event_CU_TEMP_HW_FLT: provided-interface=DiagnosticMonitor
      EvtInfo_VCEvEcmPropFr02MgmFr00Tioutd: provided-interface=DiagnosticInfo
      Event_VCEvEcmPropFr02MgmFr00Tioutd: provided-interface=DiagnosticMonitor
      EvtInfo_PS_KL15_RNG_HI: provided-interface=DiagnosticInfo
      Event_PS_KL15_RNG_HI: provided-interface=DiagnosticMonitor
      EvtInfo_VCEvVddmPropFr17Tioutd: provided-interface=DiagnosticInfo
      Event_VCEvVddmPropFr17Tioutd: provided-interface=DiagnosticMonitor
      EvtInfo_VcEvChkSumCrashStsSafe: provided-interface=DiagnosticInfo
      Event_VcEvChkSumCrashStsSafe: provided-interface=DiagnosticMonitor
      EvtInfo_DiagC_ClutchService: provided-interface=DiagnosticInfo
      Event_DiagC_ClutchService: provided-interface=DiagnosticMonitor
      EvtInfo_INV_EM_STATOR_TEMP_RNG_HI: provided-interface=DiagnosticInfo
      Event_INV_EM_STATOR_TEMP_RNG_HI: provided-interface=DiagnosticMonitor
      EvtInfo_INV_RSLVR_OFFS_OUT_RANG: provided-interface=DiagnosticInfo
      Event_INV_RSLVR_OFFS_OUT_RANG: provided-interface=DiagnosticMonitor
      EvtInfo_INV_EM_STATOR_TEMP2_RNG_LO: provided-interface=DiagnosticInfo
      Event_INV_EM_STATOR_TEMP2_RNG_LO: provided-interface=DiagnosticMonitor
      EvtInfo_VcEvMonISAR: provided-interface=DiagnosticInfo
      Event_VcEvMonISAR: provided-interface=DiagnosticMonitor
      EvtInfo_GA_BLDC_FLT: provided-interface=DiagnosticInfo
      Event_GA_BLDC_FLT: provided-interface=DiagnosticMonitor
      EvtInfo_INV_RSLVR_EXCT_ELEC_OPEN: provided-interface=DiagnosticInfo
      Event_INV_RSLVR_EXCT_ELEC_OPEN: provided-interface=DiagnosticMonitor
      EvtInfo_INV_RSLVR_EXCT_PLAUS: provided-interface=DiagnosticInfo
      Event_INV_RSLVR_EXCT_PLAUS: provided-interface=DiagnosticMonitor
      EvtInfo_PS_P15_U_FLT: provided-interface=DiagnosticInfo
      Event_PS_P15_U_FLT: provided-interface=DiagnosticMonitor
      EvtInfo_INV_EM_STATOR_TEMP_RNG_SWT: provided-interface=DiagnosticInfo
      Event_INV_EM_STATOR_TEMP_RNG_SWT: provided-interface=DiagnosticMonitor
      EvtInfo_INV_UHVDC_OV_SWP: provided-interface=DiagnosticInfo
      Event_INV_UHVDC_OV_SWP: provided-interface=DiagnosticMonitor
      EvtInfo_AURIX_HW_FLT: provided-interface=DiagnosticInfo
      Event_AURIX_HW_FLT: provided-interface=DiagnosticMonitor
      EvtInfo_INV_GATE_DRVR_TOP_HWP: provided-interface=DiagnosticInfo
      Event_INV_GATE_DRVR_TOP_HWP: provided-interface=DiagnosticMonitor
      EvtInfo_INV_ACTV_DCHA_HW: provided-interface=DiagnosticInfo
      Event_INV_ACTV_DCHA_HW: provided-interface=DiagnosticMonitor
      EvtInfo_INV_IGBT_TEMP_HWP: provided-interface=DiagnosticInfo
      Event_INV_IGBT_TEMP_HWP: provided-interface=DiagnosticMonitor
      EvtInfo_INV_RSLVR_SIN_ELEC_FLT: provided-interface=DiagnosticInfo
      Event_INV_RSLVR_SIN_ELEC_FLT: provided-interface=DiagnosticMonitor
      EvtInfo_CU_TEMP2_RNG_HI: provided-interface=DiagnosticInfo
      Event_CU_TEMP2_RNG_HI: provided-interface=DiagnosticMonitor
      EvtInfo_INV_IAC_PHA_LOSS_MPL: provided-interface=DiagnosticInfo
      Event_INV_IAC_PHA_LOSS_MPL: provided-interface=DiagnosticMonitor
      EvtInfo_INV_IAC_U_AMP: provided-interface=DiagnosticInfo
      Event_INV_IAC_U_AMP: provided-interface=DiagnosticMonitor
      EvtInfo_PSnsr_GRADT_Flt: provided-interface=DiagnosticInfo
      Event_PSnsr_GRADT_Flt: provided-interface=DiagnosticMonitor
      EvtInfo_AURIX_WATHDOG_FLT: provided-interface=DiagnosticInfo
      Event_AURIX_WATHDOG_FLT: provided-interface=DiagnosticMonitor
      EvtInfo_VcEvNodeMisBECM: provided-interface=DiagnosticInfo
      Event_VcEvNodeMisBECM: provided-interface=DiagnosticMonitor
      EvtInfo_INV_UHVDC_UV_HWP: provided-interface=DiagnosticInfo
      Event_INV_UHVDC_UV_HWP: provided-interface=DiagnosticMonitor
      EvtInfo_VcEvMonESpd: provided-interface=DiagnosticInfo
      Event_VcEvMonESpd: provided-interface=DiagnosticMonitor
      EvtInfo_COM_NotConfig: provided-interface=DiagnosticInfo
      Event_COM_NotConfig: provided-interface=DiagnosticMonitor
      EvtInfo_INV_RSLVR_SIN_RNG_HI: provided-interface=DiagnosticInfo
      Event_INV_RSLVR_SIN_RNG_HI: provided-interface=DiagnosticMonitor
      EvtInfo_INV_IGBT_TEMP_U_RNG_HI: provided-interface=DiagnosticInfo
      Event_INV_IGBT_TEMP_U_RNG_HI: provided-interface=DiagnosticMonitor
      EvtInfo_VcEvMonMode_001: provided-interface=DiagnosticInfo
      Event_VcEvMonMode_001: provided-interface=DiagnosticMonitor
      EvtInfo_PA_ACTION_FLT: provided-interface=DiagnosticInfo
      Event_PA_ACTION_FLT: provided-interface=DiagnosticMonitor
      EvtInfo_INV_IAC_V_ELEC_HWP: provided-interface=DiagnosticInfo
      Event_INV_IAC_V_ELEC_HWP: provided-interface=DiagnosticMonitor
      EvtInfo_CU_TEMP_HW_FLT_001: provided-interface=DiagnosticInfo
      Event_CU_TEMP_HW_FLT_001: provided-interface=DiagnosticMonitor
      EvtInfo_VCC_UnderVoltage: provided-interface=DiagnosticInfo
      Event_VCC_UnderVoltage: provided-interface=DiagnosticMonitor
      EvtInfo_VcEvTsttrPlaus: provided-interface=DiagnosticInfo
      Event_VcEvTsttrPlaus: provided-interface=DiagnosticMonitor
      EvtInfo_INV_RSLVR_EXCT_ELEC_FLT: provided-interface=DiagnosticInfo
      Event_INV_RSLVR_EXCT_ELEC_FLT: provided-interface=DiagnosticMonitor
      EvtInfo_INV_RSLVR_EXCT_RNG_LO: provided-interface=DiagnosticInfo
      Event_INV_RSLVR_EXCT_RNG_LO: provided-interface=DiagnosticMonitor
      EvtInfo_INV_EM_STATOR_TEMP2_RNG_HI: provided-interface=DiagnosticInfo
      Event_INV_EM_STATOR_TEMP2_RNG_HI: provided-interface=DiagnosticMonitor
      EvtInfo_INV_SHUT_OFF_PAH_START_UP: provided-interface=DiagnosticInfo
      Event_INV_SHUT_OFF_PAH_START_UP: provided-interface=DiagnosticMonitor
      EvtInfo_VCEvVddmPropFr08Tioutd: provided-interface=DiagnosticInfo
      Event_VCEvVddmPropFr08Tioutd: provided-interface=DiagnosticMonitor
      EvtInfo_INV_RSLVR_EXCT_OC_HWP_001: provided-interface=DiagnosticInfo
      Event_INV_RSLVR_EXCT_OC_HWP_001: provided-interface=DiagnosticMonitor
      EvtInfo_INV_RSLVR_EXCT_OC_HWP_002: provided-interface=DiagnosticInfo
      Event_INV_RSLVR_EXCT_OC_HWP_002: provided-interface=DiagnosticMonitor
      EvtInfo_INV_EM_STATOR_TEMP_ELE_FLT: provided-interface=DiagnosticInfo
      Event_INV_EM_STATOR_TEMP_ELE_FLT: provided-interface=DiagnosticMonitor
      EvtInfo_INV_INTERLOCK_FLT: provided-interface=DiagnosticInfo
      Event_INV_INTERLOCK_FLT: provided-interface=DiagnosticMonitor
      EvtInfo_Ga_ZeroFindDistanFailure: provided-interface=DiagnosticInfo
      Event_Ga_ZeroFindDistanFailure: provided-interface=DiagnosticMonitor
      EvtInfo_PLOCK_Current_RNG_OUT: provided-interface=DiagnosticInfo
      Event_PLOCK_Current_RNG_OUT: provided-interface=DiagnosticMonitor
      EvtInfo_VCEvVddmPropFr05Tioutd: provided-interface=DiagnosticInfo
      Event_VCEvVddmPropFr05Tioutd: provided-interface=DiagnosticMonitor
      EvtInfo_INV_IGBT_TEMP_V_GRDT: provided-interface=DiagnosticInfo
      Event_INV_IGBT_TEMP_V_GRDT: provided-interface=DiagnosticMonitor
      EvtInfo_PS_5V_Fault: provided-interface=DiagnosticInfo
      Event_PS_5V_Fault: provided-interface=DiagnosticMonitor
      EvtInfo_VcEvCntrCrashStsSafe: provided-interface=DiagnosticInfo
      Event_VcEvCntrCrashStsSafe: provided-interface=DiagnosticMonitor
      EvtInfo_INV_EM_STATOR_TEMP_GRDT: provided-interface=DiagnosticInfo
      Event_INV_EM_STATOR_TEMP_GRDT: provided-interface=DiagnosticMonitor
      EvtInfo_PS_P15_V_FLT: provided-interface=DiagnosticInfo
      Event_PS_P15_V_FLT: provided-interface=DiagnosticMonitor
      EvtInfo_INV_EM_STATOR_TEMP_RNG_NOK: provided-interface=DiagnosticInfo
      Event_INV_EM_STATOR_TEMP_RNG_NOK: provided-interface=DiagnosticMonitor
      EvtInfo_INV_RSLVR_SIN_RNG_NOK: provided-interface=DiagnosticInfo
      Event_INV_RSLVR_SIN_RNG_NOK: provided-interface=DiagnosticMonitor
      EvtInfo_INV_IAC_U_OFFS: provided-interface=DiagnosticInfo
      Event_INV_IAC_U_OFFS: provided-interface=DiagnosticMonitor
      EvtInfo_PS_KL30_BACKUP_FLT: provided-interface=DiagnosticInfo
      Event_PS_KL30_BACKUP_FLT: provided-interface=DiagnosticMonitor
      EvtInfo_INV_IGBT_TEMP_U_RNG_LO: provided-interface=DiagnosticInfo
      Event_INV_IGBT_TEMP_U_RNG_LO: provided-interface=DiagnosticMonitor
      EvtInfo_INV_EM_STATOR_TEMP_HWP: provided-interface=DiagnosticInfo
      Event_INV_EM_STATOR_TEMP_HWP: provided-interface=DiagnosticMonitor
      EvtInfo_CU_TEMP1_RNG_HI: provided-interface=DiagnosticInfo
      Event_CU_TEMP1_RNG_HI: provided-interface=DiagnosticMonitor
      EvtInfo_INV_IGBT_TEMP_V_RNG_HI: provided-interface=DiagnosticInfo
      Event_INV_IGBT_TEMP_V_RNG_HI: provided-interface=DiagnosticMonitor
      EvtInfo_VcEvNodeMisVDDM: provided-interface=DiagnosticInfo
      Event_VcEvNodeMisVDDM: provided-interface=DiagnosticMonitor
      EvtInfo_INV_UHVDC_PLAUS: provided-interface=DiagnosticInfo
      Event_INV_UHVDC_PLAUS: provided-interface=DiagnosticMonitor
      EvtInfo_INV_QUIESCENT_FLT: provided-interface=DiagnosticInfo
      Event_INV_QUIESCENT_FLT: provided-interface=DiagnosticMonitor
      EvtInfo_INV_RSLVR_EXCT_RNG_HI: provided-interface=DiagnosticInfo
      Event_INV_RSLVR_EXCT_RNG_HI: provided-interface=DiagnosticMonitor
      GeneralEvtInfo: provided-interface=GeneralDiagnosticInfo
    73 x require port:
      CBReadData_DTCStatusindicator30_DTCStatusindicator30: required-interface=CSDataServices_DTCStatusindicator30_DTCStatusindicator30
      CBReadData_DID_0xe310_DID_E310_IEMMGM_Derating_Status: required-interface=CSDataServices_DID_0xe310_DID_E310_IEMMGM_Derating_Status
      CBReadData_DID_0xe301_DID_E301_HVDC_Current_: required-interface=CSDataServices_DID_0xe301_DID_E301_HVDC_Current_
      CBReadData_DID_0xe305_DID_E305_Inverter_IGBT_Junction_Temp: required-interface=CSDataServices_DID_0xe305_DID_E305_Inverter_IGBT_Junction_Temp
      CBReadData_DID_0xe339_DID_E339_d_axis_voltage: required-interface=CSDataServices_DID_0xe339_DID_E339_d_axis_voltage
      CBReadData_DID_0xe307_DID_E307_System_Mode: required-interface=CSDataServices_DID_0xe307_DID_E307_System_Mode
      CBReadData_DID_0xe357_DID_E357_Resolve_compensated_angle: required-interface=CSDataServices_DID_0xe357_DID_E357_Resolve_compensated_angle
      CBReadData_DID_0xe308_DID_E308_ECM_Torque_Request: required-interface=CSDataServices_DID_0xe308_DID_E308_ECM_Torque_Request
      CBReadData_DID_0xe335_DID_E335_d_axis_current_setpoint: required-interface=CSDataServices_DID_0xe335_DID_E335_d_axis_current_setpoint
      CBReadData_DID_0xe319_DID_E319_Torque_Direction: required-interface=CSDataServices_DID_0xe319_DID_E319_Torque_Direction
      CBReadData_DID_0xe309_DID_E309_ECM_Mode_Request: required-interface=CSDataServices_DID_0xe309_DID_E309_ECM_Mode_Request
      CBReadData_DID_0xdd0a_DID_DD0A_Usage_Mode: required-interface=CSDataServices_DID_0xdd0a_DID_DD0A_Usage_Mode
      CBReadData_DID_0xeec3_DID_EEC3_ECU_power_supply_Voltage: required-interface=CSDataServices_DID_0xeec3_DID_EEC3_ECU_power_supply_Voltage
      CBReadData_DID_0xdd00_DID_DD00_Global_Real_Time: required-interface=CSDataServices_DID_0xdd00_DID_DD00_Global_Real_Time
      CBReadData_DID_0xee9e_DID_EE9E_Transient_Phase_Current_C: required-interface=CSDataServices_DID_0xee9e_DID_EE9E_Transient_Phase_Current_C
      CBReadData_DID_0xe333_2002_Hu: required-interface=CSDataServices_DID_0xe333_2002_Hu
      CBReadData_DID_0xe333_2002_Hw: required-interface=CSDataServices_DID_0xe333_2002_Hw
      CBReadData_DID_0xe333_2002_Hv: required-interface=CSDataServices_DID_0xe333_2002_Hv
      CBReadData_DID_0xe314_DID_E314_Available_Torque_maximum: required-interface=CSDataServices_DID_0xe314_DID_E314_Available_Torque_maximum
      CBReadData_DID_0xeed4_DID_EED4_Safty_Function_Mode: required-interface=CSDataServices_DID_0xeed4_DID_EED4_Safty_Function_Mode
      CBReadData_DID_0xd003_DID_D003_Vehicle_Speed: required-interface=CSDataServices_DID_0xd003_DID_D003_Vehicle_Speed
      CBReadData_DID_0xe303_DID_E303_Motor_Speed_: required-interface=CSDataServices_DID_0xe303_DID_E303_Motor_Speed_
      CBReadData_DID_0xe353_DID_E353_Flux_weakening_correction_factor: required-interface=CSDataServices_DID_0xe353_DID_E353_Flux_weakening_correction_factor
      CBReadData_DID_0xe306_DID_E306_Motor_Temperature: required-interface=CSDataServices_DID_0xe306_DID_E306_Motor_Temperature
      CBReadData_DID_0xe363_DID_E363_Modulation_index: required-interface=CSDataServices_DID_0xe363_DID_E363_Modulation_index
      CBReadData_DID_0xe349_DID_E349_Phase_V_PWM_duty: required-interface=CSDataServices_DID_0xe349_DID_E349_Phase_V_PWM_duty
      CBReadData_DID_0xdd02_DID_DD02_Vehicle_Battery_Voltage: required-interface=CSDataServices_DID_0xdd02_DID_DD02_Vehicle_Battery_Voltage
      CBReadData_DTCTimeStamp21_DTCTimeStamp21: required-interface=CSDataServices_DTCTimeStamp21_DTCTimeStamp21
      CBReadData_DID_0xe347_DID_E347_IGBT_Max_Temperature: required-interface=CSDataServices_DID_0xe347_DID_E347_IGBT_Max_Temperature
      CBReadData_DID_0xeeb5_DID_EEB5_IEMMGM_current_torque: required-interface=CSDataServices_DID_0xeeb5_DID_EEB5_IEMMGM_current_torque
      CBReadData_DID_0xeebe_DID_EEBE_Offset_angle_status: required-interface=CSDataServices_DID_0xeebe_DID_EEBE_Offset_angle_status
      CBReadData_DID_0xe338_DID_E338_q_axis_current_feedback: required-interface=CSDataServices_DID_0xe338_DID_E338_q_axis_current_feedback
      CBReadData_DID_0xee9d_DID_EE9D_Transient_Phase_Current_B: required-interface=CSDataServices_DID_0xee9d_DID_EE9D_Transient_Phase_Current_B
      CBReadData_DID_0xe336_DID_E336_d_axis_current_feedback: required-interface=CSDataServices_DID_0xe336_DID_E336_d_axis_current_feedback
      CBReadData_DID_0xe348_DID_E348_Phase_U_PWM_duty: required-interface=CSDataServices_DID_0xe348_DID_E348_Phase_U_PWM_duty
      CBReadData_DID_0xe350_DID_E350_Phase_W_PWM_duty: required-interface=CSDataServices_DID_0xe350_DID_E350_Phase_W_PWM_duty
      CBReadData_DTCTimeStamp20_DTCTimeStamp20: required-interface=CSDataServices_DTCTimeStamp20_DTCTimeStamp20
      CBReadData_DID_0xe333_2002_H_Ser: required-interface=CSDataServices_DID_0xe333_2002_H_Ser
      CBReadData_DID_0xeec4_DID_EEC4_Charging_Power_Sustain_RelayCPSR_Voltage: required-interface=CSDataServices_DID_0xeec4_DID_EEC4_Charging_Power_Sustain_RelayCPSR_Voltage
      CBReadData_DID_0xe346_DID_E346_ECM_Torque_Allowed_Status: required-interface=CSDataServices_DID_0xe346_DID_E346_ECM_Torque_Allowed_Status
      CBReadData_DID_0xe313_DID_E313_Active_discharge_status: required-interface=CSDataServices_DID_0xe313_DID_E313_Active_discharge_status
      CBReadData_DID_0xe311_DID_E311_Crash_Status: required-interface=CSDataServices_DID_0xe311_DID_E311_Crash_Status
      CBReadData_DID_0xe300_DID_E300_HVDC_Voltage: required-interface=CSDataServices_DID_0xe300_DID_E300_HVDC_Voltage
      CBReadData_DID_0xe324_DID_E324_Motor_Derating_reason_of_IEMMGM: required-interface=CSDataServices_DID_0xe324_DID_E324_Motor_Derating_reason_of_IEMMGM
      CBReadData_DID_0xee9f_DID_EE9F_Gate_Status: required-interface=CSDataServices_DID_0xee9f_DID_EE9F_Gate_Status
      CBReadData_DID_0xe304_DID_E304_Actual_Torque: required-interface=CSDataServices_DID_0xe304_DID_E304_Actual_Torque
      CBReadData_DID_0xe315_DID_E315_Available_Torque_minimum: required-interface=CSDataServices_DID_0xe315_DID_E315_Available_Torque_minimum
      CBReadData_DID_0xeeb8_DID_EEB8_HV_voltage_received_from_BECM: required-interface=CSDataServices_DID_0xeeb8_DID_EEB8_HV_voltage_received_from_BECM
      CBReadData_DID_0xeed5_EED5_Safety_Torque_Quality_factor: required-interface=CSDataServices_DID_0xeed5_EED5_Safety_Torque_Quality_factor
      CBReadData_DID_0xe320_DID_E320_System_Mode_Mismatch: required-interface=CSDataServices_DID_0xe320_DID_E320_System_Mode_Mismatch
      CBReadData_DID_0xeeb7_DID_EEB7_ECM_Power_Limitation_minimum: required-interface=CSDataServices_DID_0xeeb7_DID_EEB7_ECM_Power_Limitation_minimum
      CBReadData_DID_0xe364_DID_E364_AURIX_Fault_Indication: required-interface=CSDataServices_DID_0xe364_DID_E364_AURIX_Fault_Indication
      CBReadData_DID_0xeed1_EED1_1: required-interface=CSDataServices_DID_0xeed1_EED1_1
      CBReadData_DID_0xeed1_EED1_0: required-interface=CSDataServices_DID_0xeed1_EED1_0
      CBReadData_DID_0xeed1_EED1_3: required-interface=CSDataServices_DID_0xeed1_EED1_3
      CBReadData_DID_0xeed1_EED1_2: required-interface=CSDataServices_DID_0xeed1_EED1_2
      CBReadData_DID_0xe312_DID_E312_Wheel_Speed: required-interface=CSDataServices_DID_0xe312_DID_E312_Wheel_Speed
      CBReadData_DID_0xe341_DID_E341_q_axis_voltage: required-interface=CSDataServices_DID_0xe341_DID_E341_q_axis_voltage
      CBReadData_DID_0xeed3_DID_EED3_Safety_speed: required-interface=CSDataServices_DID_0xeed3_DID_EED3_Safety_speed
      CBReadData_DID_0xee9c_DID_EE9C_Transient_Phase_Current_A: required-interface=CSDataServices_DID_0xee9c_DID_EE9C_Transient_Phase_Current_A
      CBReadData_DID_0xeed2_DID_EED2_SaftyTorque: required-interface=CSDataServices_DID_0xeed2_DID_EED2_SaftyTorque
      CBReadData_DID_0xdd01_DID_DD01_Total_Distance: required-interface=CSDataServices_DID_0xdd01_DID_DD01_Total_Distance
      CBReadData_DID_0xeebf_DID_EEBF_HV_Main_Relay_Status: required-interface=CSDataServices_DID_0xeebf_DID_EEBF_HV_Main_Relay_Status
      CBReadData_DID_0xe333_2002_L_Ser: required-interface=CSDataServices_DID_0xe333_2002_L_Ser
      CBReadData_DID_0xeeb2_DID_EEB2_Three_Phase_Motor_Current_RMS_Current: required-interface=CSDataServices_DID_0xeeb2_DID_EEB2_Three_Phase_Motor_Current_RMS_Current
      CBReadData_DID_0xe333_2002_Lw: required-interface=CSDataServices_DID_0xe333_2002_Lw
      CBReadData_DID_0xe333_2002_Lv: required-interface=CSDataServices_DID_0xe333_2002_Lv
      CBReadData_DID_0xee9a_DID_EE9A_Inverter_Coolant_Temperature: required-interface=CSDataServices_DID_0xee9a_DID_EE9A_Inverter_Coolant_Temperature
      CBReadData_DID_0xdd0c_DID_DD0C_Electric_Power_Level: required-interface=CSDataServices_DID_0xdd0c_DID_DD0C_Electric_Power_Level
      CBReadData_DID_0xe337_DID_E337_q_axis_current_setpoint: required-interface=CSDataServices_DID_0xe337_DID_E337_q_axis_current_setpoint
      CBReadData_DID_0xeeb6_DID_EEB6_ECM_Power_Limitation_maximum: required-interface=CSDataServices_DID_0xeeb6_DID_EEB6_ECM_Power_Limitation_maximum
      CBReadData_DID_0xe358_DID_E358_Resolve_angle: required-interface=CSDataServices_DID_0xe358_DID_E358_Resolve_angle
      CBReadData_DID_0xe333_2002_Lu: required-interface=CSDataServices_DID_0xe333_2002_Lu
    behavior DemSatellite_0InternalBehavior: handle-termination-and-restart=NO-SUPPORT, included-data-type-set=data-type=[Dem_EventIdType, Dem_RatioIdType, Dem_EventStatusType, Dem_UdsStatusByteType, Dem_DTCFormatType, Dem_InitMonitorReasonType, Dem_OperationCycleStateType, Dem_DTCStatusMaskType, Dem_IndicatorStatusType, Dem_MaxDataValueType, Dem_DTCKindType, Dem_DTCGroupType, Dem_IumprDenomCondIdType, Dem_IumprDenomCondStatusType, Dem_DebounceResetStatusType, Dem_DebouncingStateType, Dem_IumprReadinessGroupType, Dem_DTRControlType, Dem_DTCSeverityType, Dem_MonitorStatusType]
      timing event Timer_Dem_SatelliteMainFunction: start-on-event=Dem_SatelliteMainFunction, period=0.01
      4521 x operation invoked event:
        OpEventGetEventUdsStatus_GetEventUdsStatus_EvtInfo_VCEvBecmPropFr01Tioutd: start-on-event=DemSatellite_0InternalBehavior/GetEventUdsStatus, operation=EvtInfo_VCEvBecmPropFr01Tioutd.GetEventUdsStatus
        OpEventGetEventUdsStatus_GetEventUdsStatus_Event_VCEvBecmPropFr01Tioutd: start-on-event=DemSatellite_0InternalBehavior/GetEventUdsStatus, operation=Event_VCEvBecmPropFr01Tioutd.GetEventUdsStatus
        OpEventGetEventUdsStatus_GetEventUdsStatus_EvtInfo_INV_CU_TEMP2_RNG_NOK: start-on-event=DemSatellite_0InternalBehavior/GetEventUdsStatus, operation=EvtInfo_INV_CU_TEMP2_RNG_NOK.GetEventUdsStatus
        OpEventGetEventUdsStatus_GetEventUdsStatus_Event_INV_CU_TEMP2_RNG_NOK: start-on-event=DemSatellite_0InternalBehavior/GetEventUdsStatus, operation=Event_INV_CU_TEMP2_RNG_NOK.GetEventUdsStatus
        OpEventGetEventUdsStatus_GetEventUdsStatus_EvtInfo_INV_IMMO_NOKEY: start-on-event=DemSatellite_0InternalBehavior/GetEventUdsStatus, operation=EvtInfo_INV_IMMO_NOKEY.GetEventUdsStatus
        OpEventGetEventUdsStatus_GetEventUdsStatus_Event_INV_IMMO_NOKEY: start-on-event=DemSatellite_0InternalBehavior/GetEventUdsStatus, operation=Event_INV_IMMO_NOKEY.GetEventUdsStatus
        OpEventGetEventUdsStatus_GetEventUdsStatus_EvtInfo_INV_RSLVR_EXCT_OC_HWP: start-on-event=DemSatellite_0InternalBehavior/GetEventUdsStatus, operation=EvtInfo_INV_RSLVR_EXCT_OC_HWP.GetEventUdsStatus
        OpEventGetEventUdsStatus_GetEventUdsStatus_Event_INV_RSLVR_EXCT_OC_HWP: start-on-event=DemSatellite_0InternalBehavior/GetEventUdsStatus, operation=Event_INV_RSLVR_EXCT_OC_HWP.GetEventUdsStatus
        OpEventGetEventUdsStatus_GetEventUdsStatus_EvtInfo_PS_P15_W_FLT: start-on-event=DemSatellite_0InternalBehavior/GetEventUdsStatus, operation=EvtInfo_PS_P15_W_FLT.GetEventUdsStatus
        OpEventGetEventUdsStatus_GetEventUdsStatus_Event_PS_P15_W_FLT: start-on-event=DemSatellite_0InternalBehavior/GetEventUdsStatus, operation=Event_PS_P15_W_FLT.GetEventUdsStatus
        OpEventGetEventUdsStatus_GetEventUdsStatus_EvtInfo_INV_IAC_PLAUS_SUM: start-on-event=DemSatellite_0InternalBehavior/GetEventUdsStatus, operation=EvtInfo_INV_IAC_PLAUS_SUM.GetEventUdsStatus
        OpEventGetEventUdsStatus_GetEventUdsStatus_Event_INV_IAC_PLAUS_SUM: start-on-event=DemSatellite_0InternalBehavior/GetEventUdsStatus, operation=Event_INV_IAC_PLAUS_SUM.GetEventUdsStatus
        OpEventGetEventUdsStatus_GetEventUdsStatus_EvtInfo_PA_ELE_FLT: start-on-event=DemSatellite_0InternalBehavior/GetEventUdsStatus, operation=EvtInfo_PA_ELE_FLT.GetEventUdsStatus
        OpEventGetEventUdsStatus_GetEventUdsStatus_Event_PA_ELE_FLT: start-on-event=DemSatellite_0InternalBehavior/GetEventUdsStatus, operation=Event_PA_ELE_FLT.GetEventUdsStatus
        OpEventGetEventUdsStatus_GetEventUdsStatus_EvtInfo_CU_TEMP_GRDT: start-on-event=DemSatellite_0InternalBehavior/GetEventUdsStatus, operation=EvtInfo_CU_TEMP_GRDT.GetEventUdsStatus
        OpEventGetEventUdsStatus_GetEventUdsStatus_Event_CU_TEMP_GRDT: start-on-event=DemSatellite_0InternalBehavior/GetEventUdsStatus, operation=Event_CU_TEMP_GRDT.GetEventUdsStatus
        OpEventGetEventUdsStatus_GetEventUdsStatus_EvtInfo_INV_IGBT_TEMP_V_PLAUS: start-on-event=DemSatellite_0InternalBehavior/GetEventUdsStatus, operation=EvtInfo_INV_IGBT_TEMP_V_PLAUS.GetEventUdsStatus
        OpEventGetEventUdsStatus_GetEventUdsStatus_Event_INV_IGBT_TEMP_V_PLAUS: start-on-event=DemSatellite_0InternalBehavior/GetEventUdsStatus, operation=Event_INV_IGBT_TEMP_V_PLAUS.GetEventUdsStatus
        OpEventGetEventUdsStatus_GetEventUdsStatus_EvtInfo_Ga_GAEngageFailure: start-on-event=DemSatellite_0InternalBehavior/GetEventUdsStatus, operation=EvtInfo_Ga_GAEngageFailure.GetEventUdsStatus
        OpEventGetEventUdsStatus_GetEventUdsStatus_Event_Ga_GAEngageFailure: start-on-event=DemSatellite_0InternalBehavior/GetEventUdsStatus, operation=Event_Ga_GAEngageFailure.GetEventUdsStatus
        OpEventGetEventUdsStatus_GetEventUdsStatus_EvtInfo_INV_IAC_W_RNG_LO: start-on-event=DemSatellite_0InternalBehavior/GetEventUdsStatus, operation=EvtInfo_INV_IAC_W_RNG_LO.GetEventUdsStatus
        OpEventGetEventUdsStatus_GetEventUdsStatus_Event_INV_IAC_W_RNG_LO: start-on-event=DemSatellite_0InternalBehavior/GetEventUdsStatus, operation=Event_INV_IAC_W_RNG_LO.GetEventUdsStatus
        OpEventGetEventUdsStatus_GetEventUdsStatus_EvtInfo_PS_WhlSnsr_Vltg_FLT: start-on-event=DemSatellite_0InternalBehavior/GetEventUdsStatus, operation=EvtInfo_PS_WhlSnsr_Vltg_FLT.GetEventUdsStatus
        OpEventGetEventUdsStatus_GetEventUdsStatus_Event_PS_WhlSnsr_Vltg_FLT: start-on-event=DemSatellite_0InternalBehavior/GetEventUdsStatus, operation=Event_PS_WhlSnsr_Vltg_FLT.GetEventUdsStatus
        OpEventGetEventUdsStatus_GetEventUdsStatus_EvtInfo_VCEvEcmPropFr02Tioutd: start-on-event=DemSatellite_0InternalBehavior/GetEventUdsStatus, operation=EvtInfo_VCEvEcmPropFr02Tioutd.GetEventUdsStatus
        OpEventGetEventUdsStatus_GetEventUdsStatus_Event_VCEvEcmPropFr02Tioutd: start-on-event=DemSatellite_0InternalBehavior/GetEventUdsStatus, operation=Event_VCEvEcmPropFr02Tioutd.GetEventUdsStatus
        OpEventGetEventUdsStatus_GetEventUdsStatus_EvtInfo_Ga_TmSpdSyncFailed: start-on-event=DemSatellite_0InternalBehavior/GetEventUdsStatus, operation=EvtInfo_Ga_TmSpdSyncFailed.GetEventUdsStatus
        OpEventGetEventUdsStatus_GetEventUdsStatus_Event_Ga_TmSpdSyncFailed: start-on-event=DemSatellite_0InternalBehavior/GetEventUdsStatus, operation=Event_Ga_TmSpdSyncFailed.GetEventUdsStatus
        OpEventGetEventUdsStatus_GetEventUdsStatus_EvtInfo_INV_RSLVR_EXCT_ELEC_LO: start-on-event=DemSatellite_0InternalBehavior/GetEventUdsStatus, operation=EvtInfo_INV_RSLVR_EXCT_ELEC_LO.GetEventUdsStatus
        OpEventGetEventUdsStatus_GetEventUdsStatus_Event_INV_RSLVR_EXCT_ELEC_LO: start-on-event=DemSatellite_0InternalBehavior/GetEventUdsStatus, operation=Event_INV_RSLVR_EXCT_ELEC_LO.GetEventUdsStatus
        OpEventGetEventUdsStatus_GetEventUdsStatus_EvtInfo_VCEvEcmPropXevFr06Tioutd: start-on-event=DemSatellite_0InternalBehavior/GetEventUdsStatus, operation=EvtInfo_VCEvEcmPropXevFr06Tioutd.GetEventUdsStatus
        OpEventGetEventUdsStatus_GetEventUdsStatus_Event_VCEvEcmPropXevFr06Tioutd: start-on-event=DemSatellite_0InternalBehavior/GetEventUdsStatus, operation=Event_VCEvEcmPropXevFr06Tioutd.GetEventUdsStatus
        OpEventGetEventUdsStatus_GetEventUdsStatus_EvtInfo_VcEvCntrWhlMotSysTqAllwd: start-on-event=DemSatellite_0InternalBehavior/GetEventUdsStatus, operation=EvtInfo_VcEvCntrWhlMotSysTqAllwd.GetEventUdsStatus
        OpEventGetEventUdsStatus_GetEventUdsStatus_Event_VcEvCntrWhlMotSysTqAllwd: start-on-event=DemSatellite_0InternalBehavior/GetEventUdsStatus, operation=Event_VcEvCntrWhlMotSysTqAllwd.GetEventUdsStatus
        OpEventGetEventUdsStatus_GetEventUdsStatus_EvtInfo_INV_UHVDC_1_ELEC_HI: start-on-event=DemSatellite_0InternalBehavior/GetEventUdsStatus, operation=EvtInfo_INV_UHVDC_1_ELEC_HI.GetEventUdsStatus
        OpEventGetEventUdsStatus_GetEventUdsStatus_Event_INV_UHVDC_1_ELEC_HI: start-on-event=DemSatellite_0InternalBehavior/GetEventUdsStatus, operation=Event_INV_UHVDC_1_ELEC_HI.GetEventUdsStatus
        OpEventGetEventUdsStatus_GetEventUdsStatus_EvtInfo_INV_EM_STATOR_TEMP2_ELE_FLT: start-on-event=DemSatellite_0InternalBehavior/GetEventUdsStatus, operation=EvtInfo_INV_EM_STATOR_TEMP2_ELE_FLT.GetEventUdsStatus
        OpEventGetEventUdsStatus_GetEventUdsStatus_Event_INV_EM_STATOR_TEMP2_ELE_FLT: start-on-event=DemSatellite_0InternalBehavior/GetEventUdsStatus, operation=Event_INV_EM_STATOR_TEMP2_ELE_FLT.GetEventUdsStatus
        OpEventGetEventUdsStatus_GetEventUdsStatus_EvtInfo_AURIX_RST_SNG: start-on-event=DemSatellite_0InternalBehavior/GetEventUdsStatus, operation=EvtInfo_AURIX_RST_SNG.GetEventUdsStatus
        OpEventGetEventUdsStatus_GetEventUdsStatus_Event_AURIX_RST_SNG: start-on-event=DemSatellite_0InternalBehavior/GetEventUdsStatus, operation=Event_AURIX_RST_SNG.GetEventUdsStatus
        OpEventGetEventUdsStatus_GetEventUdsStatus_EvtInfo_VCEvEcmPropFr24MgmFr01Tioutd: start-on-event=DemSatellite_0InternalBehavior/GetEventUdsStatus, operation=EvtInfo_VCEvEcmPropFr24MgmFr01Tioutd.GetEventUdsStatus
        OpEventGetEventUdsStatus_GetEventUdsStatus_Event_VCEvEcmPropFr24MgmFr01Tioutd: start-on-event=DemSatellite_0InternalBehavior/GetEventUdsStatus, operation=Event_VCEvEcmPropFr24MgmFr01Tioutd.GetEventUdsStatus
        OpEventGetEventUdsStatus_GetEventUdsStatus_EvtInfo_INV_RSLVR_COS_ELEC_OPEN: start-on-event=DemSatellite_0InternalBehavior/GetEventUdsStatus, operation=EvtInfo_INV_RSLVR_COS_ELEC_OPEN.GetEventUdsStatus
        OpEventGetEventUdsStatus_GetEventUdsStatus_Event_INV_RSLVR_COS_ELEC_OPEN: start-on-event=DemSatellite_0InternalBehavior/GetEventUdsStatus, operation=Event_INV_RSLVR_COS_ELEC_OPEN.GetEventUdsStatus
        OpEventGetEventUdsStatus_GetEventUdsStatus_EvtInfo_INV_IAC_V_ELEC_LO: start-on-event=DemSatellite_0InternalBehavior/GetEventUdsStatus, operation=EvtInfo_INV_IAC_V_ELEC_LO.GetEventUdsStatus
        OpEventGetEventUdsStatus_GetEventUdsStatus_Event_INV_IAC_V_ELEC_LO: start-on-event=DemSatellite_0InternalBehavior/GetEventUdsStatus, operation=Event_INV_IAC_V_ELEC_LO.GetEventUdsStatus
        OpEventGetEventUdsStatus_GetEventUdsStatus_EvtInfo_INV_IAC_W_OFFS: start-on-event=DemSatellite_0InternalBehavior/GetEventUdsStatus, operation=EvtInfo_INV_IAC_W_OFFS.GetEventUdsStatus
        OpEventGetEventUdsStatus_GetEventUdsStatus_Event_INV_IAC_W_OFFS: start-on-event=DemSatellite_0InternalBehavior/GetEventUdsStatus, operation=Event_INV_IAC_W_OFFS.GetEventUdsStatus
        OpEventGetEventUdsStatus_GetEventUdsStatus_EvtInfo_INV_EM_STATOR_TEMP2_GRDT: start-on-event=DemSatellite_0InternalBehavior/GetEventUdsStatus, operation=EvtInfo_INV_EM_STATOR_TEMP2_GRDT.GetEventUdsStatus
        OpEventGetEventUdsStatus_GetEventUdsStatus_Event_INV_EM_STATOR_TEMP2_GRDT: start-on-event=DemSatellite_0InternalBehavior/GetEventUdsStatus, operation=Event_INV_EM_STATOR_TEMP2_GRDT.GetEventUdsStatus
        OpEventGetEventUdsStatus_GetEventUdsStatus_EvtInfo_INV_EM_OVRSPD_HWP: start-on-event=DemSatellite_0InternalBehavior/GetEventUdsStatus, operation=EvtInfo_INV_EM_OVRSPD_HWP.GetEventUdsStatus
        OpEventGetEventUdsStatus_GetEventUdsStatus_Event_INV_EM_OVRSPD_HWP: start-on-event=DemSatellite_0InternalBehavior/GetEventUdsStatus, operation=Event_INV_EM_OVRSPD_HWP.GetEventUdsStatus
        OpEventGetEventUdsStatus_GetEventUdsStatus_EvtInfo_CU_TEMP_HWP: start-on-event=DemSatellite_0InternalBehavior/GetEventUdsStatus, operation=EvtInfo_CU_TEMP_HWP.GetEventUdsStatus
        OpEventGetEventUdsStatus_GetEventUdsStatus_Event_CU_TEMP_HWP: start-on-event=DemSatellite_0InternalBehavior/GetEventUdsStatus, operation=Event_CU_TEMP_HWP.GetEventUdsStatus
        OpEventGetEventUdsStatus_GetEventUdsStatus_EvtInfo_INV_UHVDC_1_RNG_HI: start-on-event=DemSatellite_0InternalBehavior/GetEventUdsStatus, operation=EvtInfo_INV_UHVDC_1_RNG_HI.GetEventUdsStatus
        OpEventGetEventUdsStatus_GetEventUdsStatus_Event_INV_UHVDC_1_RNG_HI: start-on-event=DemSatellite_0InternalBehavior/GetEventUdsStatus, operation=Event_INV_UHVDC_1_RNG_HI.GetEventUdsStatus
        OpEventGetEventUdsStatus_GetEventUdsStatus_EvtInfo_VcEvEMPerfPlaus: start-on-event=DemSatellite_0InternalBehavior/GetEventUdsStatus, operation=EvtInfo_VcEvEMPerfPlaus.GetEventUdsStatus
        OpEventGetEventUdsStatus_GetEventUdsStatus_Event_VcEvEMPerfPlaus: start-on-event=DemSatellite_0InternalBehavior/GetEventUdsStatus, operation=Event_VcEvEMPerfPlaus.GetEventUdsStatus
        OpEventGetEventUdsStatus_GetEventUdsStatus_EvtInfo_VCEvVddmPropFr18Tioutd: start-on-event=DemSatellite_0InternalBehavior/GetEventUdsStatus, operation=EvtInfo_VCEvVddmPropFr18Tioutd.GetEventUdsStatus
        OpEventGetEventUdsStatus_GetEventUdsStatus_Event_VCEvVddmPropFr18Tioutd: start-on-event=DemSatellite_0InternalBehavior/GetEventUdsStatus, operation=Event_VCEvVddmPropFr18Tioutd.GetEventUdsStatus
        OpEventGetEventUdsStatus_GetEventUdsStatus_EvtInfo_INV_IAC_U_ELEC_HWP: start-on-event=DemSatellite_0InternalBehavior/GetEventUdsStatus, operation=EvtInfo_INV_IAC_U_ELEC_HWP.GetEventUdsStatus
        OpEventGetEventUdsStatus_GetEventUdsStatus_Event_INV_IAC_U_ELEC_HWP: start-on-event=DemSatellite_0InternalBehavior/GetEventUdsStatus, operation=Event_INV_IAC_U_ELEC_HWP.GetEventUdsStatus
        OpEventGetEventUdsStatus_GetEventUdsStatus_EvtInfo_VCEvVddmPropFr15Tioutd: start-on-event=DemSatellite_0InternalBehavior/GetEventUdsStatus, operation=EvtInfo_VCEvVddmPropFr15Tioutd.GetEventUdsStatus
        OpEventGetEventUdsStatus_GetEventUdsStatus_Event_VCEvVddmPropFr15Tioutd: start-on-event=DemSatellite_0InternalBehavior/GetEventUdsStatus, operation=Event_VCEvVddmPropFr15Tioutd.GetEventUdsStatus
        OpEventGetEventUdsStatus_GetEventUdsStatus_EvtInfo_Ga_GADisengageFailure: start-on-event=DemSatellite_0InternalBehavior/GetEventUdsStatus, operation=EvtInfo_Ga_GADisengageFailure.GetEventUdsStatus
        OpEventGetEventUdsStatus_GetEventUdsStatus_Event_Ga_GADisengageFailure: start-on-event=DemSatellite_0InternalBehavior/GetEventUdsStatus, operation=Event_Ga_GADisengageFailure.GetEventUdsStatus
        OpEventGetEventUdsStatus_GetEventUdsStatus_EvtInfo_CU_TEMP2_RNG_LO: start-on-event=DemSatellite_0InternalBehavior/GetEventUdsStatus, operation=EvtInfo_CU_TEMP2_RNG_LO.GetEventUdsStatus
        OpEventGetEventUdsStatus_GetEventUdsStatus_Event_CU_TEMP2_RNG_LO: start-on-event=DemSatellite_0InternalBehavior/GetEventUdsStatus, operation=Event_CU_TEMP2_RNG_LO.GetEventUdsStatus
        OpEventGetEventUdsStatus_GetEventUdsStatus_EvtInfo_INV_RSLVR_SIN_ELEC_OPEN: start-on-event=DemSatellite_0InternalBehavior/GetEventUdsStatus, operation=EvtInfo_INV_RSLVR_SIN_ELEC_OPEN.GetEventUdsStatus
        OpEventGetEventUdsStatus_GetEventUdsStatus_Event_INV_RSLVR_SIN_ELEC_OPEN: start-on-event=DemSatellite_0InternalBehavior/GetEventUdsStatus, operation=Event_INV_RSLVR_SIN_ELEC_OPEN.GetEventUdsStatus
        OpEventGetEventUdsStatus_GetEventUdsStatus_EvtInfo_VcEvChkSum: start-on-event=DemSatellite_0InternalBehavior/GetEventUdsStatus, operation=EvtInfo_VcEvChkSum.GetEventUdsStatus
        OpEventGetEventUdsStatus_GetEventUdsStatus_Event_VcEvChkSum: start-on-event=DemSatellite_0InternalBehavior/GetEventUdsStatus, operation=Event_VcEvChkSum.GetEventUdsStatus
        OpEventGetEventUdsStatus_GetEventUdsStatus_EvtInfo_PS_P5_UC_FLT: start-on-event=DemSatellite_0InternalBehavior/GetEventUdsStatus, operation=EvtInfo_PS_P5_UC_FLT.GetEventUdsStatus
        OpEventGetEventUdsStatus_GetEventUdsStatus_Event_PS_P5_UC_FLT: start-on-event=DemSatellite_0InternalBehavior/GetEventUdsStatus, operation=Event_PS_P5_UC_FLT.GetEventUdsStatus
        OpEventGetEventUdsStatus_GetEventUdsStatus_EvtInfo_INV_RSLVR_COS_ELEC_FLT: start-on-event=DemSatellite_0InternalBehavior/GetEventUdsStatus, operation=EvtInfo_INV_RSLVR_COS_ELEC_FLT.GetEventUdsStatus
        OpEventGetEventUdsStatus_GetEventUdsStatus_Event_INV_RSLVR_COS_ELEC_FLT: start-on-event=DemSatellite_0InternalBehavior/GetEventUdsStatus, operation=Event_INV_RSLVR_COS_ELEC_FLT.GetEventUdsStatus
        OpEventGetEventUdsStatus_GetEventUdsStatus_EvtInfo_INV_IAC_W_RNG_HI: start-on-event=DemSatellite_0InternalBehavior/GetEventUdsStatus, operation=EvtInfo_INV_IAC_W_RNG_HI.GetEventUdsStatus
        OpEventGetEventUdsStatus_GetEventUdsStatus_Event_INV_IAC_W_RNG_HI: start-on-event=DemSatellite_0InternalBehavior/GetEventUdsStatus, operation=Event_INV_IAC_W_RNG_HI.GetEventUdsStatus
        OpEventGetEventUdsStatus_GetEventUdsStatus_EvtInfo_PS_ECUSUPPLY_HIGH: start-on-event=DemSatellite_0InternalBehavior/GetEventUdsStatus, operation=EvtInfo_PS_ECUSUPPLY_HIGH.GetEventUdsStatus
        OpEventGetEventUdsStatus_GetEventUdsStatus_Event_PS_ECUSUPPLY_HIGH: start-on-event=DemSatellite_0InternalBehavior/GetEventUdsStatus, operation=Event_PS_ECUSUPPLY_HIGH.GetEventUdsStatus
        OpEventGetEventUdsStatus_GetEventUdsStatus_EvtInfo_VCEvEcmPropFr05Tioutd: start-on-event=DemSatellite_0InternalBehavior/GetEventUdsStatus, operation=EvtInfo_VCEvEcmPropFr05Tioutd.GetEventUdsStatus
        OpEventGetEventUdsStatus_GetEventUdsStatus_Event_VCEvEcmPropFr05Tioutd: start-on-event=DemSatellite_0InternalBehavior/GetEventUdsStatus, operation=Event_VCEvEcmPropFr05Tioutd.GetEventUdsStatus
        OpEventGetEventUdsStatus_GetEventUdsStatus_EvtInfo_PS_ECUSUPPLY_LOW: start-on-event=DemSatellite_0InternalBehavior/GetEventUdsStatus, operation=EvtInfo_PS_ECUSUPPLY_LOW.GetEventUdsStatus
        OpEventGetEventUdsStatus_GetEventUdsStatus_Event_PS_ECUSUPPLY_LOW: start-on-event=DemSatellite_0InternalBehavior/GetEventUdsStatus, operation=Event_PS_ECUSUPPLY_LOW.GetEventUdsStatus
        OpEventGetEventUdsStatus_GetEventUdsStatus_EvtInfo_VcEvChkSumHvSysRlySts: start-on-event=DemSatellite_0InternalBehavior/GetEventUdsStatus, operation=EvtInfo_VcEvChkSumHvSysRlySts.GetEventUdsStatus
        OpEventGetEventUdsStatus_GetEventUdsStatus_Event_VcEvChkSumHvSysRlySts: start-on-event=DemSatellite_0InternalBehavior/GetEventUdsStatus, operation=Event_VcEvChkSumHvSysRlySts.GetEventUdsStatus
        OpEventGetEventUdsStatus_GetEventUdsStatus_EvtInfo_VcEvMonMode: start-on-event=DemSatellite_0InternalBehavior/GetEventUdsStatus, operation=EvtInfo_VcEvMonMode.GetEventUdsStatus
        OpEventGetEventUdsStatus_GetEventUdsStatus_Event_VcEvMonMode: start-on-event=DemSatellite_0InternalBehavior/GetEventUdsStatus, operation=Event_VcEvMonMode.GetEventUdsStatus
        OpEventGetEventUdsStatus_GetEventUdsStatus_EvtInfo_INV_IAC_OC_SWP: start-on-event=DemSatellite_0InternalBehavior/GetEventUdsStatus, operation=EvtInfo_INV_IAC_OC_SWP.GetEventUdsStatus
        OpEventGetEventUdsStatus_GetEventUdsStatus_Event_INV_IAC_OC_SWP: start-on-event=DemSatellite_0InternalBehavior/GetEventUdsStatus, operation=Event_INV_IAC_OC_SWP.GetEventUdsStatus
        OpEventGetEventUdsStatus_GetEventUdsStatus_EvtInfo_INV_IMMO_AUTHFAIL: start-on-event=DemSatellite_0InternalBehavior/GetEventUdsStatus, operation=EvtInfo_INV_IMMO_AUTHFAIL.GetEventUdsStatus
        OpEventGetEventUdsStatus_GetEventUdsStatus_Event_INV_IMMO_AUTHFAIL: start-on-event=DemSatellite_0InternalBehavior/GetEventUdsStatus, operation=Event_INV_IMMO_AUTHFAIL.GetEventUdsStatus
        OpEventGetEventUdsStatus_GetEventUdsStatus_EvtInfo_PA_OpenCirc_FLT: start-on-event=DemSatellite_0InternalBehavior/GetEventUdsStatus, operation=EvtInfo_PA_OpenCirc_FLT.GetEventUdsStatus
        OpEventGetEventUdsStatus_GetEventUdsStatus_Event_PA_OpenCirc_FLT: start-on-event=DemSatellite_0InternalBehavior/GetEventUdsStatus, operation=Event_PA_OpenCirc_FLT.GetEventUdsStatus
        OpEventGetEventUdsStatus_GetEventUdsStatus_EvtInfo_INV_IAC_V_ELEC_HI: start-on-event=DemSatellite_0InternalBehavior/GetEventUdsStatus, operation=EvtInfo_INV_IAC_V_ELEC_HI.GetEventUdsStatus
        OpEventGetEventUdsStatus_GetEventUdsStatus_Event_INV_IAC_V_ELEC_HI: start-on-event=DemSatellite_0InternalBehavior/GetEventUdsStatus, operation=Event_INV_IAC_V_ELEC_HI.GetEventUdsStatus
        OpEventGetEventUdsStatus_GetEventUdsStatus_EvtInfo_VCEvEcmPropFr04Tioutd: start-on-event=DemSatellite_0InternalBehavior/GetEventUdsStatus, operation=EvtInfo_VCEvEcmPropFr04Tioutd.GetEventUdsStatus
        OpEventGetEventUdsStatus_GetEventUdsStatus_Event_VCEvEcmPropFr04Tioutd: start-on-event=DemSatellite_0InternalBehavior/GetEventUdsStatus, operation=Event_VCEvEcmPropFr04Tioutd.GetEventUdsStatus
        OpEventGetEventUdsStatus_GetEventUdsStatus_EvtInfo_VcEvMonTrqActPlaus: start-on-event=DemSatellite_0InternalBehavior/GetEventUdsStatus, operation=EvtInfo_VcEvMonTrqActPlaus.GetEventUdsStatus
        OpEventGetEventUdsStatus_GetEventUdsStatus_Event_VcEvMonTrqActPlaus: start-on-event=DemSatellite_0InternalBehavior/GetEventUdsStatus, operation=Event_VcEvMonTrqActPlaus.GetEventUdsStatus
        OpEventGetEventUdsStatus_GetEventUdsStatus_EvtInfo_VcEvMonTrqAct: start-on-event=DemSatellite_0InternalBehavior/GetEventUdsStatus, operation=EvtInfo_VcEvMonTrqAct.GetEventUdsStatus
        OpEventGetEventUdsStatus_GetEventUdsStatus_Event_VcEvMonTrqAct: start-on-event=DemSatellite_0InternalBehavior/GetEventUdsStatus, operation=Event_VcEvMonTrqAct.GetEventUdsStatus
        OpEventGetEventUdsStatus_GetEventUdsStatus_EvtInfo_INV_RSLVR_COS_ELEC_LO: start-on-event=DemSatellite_0InternalBehavior/GetEventUdsStatus, operation=EvtInfo_INV_RSLVR_COS_ELEC_LO.GetEventUdsStatus
